VERSION "HINBNNNYYNNNYYNNNNNNNNNNNNYNNNYYYNNYNNNNNN/4//%%/4/'%**4NNN///"

NS_ :

BS_:

BU_: VirtualNMTMaster Master_ID1 I_O_Device_2_ID11 I_O_Device_1_ID10

BO_ 1418 SSDO_010: 8 I_O_Device_1_ID10
 SG_ Write_Output_32_Bit16_6320_10 m16 : 32|32@1+ (1,0) [0|4294967295] "" Vector__XXX
 SG_ Write_Output_32_Bit15_6320_0F m15 : 32|32@1+ (1,0) [0|4294967295] "" Vector__XXX
 SG_ Write_Output_32_Bit14_6320_0E m14 : 32|32@1+ (1,0) [0|4294967295] "" Vector__XXX
 SG_ Write_Output_32_Bit13_6320_0D m13 : 32|32@1+ (1,0) [0|4294967295] "" Vector__XXX
 SG_ Write_Output_32_Bit12_6320_0C m12 : 32|32@1+ (1,0) [0|4294967295] "" Vector__XXX
 SG_ Write_Output_32_Bit11_6320_0B m11 : 32|32@1+ (1,0) [0|4294967295] "" Vector__XXX
 SG_ Write_Output_32_Bit10_6320_0A m10 : 32|32@1+ (1,0) [0|4294967295] "" Vector__XXX
 SG_ Write_Output_32_Bit9_6320_09 m9 : 32|32@1+ (1,0) [0|4294967295] "" Vector__XXX
 SG_ Write_Output_32_Bit8_6320_08 m8 : 32|32@1+ (1,0) [0|4294967295] "" Vector__XXX
 SG_ Write_Output_32_Bit7_6320_07 m7 : 32|32@1+ (1,0) [0|4294967295] "" Vector__XXX
 SG_ Write_Output_32_Bit6_6320_06 m6 : 32|32@1+ (1,0) [0|4294967295] "" Vector__XXX
 SG_ Write_Output_32_Bit5_6320_05 m5 : 32|32@1+ (1,0) [0|4294967295] "" Vector__XXX
 SG_ Write_Output_32_Bit4_6320_04 m4 : 32|32@1+ (1,0) [0|4294967295] "" Vector__XXX
 SG_ Write_Output_32_Bit3_6320_03 m3 : 32|32@1+ (1,0) [0|4294967295] "" Vector__XXX
 SG_ Write_Output_32_Bit2_6320_02 m2 : 32|32@1+ (1,0) [0|4294967295] "" Vector__XXX
 SG_ Write_Output_32_Bit1_6320_01 m1 : 32|32@1+ (1,0) [0|4294967295] "" Vector__XXX
 SG_ NrOfObjects_6320_00 m0 : 32|8@1+ (1,0) [0|255] "" Vector__XXX
 SG_ SubIndex_6320 m25376M : 24|8@1+ (1,0) [0|16] "" Vector__XXX
 SG_ Write_Output_16_Bit16_6300_10 m16 : 32|16@1+ (1,0) [0|65535] "" Vector__XXX
 SG_ Write_Output_16_Bit15_6300_0F m15 : 32|16@1+ (1,0) [0|65535] "" Vector__XXX
 SG_ Write_Output_16_Bit14_6300_0E m14 : 32|16@1+ (1,0) [0|65535] "" Vector__XXX
 SG_ Write_Output_16_Bit13_6300_0D m13 : 32|16@1+ (1,0) [0|65535] "" Vector__XXX
 SG_ Write_Output_16_Bit12_6300_0C m12 : 32|16@1+ (1,0) [0|65535] "" Vector__XXX
 SG_ Write_Output_16_Bit11_6300_0B m11 : 32|16@1+ (1,0) [0|65535] "" Vector__XXX
 SG_ Write_Output_16_Bit10_6300_0A m10 : 32|16@1+ (1,0) [0|65535] "" Vector__XXX
 SG_ Write_Output_16_Bit9_6300_09 m9 : 32|16@1+ (1,0) [0|65535] "" Vector__XXX
 SG_ Write_Output_16_Bit8_6300_08 m8 : 32|16@1+ (1,0) [0|65535] "" Vector__XXX
 SG_ Write_Output_16_Bit7_6300_07 m7 : 32|16@1+ (1,0) [0|65535] "" Vector__XXX
 SG_ Write_Output_16_Bit6_6300_06 m6 : 32|16@1+ (1,0) [0|65535] "" Vector__XXX
 SG_ Write_Output_16_Bit5_6300_05 m5 : 32|16@1+ (1,0) [0|65535] "" Vector__XXX
 SG_ Write_Output_16_Bit4_6300_04 m4 : 32|16@1+ (1,0) [0|65535] "" Vector__XXX
 SG_ Write_Output_16_Bit3_6300_03 m3 : 32|16@1+ (1,0) [0|65535] "" Vector__XXX
 SG_ Write_Output_16_Bit2_6300_02 m2 : 32|16@1+ (1,0) [0|65535] "" Vector__XXX
 SG_ Write_Output_16_Bit1_6300_01 m1 : 32|16@1+ (1,0) [0|65535] "" Vector__XXX
 SG_ NrOfObjects_6300_00 m0 : 32|8@1+ (1,0) [0|255] "" Vector__XXX
 SG_ SubIndex_6300 m25344M : 24|8@1+ (1,0) [0|16] "" Vector__XXX
 SG_ Write_Output_1_Bit64_6220_40 m64 : 32|1@1+ (1,0) [0|1] "" Vector__XXX
 SG_ Write_Output_1_Bit63_6220_3F m63 : 32|1@1+ (1,0) [0|1] "" Vector__XXX
 SG_ Write_Output_1_Bit62_6220_3E m62 : 32|1@1+ (1,0) [0|1] "" Vector__XXX
 SG_ Write_Output_1_Bit61_6220_3D m61 : 32|1@1+ (1,0) [0|1] "" Vector__XXX
 SG_ Write_Output_1_Bit60_6220_3C m60 : 32|1@1+ (1,0) [0|1] "" Vector__XXX
 SG_ Write_Output_1_Bit59_6220_3B m59 : 32|1@1+ (1,0) [0|1] "" Vector__XXX
 SG_ Write_Output_1_Bit58_6220_3A m58 : 32|1@1+ (1,0) [0|1] "" Vector__XXX
 SG_ Write_Output_1_Bit57_6220_39 m57 : 32|1@1+ (1,0) [0|1] "" Vector__XXX
 SG_ Write_Output_1_Bit56_6220_38 m56 : 32|1@1+ (1,0) [0|1] "" Vector__XXX
 SG_ Write_Output_1_Bit55_6220_37 m55 : 32|1@1+ (1,0) [0|1] "" Vector__XXX
 SG_ Write_Output_1_Bit54_6220_36 m54 : 32|1@1+ (1,0) [0|1] "" Vector__XXX
 SG_ Write_Output_1_Bit53_6220_35 m53 : 32|1@1+ (1,0) [0|1] "" Vector__XXX
 SG_ Write_Output_1_Bit52_6220_34 m52 : 32|1@1+ (1,0) [0|1] "" Vector__XXX
 SG_ Write_Output_1_Bit51_6220_33 m51 : 32|1@1+ (1,0) [0|1] "" Vector__XXX
 SG_ Write_Output_1_Bit50_6220_32 m50 : 32|1@1+ (1,0) [0|1] "" Vector__XXX
 SG_ Write_Output_1_Bit49_6220_31 m49 : 32|1@1+ (1,0) [0|1] "" Vector__XXX
 SG_ Write_Output_1_Bit48_6220_30 m48 : 32|1@1+ (1,0) [0|1] "" Vector__XXX
 SG_ Write_Output_1_Bit47_6220_2F m47 : 32|1@1+ (1,0) [0|1] "" Vector__XXX
 SG_ Write_Output_1_Bit46_6220_2E m46 : 32|1@1+ (1,0) [0|1] "" Vector__XXX
 SG_ Write_Output_1_Bit45_6220_2D m45 : 32|1@1+ (1,0) [0|1] "" Vector__XXX
 SG_ Write_Output_1_Bit44_6220_2C m44 : 32|1@1+ (1,0) [0|1] "" Vector__XXX
 SG_ Write_Output_1_Bit43_6220_2B m43 : 32|1@1+ (1,0) [0|1] "" Vector__XXX
 SG_ Write_Output_1_Bit42_6220_2A m42 : 32|1@1+ (1,0) [0|1] "" Vector__XXX
 SG_ Write_Output_1_Bit41_6220_29 m41 : 32|1@1+ (1,0) [0|1] "" Vector__XXX
 SG_ Write_Output_1_Bit40_6220_28 m40 : 32|1@1+ (1,0) [0|1] "" Vector__XXX
 SG_ Write_Output_1_Bit39_6220_27 m39 : 32|1@1+ (1,0) [0|1] "" Vector__XXX
 SG_ Write_Output_1_Bit38_6220_26 m38 : 32|1@1+ (1,0) [0|1] "" Vector__XXX
 SG_ Write_Output_1_Bit37_6220_25 m37 : 32|1@1+ (1,0) [0|1] "" Vector__XXX
 SG_ Write_Output_1_Bit36_6220_24 m36 : 32|1@1+ (1,0) [0|1] "" Vector__XXX
 SG_ Write_Output_1_Bit35_6220_23 m35 : 32|1@1+ (1,0) [0|1] "" Vector__XXX
 SG_ Write_Output_1_Bit34_6220_22 m34 : 32|1@1+ (1,0) [0|1] "" Vector__XXX
 SG_ Write_Output_1_Bit33_6220_21 m33 : 32|1@1+ (1,0) [0|1] "" Vector__XXX
 SG_ Write_Output_1_Bit32_6220_20 m32 : 32|1@1+ (1,0) [0|1] "" Vector__XXX
 SG_ Write_Output_1_Bit31_6220_1F m31 : 32|1@1+ (1,0) [0|1] "" Vector__XXX
 SG_ Write_Output_1_Bit30_6220_1E m30 : 32|1@1+ (1,0) [0|1] "" Vector__XXX
 SG_ Write_Output_1_Bit29_6220_1D m29 : 32|1@1+ (1,0) [0|1] "" Vector__XXX
 SG_ Write_Output_1_Bit28_6220_1C m28 : 32|1@1+ (1,0) [0|1] "" Vector__XXX
 SG_ Write_Output_1_Bit27_6220_1B m27 : 32|1@1+ (1,0) [0|1] "" Vector__XXX
 SG_ Write_Output_1_Bit26_6220_1A m26 : 32|1@1+ (1,0) [0|1] "" Vector__XXX
 SG_ Write_Output_1_Bit25_6220_19 m25 : 32|1@1+ (1,0) [0|1] "" Vector__XXX
 SG_ Write_Output_1_Bit24_6220_18 m24 : 32|1@1+ (1,0) [0|1] "" Vector__XXX
 SG_ Write_Output_1_Bit23_6220_17 m23 : 32|1@1+ (1,0) [0|1] "" Vector__XXX
 SG_ Write_Output_1_Bit22_6220_16 m22 : 32|1@1+ (1,0) [0|1] "" Vector__XXX
 SG_ Write_Output_1_Bit21_6220_15 m21 : 32|1@1+ (1,0) [0|1] "" Vector__XXX
 SG_ Write_Output_1_Bit20_6220_14 m20 : 32|1@1+ (1,0) [0|1] "" Vector__XXX
 SG_ Write_Output_1_Bit19_6220_13 m19 : 32|1@1+ (1,0) [0|1] "" Vector__XXX
 SG_ Write_Output_1_Bit18_6220_12 m18 : 32|1@1+ (1,0) [0|1] "" Vector__XXX
 SG_ Write_Output_1_Bit17_6220_11 m17 : 32|1@1+ (1,0) [0|1] "" Vector__XXX
 SG_ Write_Output_1_Bit16_6220_10 m16 : 32|1@1+ (1,0) [0|1] "" Vector__XXX
 SG_ Write_Output_1_Bit15_6220_0F m15 : 32|1@1+ (1,0) [0|1] "" Vector__XXX
 SG_ Write_Output_1_Bit14_6220_0E m14 : 32|1@1+ (1,0) [0|1] "" Vector__XXX
 SG_ Write_Output_1_Bit13_6220_0D m13 : 32|1@1+ (1,0) [0|1] "" Vector__XXX
 SG_ Write_Output_1_Bit12_6220_0C m12 : 32|1@1+ (1,0) [0|1] "" Vector__XXX
 SG_ Write_Output_1_Bit11_6220_0B m11 : 32|1@1+ (1,0) [0|1] "" Vector__XXX
 SG_ Write_Output_1_Bit10_6220_0A m10 : 32|1@1+ (1,0) [0|1] "" Vector__XXX
 SG_ Write_Output_1_Bit9_6220_09 m9 : 32|1@1+ (1,0) [0|1] "" Vector__XXX
 SG_ Write_Output_1_Bit8_6220_08 m8 : 32|1@1+ (1,0) [0|1] "" Vector__XXX
 SG_ Write_Output_1_Bit7_6220_07 m7 : 32|1@1+ (1,0) [0|1] "" Vector__XXX
 SG_ Write_Output_1_Bit6_6220_06 m6 : 32|1@1+ (1,0) [0|1] "" Vector__XXX
 SG_ Write_Output_1_Bit5_6220_05 m5 : 32|1@1+ (1,0) [0|1] "" Vector__XXX
 SG_ Write_Output_1_Bit4_6220_04 m4 : 32|1@1+ (1,0) [0|1] "" Vector__XXX
 SG_ Write_Output_1_Bit3_6220_03 m3 : 32|1@1+ (1,0) [0|1] "" Vector__XXX
 SG_ Write_Output_1_Bit2_6220_02 m2 : 32|1@1+ (1,0) [0|1] "" Vector__XXX
 SG_ Write_Output_1_Bit1_6220_01 m1 : 32|1@1+ (1,0) [0|1] "" Vector__XXX
 SG_ NrOfObjects_6220_00 m0 : 32|8@1+ (1,0) [0|255] "" Vector__XXX
 SG_ SubIndex_6220 m25120M : 24|8@1+ (1,0) [0|64] "" Vector__XXX
 SG_ Write_Output_8_Bit16_6200_10 m16 : 32|8@1+ (1,0) [0|255] "" Vector__XXX
 SG_ Write_Output_8_Bit15_6200_0F m15 : 32|8@1+ (1,0) [0|255] "" Vector__XXX
 SG_ Write_Output_8_Bit14_6200_0E m14 : 32|8@1+ (1,0) [0|255] "" Vector__XXX
 SG_ Write_Output_8_Bit13_6200_0D m13 : 32|8@1+ (1,0) [0|255] "" Vector__XXX
 SG_ Write_Output_8_Bit12_6200_0C m12 : 32|8@1+ (1,0) [0|255] "" Vector__XXX
 SG_ Write_Output_8_Bit11_6200_0B m11 : 32|8@1+ (1,0) [0|255] "" Vector__XXX
 SG_ Write_Output_8_Bit10_6200_0A m10 : 32|8@1+ (1,0) [0|255] "" Vector__XXX
 SG_ Write_Output_8_Bit9_6200_09 m9 : 32|8@1+ (1,0) [0|255] "" Vector__XXX
 SG_ Write_Output_8_Bit8_6200_08 m8 : 32|8@1+ (1,0) [0|255] "" Vector__XXX
 SG_ Write_Output_8_Bit7_6200_07 m7 : 32|8@1+ (1,0) [0|255] "" Vector__XXX
 SG_ Write_Output_8_Bit6_6200_06 m6 : 32|8@1+ (1,0) [0|255] "" Vector__XXX
 SG_ Write_Output_8_Bit5_6200_05 m5 : 32|8@1+ (1,0) [0|255] "" Vector__XXX
 SG_ Write_Output_8_Bit4_6200_04 m4 : 32|8@1+ (1,0) [0|255] "" Vector__XXX
 SG_ Write_Output_8_Bit3_6200_03 m3 : 32|8@1+ (1,0) [0|255] "" Vector__XXX
 SG_ Write_Output_8_Bit2_6200_02 m2 : 32|8@1+ (1,0) [0|255] "" Vector__XXX
 SG_ Write_Output_8_Bit1_6200_01 m1 : 32|8@1+ (1,0) [0|255] "" Vector__XXX
 SG_ NrOfObjects_6200_00 m0 : 32|8@1+ (1,0) [0|255] "" Vector__XXX
 SG_ SubIndex_6200 m25088M : 24|8@1+ (1,0) [0|16] "" Vector__XXX
 SG_ Read_Input_32_Bit16_6120_10 m16 : 32|32@1+ (1,0) [0|4294967295] "" Vector__XXX
 SG_ Read_Input_32_Bit15_6120_0F m15 : 32|32@1+ (1,0) [0|4294967295] "" Vector__XXX
 SG_ Read_Input_32_Bit14_6120_0E m14 : 32|32@1+ (1,0) [0|4294967295] "" Vector__XXX
 SG_ Read_Input_32_Bit13_6120_0D m13 : 32|32@1+ (1,0) [0|4294967295] "" Vector__XXX
 SG_ Read_Input_32_Bit12_6120_0C m12 : 32|32@1+ (1,0) [0|4294967295] "" Vector__XXX
 SG_ Read_Input_32_Bit11_6120_0B m11 : 32|32@1+ (1,0) [0|4294967295] "" Vector__XXX
 SG_ Read_Input_32_Bit10_6120_0A m10 : 32|32@1+ (1,0) [0|4294967295] "" Vector__XXX
 SG_ Read_Input_32_Bit9_6120_09 m9 : 32|32@1+ (1,0) [0|4294967295] "" Vector__XXX
 SG_ Read_Input_32_Bit8_6120_08 m8 : 32|32@1+ (1,0) [0|4294967295] "" Vector__XXX
 SG_ Read_Input_32_Bit7_6120_07 m7 : 32|32@1+ (1,0) [0|4294967295] "" Vector__XXX
 SG_ Read_Input_32_Bit6_6120_06 m6 : 32|32@1+ (1,0) [0|4294967295] "" Vector__XXX
 SG_ Read_Input_32_Bit5_6120_05 m5 : 32|32@1+ (1,0) [0|4294967295] "" Vector__XXX
 SG_ Read_Input_32_Bit4_6120_04 m4 : 32|32@1+ (1,0) [0|4294967295] "" Vector__XXX
 SG_ Read_Input_32_Bit3_6120_03 m3 : 32|32@1+ (1,0) [0|4294967295] "" Vector__XXX
 SG_ Read_Input_32_Bit2_6120_02 m2 : 32|32@1+ (1,0) [0|4294967295] "" Vector__XXX
 SG_ Read_Input_32_Bit1_6120_01 m1 : 32|32@1+ (1,0) [0|4294967295] "" Vector__XXX
 SG_ NrOfObjects_6120_00 m0 : 32|8@1+ (1,0) [0|255] "" Vector__XXX
 SG_ SubIndex_6120 m24864M : 24|8@1+ (1,0) [0|16] "" Vector__XXX
 SG_ Read_Input_16_Bit16_6100_10 m16 : 32|16@1+ (1,0) [0|65535] "" Vector__XXX
 SG_ Read_Input_16_Bit15_6100_0F m15 : 32|16@1+ (1,0) [0|65535] "" Vector__XXX
 SG_ Read_Input_16_Bit14_6100_0E m14 : 32|16@1+ (1,0) [0|65535] "" Vector__XXX
 SG_ Read_Input_16_Bit13_6100_0D m13 : 32|16@1+ (1,0) [0|65535] "" Vector__XXX
 SG_ Read_Input_16_Bit12_6100_0C m12 : 32|16@1+ (1,0) [0|65535] "" Vector__XXX
 SG_ Read_Input_16_Bit11_6100_0B m11 : 32|16@1+ (1,0) [0|65535] "" Vector__XXX
 SG_ Read_Input_16_Bit10_6100_0A m10 : 32|16@1+ (1,0) [0|65535] "" Vector__XXX
 SG_ Read_Input_16_Bit9_6100_09 m9 : 32|16@1+ (1,0) [0|65535] "" Vector__XXX
 SG_ Read_Input_16_Bit8_6100_08 m8 : 32|16@1+ (1,0) [0|65535] "" Vector__XXX
 SG_ Read_Input_16_Bit7_6100_07 m7 : 32|16@1+ (1,0) [0|65535] "" Vector__XXX
 SG_ Read_Input_16_Bit6_6100_06 m6 : 32|16@1+ (1,0) [0|65535] "" Vector__XXX
 SG_ Read_Input_16_Bit5_6100_05 m5 : 32|16@1+ (1,0) [0|65535] "" Vector__XXX
 SG_ Read_Input_16_Bit4_6100_04 m4 : 32|16@1+ (1,0) [0|65535] "" Vector__XXX
 SG_ Read_Input_16_Bit3_6100_03 m3 : 32|16@1+ (1,0) [0|65535] "" Vector__XXX
 SG_ Read_Input_16_Bit2_6100_02 m2 : 32|16@1+ (1,0) [0|65535] "" Vector__XXX
 SG_ Read_Input_16_Bit1_6100_01 m1 : 32|16@1+ (1,0) [0|65535] "" Vector__XXX
 SG_ NrOfObjects_6100_00 m0 : 32|8@1+ (1,0) [0|255] "" Vector__XXX
 SG_ SubIndex_6100 m24832M : 24|8@1+ (1,0) [0|16] "" Vector__XXX
 SG_ Read_Input_1_Bit64_6020_40 m64 : 32|1@1+ (1,0) [0|1] "" Vector__XXX
 SG_ Read_Input_1_Bit63_6020_3F m63 : 32|1@1+ (1,0) [0|1] "" Vector__XXX
 SG_ Read_Input_1_Bit62_6020_3E m62 : 32|1@1+ (1,0) [0|1] "" Vector__XXX
 SG_ Read_Input_1_Bit61_6020_3D m61 : 32|1@1+ (1,0) [0|1] "" Vector__XXX
 SG_ Read_Input_1_Bit60_6020_3C m60 : 32|1@1+ (1,0) [0|1] "" Vector__XXX
 SG_ Read_Input_1_Bit59_6020_3B m59 : 32|1@1+ (1,0) [0|1] "" Vector__XXX
 SG_ Read_Input_1_Bit58_6020_3A m58 : 32|1@1+ (1,0) [0|1] "" Vector__XXX
 SG_ Read_Input_1_Bit57_6020_39 m57 : 32|1@1+ (1,0) [0|1] "" Vector__XXX
 SG_ Read_Input_1_Bit56_6020_38 m56 : 32|1@1+ (1,0) [0|1] "" Vector__XXX
 SG_ Read_Input_1_Bit55_6020_37 m55 : 32|1@1+ (1,0) [0|1] "" Vector__XXX
 SG_ Read_Input_1_Bit54_6020_36 m54 : 32|1@1+ (1,0) [0|1] "" Vector__XXX
 SG_ Read_Input_1_Bit53_6020_35 m53 : 32|1@1+ (1,0) [0|1] "" Vector__XXX
 SG_ Read_Input_1_Bit52_6020_34 m52 : 32|1@1+ (1,0) [0|1] "" Vector__XXX
 SG_ Read_Input_1_Bit51_6020_33 m51 : 32|1@1+ (1,0) [0|1] "" Vector__XXX
 SG_ Read_Input_1_Bit50_6020_32 m50 : 32|1@1+ (1,0) [0|1] "" Vector__XXX
 SG_ Read_Input_1_Bit49_6020_31 m49 : 32|1@1+ (1,0) [0|1] "" Vector__XXX
 SG_ Read_Input_1_Bit48_6020_30 m48 : 32|1@1+ (1,0) [0|1] "" Vector__XXX
 SG_ Read_Input_1_Bit47_6020_2F m47 : 32|1@1+ (1,0) [0|1] "" Vector__XXX
 SG_ Read_Input_1_Bit46_6020_2E m46 : 32|1@1+ (1,0) [0|1] "" Vector__XXX
 SG_ Read_Input_1_Bit45_6020_2D m45 : 32|1@1+ (1,0) [0|1] "" Vector__XXX
 SG_ Read_Input_1_Bit44_6020_2C m44 : 32|1@1+ (1,0) [0|1] "" Vector__XXX
 SG_ Read_Input_1_Bit43_6020_2B m43 : 32|1@1+ (1,0) [0|1] "" Vector__XXX
 SG_ Read_Input_1_Bit42_6020_2A m42 : 32|1@1+ (1,0) [0|1] "" Vector__XXX
 SG_ Read_Input_1_Bit41_6020_29 m41 : 32|1@1+ (1,0) [0|1] "" Vector__XXX
 SG_ Read_Input_1_Bit40_6020_28 m40 : 32|1@1+ (1,0) [0|1] "" Vector__XXX
 SG_ Read_Input_1_Bit39_6020_27 m39 : 32|1@1+ (1,0) [0|1] "" Vector__XXX
 SG_ Read_Input_1_Bit38_6020_26 m38 : 32|1@1+ (1,0) [0|1] "" Vector__XXX
 SG_ Read_Input_1_Bit37_6020_25 m37 : 32|1@1+ (1,0) [0|1] "" Vector__XXX
 SG_ Read_Input_1_Bit36_6020_24 m36 : 32|1@1+ (1,0) [0|1] "" Vector__XXX
 SG_ Read_Input_1_Bit35_6020_23 m35 : 32|1@1+ (1,0) [0|1] "" Vector__XXX
 SG_ Read_Input_1_Bit34_6020_22 m34 : 32|1@1+ (1,0) [0|1] "" Vector__XXX
 SG_ Read_Input_1_Bit33_6020_21 m33 : 32|1@1+ (1,0) [0|1] "" Vector__XXX
 SG_ Read_Input_1_Bit32_6020_20 m32 : 32|1@1+ (1,0) [0|1] "" Vector__XXX
 SG_ Read_Input_1_Bit31_6020_1F m31 : 32|1@1+ (1,0) [0|1] "" Vector__XXX
 SG_ Read_Input_1_Bit30_6020_1E m30 : 32|1@1+ (1,0) [0|1] "" Vector__XXX
 SG_ Read_Input_1_Bit29_6020_1D m29 : 32|1@1+ (1,0) [0|1] "" Vector__XXX
 SG_ Read_Input_1_Bit28_6020_1C m28 : 32|1@1+ (1,0) [0|1] "" Vector__XXX
 SG_ Read_Input_1_Bit27_6020_1B m27 : 32|1@1+ (1,0) [0|1] "" Vector__XXX
 SG_ Read_Input_1_Bit26_6020_1A m26 : 32|1@1+ (1,0) [0|1] "" Vector__XXX
 SG_ Read_Input_1_Bit25_6020_19 m25 : 32|1@1+ (1,0) [0|1] "" Vector__XXX
 SG_ Read_Input_1_Bit24_6020_18 m24 : 32|1@1+ (1,0) [0|1] "" Vector__XXX
 SG_ Read_Input_1_Bit23_6020_17 m23 : 32|1@1+ (1,0) [0|1] "" Vector__XXX
 SG_ Read_Input_1_Bit22_6020_16 m22 : 32|1@1+ (1,0) [0|1] "" Vector__XXX
 SG_ Read_Input_1_Bit21_6020_15 m21 : 32|1@1+ (1,0) [0|1] "" Vector__XXX
 SG_ Read_Input_1_Bit20_6020_14 m20 : 32|1@1+ (1,0) [0|1] "" Vector__XXX
 SG_ Read_Input_1_Bit19_6020_13 m19 : 32|1@1+ (1,0) [0|1] "" Vector__XXX
 SG_ Read_Input_1_Bit18_6020_12 m18 : 32|1@1+ (1,0) [0|1] "" Vector__XXX
 SG_ Read_Input_1_Bit17_6020_11 m17 : 32|1@1+ (1,0) [0|1] "" Vector__XXX
 SG_ Read_Input_1_Bit16_6020_10 m16 : 32|1@1+ (1,0) [0|1] "" Vector__XXX
 SG_ Read_Input_1_Bit15_6020_0F m15 : 32|1@1+ (1,0) [0|1] "" Vector__XXX
 SG_ Read_Input_1_Bit14_6020_0E m14 : 32|1@1+ (1,0) [0|1] "" Vector__XXX
 SG_ Read_Input_1_Bit13_6020_0D m13 : 32|1@1+ (1,0) [0|1] "" Vector__XXX
 SG_ Read_Input_1_Bit12_6020_0C m12 : 32|1@1+ (1,0) [0|1] "" Vector__XXX
 SG_ Read_Input_1_Bit11_6020_0B m11 : 32|1@1+ (1,0) [0|1] "" Vector__XXX
 SG_ Read_Input_1_Bit10_6020_0A m10 : 32|1@1+ (1,0) [0|1] "" Vector__XXX
 SG_ Read_Input_1_Bit9_6020_09 m9 : 32|1@1+ (1,0) [0|1] "" Vector__XXX
 SG_ Read_Input_1_Bit8_6020_08 m8 : 32|1@1+ (1,0) [0|1] "" Vector__XXX
 SG_ Read_Input_1_Bit7_6020_07 m7 : 32|1@1+ (1,0) [0|1] "" Vector__XXX
 SG_ Read_Input_1_Bit6_6020_06 m6 : 32|1@1+ (1,0) [0|1] "" Vector__XXX
 SG_ Read_Input_1_Bit5_6020_05 m5 : 32|1@1+ (1,0) [0|1] "" Vector__XXX
 SG_ Read_Input_1_Bit4_6020_04 m4 : 32|1@1+ (1,0) [0|1] "" Vector__XXX
 SG_ Read_Input_1_Bit3_6020_03 m3 : 32|1@1+ (1,0) [0|1] "" Vector__XXX
 SG_ Read_Input_1_Bit2_6020_02 m2 : 32|1@1+ (1,0) [0|1] "" Vector__XXX
 SG_ Read_Input_1_Bit1_6020_01 m1 : 32|1@1+ (1,0) [0|1] "" Vector__XXX
 SG_ NrOfObjects_6020_00 m0 : 32|8@1+ (1,0) [0|255] "" Vector__XXX
 SG_ SubIndex_6020 m24608M : 24|8@1+ (1,0) [0|64] "" Vector__XXX
 SG_ Read_Input_8_Bit16_6000_10 m16 : 32|8@1+ (1,0) [0|255] "" Vector__XXX
 SG_ Read_Input_8_Bit15_6000_0F m15 : 32|8@1+ (1,0) [0|255] "" Vector__XXX
 SG_ Read_Input_8_Bit14_6000_0E m14 : 32|8@1+ (1,0) [0|255] "" Vector__XXX
 SG_ Read_Input_8_Bit13_6000_0D m13 : 32|8@1+ (1,0) [0|255] "" Vector__XXX
 SG_ Read_Input_8_Bit12_6000_0C m12 : 32|8@1+ (1,0) [0|255] "" Vector__XXX
 SG_ Read_Input_8_Bit11_6000_0B m11 : 32|8@1+ (1,0) [0|255] "" Vector__XXX
 SG_ Read_Input_8_Bit10_6000_0A m10 : 32|8@1+ (1,0) [0|255] "" Vector__XXX
 SG_ Read_Input_8_Bit9_6000_09 m9 : 32|8@1+ (1,0) [0|255] "" Vector__XXX
 SG_ Read_Input_8_Bit8_6000_08 m8 : 32|8@1+ (1,0) [0|255] "" Vector__XXX
 SG_ Read_Input_8_Bit7_6000_07 m7 : 32|8@1+ (1,0) [0|255] "" Vector__XXX
 SG_ Read_Input_8_Bit6_6000_06 m6 : 32|8@1+ (1,0) [0|255] "" Vector__XXX
 SG_ Read_Input_8_Bit5_6000_05 m5 : 32|8@1+ (1,0) [0|255] "" Vector__XXX
 SG_ Read_Input_8_Bit4_6000_04 m4 : 32|8@1+ (1,0) [0|255] "" Vector__XXX
 SG_ Read_Input_8_Bit3_6000_03 m3 : 32|8@1+ (1,0) [0|255] "" Vector__XXX
 SG_ Read_Input_8_Bit2_6000_02 m2 : 32|8@1+ (1,0) [0|255] "" Vector__XXX
 SG_ Read_Input_8_Bit1_6000_01 m1 : 32|8@1+ (1,0) [0|255] "" Vector__XXX
 SG_ NrOfObjects_6000_00 m0 : 32|8@1+ (1,0) [0|255] "" Vector__XXX
 SG_ SubIndex_6000 m24576M : 24|8@1+ (1,0) [0|16] "" Vector__XXX
 SG_ NrOfObjects_2300_00 m0 : 32|8@1+ (1,0) [0|255] "" Vector__XXX
 SG_ SubIndex_2300 m8960M : 24|8@1+ (1,0) [0|4] "" Vector__XXX
 SG_ NrOfObjects_2200_00 m0 : 32|8@1+ (1,0) [0|255] "" Vector__XXX
 SG_ SubIndex_2200 m8704M : 24|8@1+ (1,0) [0|4] "" Vector__XXX
 SG_ NrOfMappedObjects_1A03_00 m0 : 32|8@1+ (1,0) [0|64] "" Vector__XXX
 SG_ SubIndex_1A03 m6659M : 24|8@1+ (1,0) [0|0] "" Vector__XXX
 SG_ NrOfMappedObjects_1A02_00 m0 : 32|8@1+ (1,0) [0|64] "" Vector__XXX
 SG_ SubIndex_1A02 m6658M : 24|8@1+ (1,0) [0|0] "" Vector__XXX
 SG_ mappedObj2_1A01_02 m2 : 32|32@1+ (1,0) [0|4294967295] "" Vector__XXX
 SG_ mappedObj1_1A01_01 m1 : 32|32@1+ (1,0) [0|4294967295] "" Vector__XXX
 SG_ NrOfMappedObjects_1A01_00 m0 : 32|8@1+ (1,0) [0|64] "" Vector__XXX
 SG_ SubIndex_1A01 m6657M : 24|8@1+ (1,0) [0|2] "" Vector__XXX
 SG_ mappedObj2_1A00_02 m2 : 32|32@1+ (1,0) [0|4294967295] "" Vector__XXX
 SG_ mappedObj1_1A00_01 m1 : 32|32@1+ (1,0) [0|4294967295] "" Vector__XXX
 SG_ NrOfMappedObjects_1A00_00 m0 : 32|8@1+ (1,0) [0|64] "" Vector__XXX
 SG_ SubIndex_1A00 m6656M : 24|8@1+ (1,0) [0|2] "" Vector__XXX
 SG_ EventTimer_1803_05 m5 : 32|16@1+ (1,0) [0|65535] "" Vector__XXX
 SG_ TransmissionType_1803_02 m2 : 32|8@1+ (1,0) [0|255] "" Vector__XXX
 SG_ COB_ID_1803_01 m1 : 32|32@1+ (1,0) [128|4294967295] "" Vector__XXX
 SG_ Highest_sub_index_supported_0021 m0 : 32|8@1+ (1,0) [2|5] "" Vector__XXX
 SG_ SubIndex_1803 m6147M : 24|8@1+ (1,0) [0|5] "" Vector__XXX
 SG_ EventTimer_1802_05 m5 : 32|16@1+ (1,0) [0|65535] "" Vector__XXX
 SG_ TransmissionType_1802_02 m2 : 32|8@1+ (1,0) [0|255] "" Vector__XXX
 SG_ COB_ID_1802_01 m1 : 32|32@1+ (1,0) [128|4294967295] "" Vector__XXX
 SG_ Highest_sub_index_supported_0022 m0 : 32|8@1+ (1,0) [2|5] "" Vector__XXX
 SG_ SubIndex_1802 m6146M : 24|8@1+ (1,0) [0|5] "" Vector__XXX
 SG_ EventTimer_1801_05 m5 : 32|16@1+ (1,0) [0|65535] "" Vector__XXX
 SG_ TransmissionType_1801_02 m2 : 32|8@1+ (1,0) [0|255] "" Vector__XXX
 SG_ COB_ID_1801_01 m1 : 32|32@1+ (1,0) [128|4294967295] "" Vector__XXX
 SG_ Highest_sub_index_supported_0023 m0 : 32|8@1+ (1,0) [2|5] "" Vector__XXX
 SG_ SubIndex_1801 m6145M : 24|8@1+ (1,0) [0|5] "" Vector__XXX
 SG_ EventTimer_1800_05 m5 : 32|16@1+ (1,0) [0|65535] "" Vector__XXX
 SG_ TransmissionType_1800_02 m2 : 32|8@1+ (1,0) [0|255] "" Vector__XXX
 SG_ COB_ID_1800_01 m1 : 32|32@1+ (1,0) [128|4294967295] "" Vector__XXX
 SG_ Highest_sub_index_supported_0024 m0 : 32|8@1+ (1,0) [2|5] "" Vector__XXX
 SG_ SubIndex_1800 m6144M : 24|8@1+ (1,0) [0|5] "" Vector__XXX
 SG_ NrOfMappedObjects_1603_00 m0 : 32|8@1+ (1,0) [0|64] "" Vector__XXX
 SG_ SubIndex_1603 m5635M : 24|8@1+ (1,0) [0|0] "" Vector__XXX
 SG_ NrOfMappedObjects_1602_00 m0 : 32|8@1+ (1,0) [0|64] "" Vector__XXX
 SG_ SubIndex_1602 m5634M : 24|8@1+ (1,0) [0|0] "" Vector__XXX
 SG_ NrOfMappedObjects_1601_00 m0 : 32|8@1+ (1,0) [0|64] "" Vector__XXX
 SG_ SubIndex_1601 m5633M : 24|8@1+ (1,0) [0|0] "" Vector__XXX
 SG_ NrOfMappedObjects_1600_00 m0 : 32|8@1+ (1,0) [0|64] "" Vector__XXX
 SG_ SubIndex_1600 m5632M : 24|8@1+ (1,0) [0|0] "" Vector__XXX
 SG_ TransmissionType_1403_02 m2 : 32|8@1+ (1,0) [0|255] "" Vector__XXX
 SG_ COB_ID_1403_01 m1 : 32|32@1+ (1,0) [128|4294967295] "" Vector__XXX
 SG_ Highest_sub_index_supported_0025 m0 : 32|8@1+ (1,0) [2|5] "" Vector__XXX
 SG_ SubIndex_1403 m5123M : 24|8@1+ (1,0) [0|2] "" Vector__XXX
 SG_ TransmissionType_1402_02 m2 : 32|8@1+ (1,0) [0|255] "" Vector__XXX
 SG_ COB_ID_1402_01 m1 : 32|32@1+ (1,0) [128|4294967295] "" Vector__XXX
 SG_ Highest_sub_index_supported_0026 m0 : 32|8@1+ (1,0) [2|5] "" Vector__XXX
 SG_ SubIndex_1402 m5122M : 24|8@1+ (1,0) [0|2] "" Vector__XXX
 SG_ TransmissionType_1401_02 m2 : 32|8@1+ (1,0) [0|255] "" Vector__XXX
 SG_ COB_ID_1401_01 m1 : 32|32@1+ (1,0) [128|4294967295] "" Vector__XXX
 SG_ Highest_sub_index_supported_0027 m0 : 32|8@1+ (1,0) [2|5] "" Vector__XXX
 SG_ SubIndex_1401 m5121M : 24|8@1+ (1,0) [0|2] "" Vector__XXX
 SG_ TransmissionType_1400_02 m2 : 32|8@1+ (1,0) [0|255] "" Vector__XXX
 SG_ COB_ID_1400_01 m1 : 32|32@1+ (1,0) [128|4294967295] "" Vector__XXX
 SG_ Highest_sub_index_supported_0028 m0 : 32|8@1+ (1,0) [2|5] "" Vector__XXX
 SG_ SubIndex_1400 m5120M : 24|8@1+ (1,0) [0|2] "" Vector__XXX
 SG_ Serial_number_1018_04 m4 : 32|32@1+ (1,0) [0|4294967295] "" Vector__XXX
 SG_ Revision_number_1018_03 m3 : 32|32@1+ (1,0) [0|4294967295] "" Vector__XXX
 SG_ Product_Code_1018_02 m2 : 32|32@1+ (1,0) [0|4294967295] "" Vector__XXX
 SG_ Vendor_Id_1018_01 m1 : 32|32@1+ (1,0) [0|4294967295] "" Vector__XXX
 SG_ Highest_sub_index_supported_0029 m0 : 32|8@1+ (1,0) [1|4] "" Vector__XXX
 SG_ SubIndex_1018 m4120M : 24|8@1+ (1,0) [0|4] "" Vector__XXX
 SG_ Producer_Heartbeat_Time_1017 m0 : 32|16@1+ (1,0) [0|65535] "" Vector__XXX
 SG_ SubIndex_1017 m4119M : 24|8@1+ (1,0) [0|0] "" Vector__XXX
 SG_ Consumer_Heartbeat_Time16_1_0003 m16 : 32|32@1+ (1,0) [0|4294967295] "" Vector__XXX
 SG_ Consumer_Heartbeat_Time15_1_0003 m15 : 32|32@1+ (1,0) [0|4294967295] "" Vector__XXX
 SG_ Consumer_Heartbeat_Time14_1_0003 m14 : 32|32@1+ (1,0) [0|4294967295] "" Vector__XXX
 SG_ Consumer_Heartbeat_Time13_1_0003 m13 : 32|32@1+ (1,0) [0|4294967295] "" Vector__XXX
 SG_ Consumer_Heartbeat_Time12_1_0003 m12 : 32|32@1+ (1,0) [0|4294967295] "" Vector__XXX
 SG_ Consumer_Heartbeat_Time11_1_0003 m11 : 32|32@1+ (1,0) [0|4294967295] "" Vector__XXX
 SG_ Consumer_Heartbeat_Time10_1_0003 m10 : 32|32@1+ (1,0) [0|4294967295] "" Vector__XXX
 SG_ Consumer_Heartbeat_Time9_1016_09 m9 : 32|32@1+ (1,0) [0|4294967295] "" Vector__XXX
 SG_ Consumer_Heartbeat_Time8_1016_08 m8 : 32|32@1+ (1,0) [0|4294967295] "" Vector__XXX
 SG_ Consumer_Heartbeat_Time7_1016_07 m7 : 32|32@1+ (1,0) [0|4294967295] "" Vector__XXX
 SG_ Consumer_Heartbeat_Time6_1016_06 m6 : 32|32@1+ (1,0) [0|4294967295] "" Vector__XXX
 SG_ Consumer_Heartbeat_Time5_1016_05 m5 : 32|32@1+ (1,0) [0|4294967295] "" Vector__XXX
 SG_ Consumer_Heartbeat_Time4_1016_04 m4 : 32|32@1+ (1,0) [0|4294967295] "" Vector__XXX
 SG_ Consumer_Heartbeat_Time3_1016_03 m3 : 32|32@1+ (1,0) [0|4294967295] "" Vector__XXX
 SG_ Consumer_Heartbeat_Time2_1016_02 m2 : 32|32@1+ (1,0) [0|4294967295] "" Vector__XXX
 SG_ Consumer_Heartbeat_Time1_1016_01 m1 : 32|32@1+ (1,0) [0|4294967295] "" Vector__XXX
 SG_ NrOfObjects_1016_00 m0 : 32|8@1+ (1,0) [0|255] "" Vector__XXX
 SG_ SubIndex_1016 m4118M : 24|8@1+ (1,0) [0|16] "" Vector__XXX
 SG_ COB_ID_EMCY_1014 m0 : 32|32@1+ (1,0) [128|3221225471] "" Vector__XXX
 SG_ SubIndex_1014 m4116M : 24|8@1+ (1,0) [0|0] "" Vector__XXX
 SG_ Restore_all_Default_Paramet_0003 m1 : 32|32@1+ (1,0) [0|4294967295] "" Vector__XXX
 SG_ Highest_sub_index_supported_0030 m0 : 32|8@1+ (1,0) [0|255] "" Vector__XXX
 SG_ SubIndex_1011 m4113M : 24|8@1+ (1,0) [0|1] "" Vector__XXX
 SG_ Save_all_Parameters_1010_01 m1 : 32|32@1+ (1,0) [0|4294967295] "" Vector__XXX
 SG_ Highest_sub_index_supported_0031 m0 : 32|8@1+ (1,0) [0|255] "" Vector__XXX
 SG_ SubIndex_1010 m4112M : 24|8@1+ (1,0) [0|1] "" Vector__XXX
 SG_ Life_Time_Factor_100D m0 : 32|8@1+ (1,0) [0|255] "" Vector__XXX
 SG_ SubIndex_100D m4109M : 24|8@1+ (1,0) [0|0] "" Vector__XXX
 SG_ Guard_Time_100C m0 : 32|16@1+ (1,0) [0|65535] "" Vector__XXX
 SG_ SubIndex_100C m4108M : 24|8@1+ (1,0) [0|0] "" Vector__XXX
 SG_ Synchronous_Window_Length_1007 m0 : 32|32@1+ (1,0) [0|4294967295] "" Vector__XXX
 SG_ SubIndex_1007 m4103M : 24|8@1+ (1,0) [0|0] "" Vector__XXX
 SG_ Communication_Cycle_Period_1006 m0 : 32|32@1+ (1,0) [0|4294967295] "" Vector__XXX
 SG_ SubIndex_1006 m4102M : 24|8@1+ (1,0) [0|0] "" Vector__XXX
 SG_ COB_ID_SYNC_1005 m0 : 32|32@1+ (1,0) [128|4294967295] "" Vector__XXX
 SG_ SubIndex_1005 m4101M : 24|8@1+ (1,0) [0|0] "" Vector__XXX
 SG_ Standard_error_field_1003_09 m9 : 32|32@1+ (1,0) [0|4294967295] "" Vector__XXX
 SG_ Standard_error_field_1003_08 m8 : 32|32@1+ (1,0) [0|4294967295] "" Vector__XXX
 SG_ Standard_error_field_1003_07 m7 : 32|32@1+ (1,0) [0|4294967295] "" Vector__XXX
 SG_ Standard_error_field_1003_06 m6 : 32|32@1+ (1,0) [0|4294967295] "" Vector__XXX
 SG_ Standard_error_field_1003_05 m5 : 32|32@1+ (1,0) [0|4294967295] "" Vector__XXX
 SG_ Standard_error_field_1003_04 m4 : 32|32@1+ (1,0) [0|4294967295] "" Vector__XXX
 SG_ Standard_error_field_1003_03 m3 : 32|32@1+ (1,0) [0|4294967295] "" Vector__XXX
 SG_ Standard_error_field_1003_02 m2 : 32|32@1+ (1,0) [0|4294967295] "" Vector__XXX
 SG_ Standard_error_field_1003_01 m1 : 32|32@1+ (1,0) [0|4294967295] "" Vector__XXX
 SG_ Number_of_Errors_1003_00 m0 : 32|8@1+ (1,0) [0|255] "" Vector__XXX
 SG_ SubIndex_1003 m4099M : 24|8@1+ (1,0) [0|9] "" Vector__XXX
 SG_ Error_Register_1001 m0 : 32|8@1+ (1,0) [0|255] "" Vector__XXX
 SG_ SubIndex_1001 m4097M : 24|8@1+ (1,0) [0|0] "" Vector__XXX
 SG_ Device_Type_1000 m0 : 32|32@1+ (1,0) [0|4294967295] "" Vector__XXX
 SG_ SubIndex_1000 m4096M : 24|8@1+ (1,0) [0|0] "" Vector__XXX
 SG_ Index m1M : 8|16@1+ (1,0) [4096|25376] "" Vector__XXX
 SG_ TransferType m1M : 1|1@1+ (1,0) [0|1] "" Vector__XXX
 SG_ NotUsedBytes m1 : 2|2@1+ (1,0) [0|3] "" Vector__XXX
 SG_ SizeIndicator m1 : 0|1@1+ (1,0) [0|1] "" Vector__XXX
 SG_ SCS M : 5|3@1+ (1,0) [0|6] "" Vector__XXX

BO_ 1546 CSDO_010: 8 Vector__XXX
 SG_ Write_Output_32_Bit16_6320_10 m16 : 32|32@1+ (1,0) [0|4294967295] ""  I_O_Device_1_ID10
 SG_ Write_Output_32_Bit15_6320_0F m15 : 32|32@1+ (1,0) [0|4294967295] ""  I_O_Device_1_ID10
 SG_ Write_Output_32_Bit14_6320_0E m14 : 32|32@1+ (1,0) [0|4294967295] ""  I_O_Device_1_ID10
 SG_ Write_Output_32_Bit13_6320_0D m13 : 32|32@1+ (1,0) [0|4294967295] ""  I_O_Device_1_ID10
 SG_ Write_Output_32_Bit12_6320_0C m12 : 32|32@1+ (1,0) [0|4294967295] ""  I_O_Device_1_ID10
 SG_ Write_Output_32_Bit11_6320_0B m11 : 32|32@1+ (1,0) [0|4294967295] ""  I_O_Device_1_ID10
 SG_ Write_Output_32_Bit10_6320_0A m10 : 32|32@1+ (1,0) [0|4294967295] ""  I_O_Device_1_ID10
 SG_ Write_Output_32_Bit9_6320_09 m9 : 32|32@1+ (1,0) [0|4294967295] ""  I_O_Device_1_ID10
 SG_ Write_Output_32_Bit8_6320_08 m8 : 32|32@1+ (1,0) [0|4294967295] ""  I_O_Device_1_ID10
 SG_ Write_Output_32_Bit7_6320_07 m7 : 32|32@1+ (1,0) [0|4294967295] ""  I_O_Device_1_ID10
 SG_ Write_Output_32_Bit6_6320_06 m6 : 32|32@1+ (1,0) [0|4294967295] ""  I_O_Device_1_ID10
 SG_ Write_Output_32_Bit5_6320_05 m5 : 32|32@1+ (1,0) [0|4294967295] ""  I_O_Device_1_ID10
 SG_ Write_Output_32_Bit4_6320_04 m4 : 32|32@1+ (1,0) [0|4294967295] ""  I_O_Device_1_ID10
 SG_ Write_Output_32_Bit3_6320_03 m3 : 32|32@1+ (1,0) [0|4294967295] ""  I_O_Device_1_ID10
 SG_ Write_Output_32_Bit2_6320_02 m2 : 32|32@1+ (1,0) [0|4294967295] ""  I_O_Device_1_ID10
 SG_ Write_Output_32_Bit1_6320_01 m1 : 32|32@1+ (1,0) [0|4294967295] ""  I_O_Device_1_ID10
 SG_ NrOfObjects_6320_00 m0 : 32|8@1+ (1,0) [0|255] ""  I_O_Device_1_ID10
 SG_ SubIndex_6320 m25376M : 24|8@1+ (1,0) [0|16] ""  I_O_Device_1_ID10
 SG_ Write_Output_16_Bit16_6300_10 m16 : 32|16@1+ (1,0) [0|65535] ""  I_O_Device_1_ID10
 SG_ Write_Output_16_Bit15_6300_0F m15 : 32|16@1+ (1,0) [0|65535] ""  I_O_Device_1_ID10
 SG_ Write_Output_16_Bit14_6300_0E m14 : 32|16@1+ (1,0) [0|65535] ""  I_O_Device_1_ID10
 SG_ Write_Output_16_Bit13_6300_0D m13 : 32|16@1+ (1,0) [0|65535] ""  I_O_Device_1_ID10
 SG_ Write_Output_16_Bit12_6300_0C m12 : 32|16@1+ (1,0) [0|65535] ""  I_O_Device_1_ID10
 SG_ Write_Output_16_Bit11_6300_0B m11 : 32|16@1+ (1,0) [0|65535] ""  I_O_Device_1_ID10
 SG_ Write_Output_16_Bit10_6300_0A m10 : 32|16@1+ (1,0) [0|65535] ""  I_O_Device_1_ID10
 SG_ Write_Output_16_Bit9_6300_09 m9 : 32|16@1+ (1,0) [0|65535] ""  I_O_Device_1_ID10
 SG_ Write_Output_16_Bit8_6300_08 m8 : 32|16@1+ (1,0) [0|65535] ""  I_O_Device_1_ID10
 SG_ Write_Output_16_Bit7_6300_07 m7 : 32|16@1+ (1,0) [0|65535] ""  I_O_Device_1_ID10
 SG_ Write_Output_16_Bit6_6300_06 m6 : 32|16@1+ (1,0) [0|65535] ""  I_O_Device_1_ID10
 SG_ Write_Output_16_Bit5_6300_05 m5 : 32|16@1+ (1,0) [0|65535] ""  I_O_Device_1_ID10
 SG_ Write_Output_16_Bit4_6300_04 m4 : 32|16@1+ (1,0) [0|65535] ""  I_O_Device_1_ID10
 SG_ Write_Output_16_Bit3_6300_03 m3 : 32|16@1+ (1,0) [0|65535] ""  I_O_Device_1_ID10
 SG_ Write_Output_16_Bit2_6300_02 m2 : 32|16@1+ (1,0) [0|65535] ""  I_O_Device_1_ID10
 SG_ Write_Output_16_Bit1_6300_01 m1 : 32|16@1+ (1,0) [0|65535] ""  I_O_Device_1_ID10
 SG_ NrOfObjects_6300_00 m0 : 32|8@1+ (1,0) [0|255] ""  I_O_Device_1_ID10
 SG_ SubIndex_6300 m25344M : 24|8@1+ (1,0) [0|16] ""  I_O_Device_1_ID10
 SG_ Write_Output_1_Bit64_6220_40 m64 : 32|1@1+ (1,0) [0|1] ""  I_O_Device_1_ID10
 SG_ Write_Output_1_Bit63_6220_3F m63 : 32|1@1+ (1,0) [0|1] ""  I_O_Device_1_ID10
 SG_ Write_Output_1_Bit62_6220_3E m62 : 32|1@1+ (1,0) [0|1] ""  I_O_Device_1_ID10
 SG_ Write_Output_1_Bit61_6220_3D m61 : 32|1@1+ (1,0) [0|1] ""  I_O_Device_1_ID10
 SG_ Write_Output_1_Bit60_6220_3C m60 : 32|1@1+ (1,0) [0|1] ""  I_O_Device_1_ID10
 SG_ Write_Output_1_Bit59_6220_3B m59 : 32|1@1+ (1,0) [0|1] ""  I_O_Device_1_ID10
 SG_ Write_Output_1_Bit58_6220_3A m58 : 32|1@1+ (1,0) [0|1] ""  I_O_Device_1_ID10
 SG_ Write_Output_1_Bit57_6220_39 m57 : 32|1@1+ (1,0) [0|1] ""  I_O_Device_1_ID10
 SG_ Write_Output_1_Bit56_6220_38 m56 : 32|1@1+ (1,0) [0|1] ""  I_O_Device_1_ID10
 SG_ Write_Output_1_Bit55_6220_37 m55 : 32|1@1+ (1,0) [0|1] ""  I_O_Device_1_ID10
 SG_ Write_Output_1_Bit54_6220_36 m54 : 32|1@1+ (1,0) [0|1] ""  I_O_Device_1_ID10
 SG_ Write_Output_1_Bit53_6220_35 m53 : 32|1@1+ (1,0) [0|1] ""  I_O_Device_1_ID10
 SG_ Write_Output_1_Bit52_6220_34 m52 : 32|1@1+ (1,0) [0|1] ""  I_O_Device_1_ID10
 SG_ Write_Output_1_Bit51_6220_33 m51 : 32|1@1+ (1,0) [0|1] ""  I_O_Device_1_ID10
 SG_ Write_Output_1_Bit50_6220_32 m50 : 32|1@1+ (1,0) [0|1] ""  I_O_Device_1_ID10
 SG_ Write_Output_1_Bit49_6220_31 m49 : 32|1@1+ (1,0) [0|1] ""  I_O_Device_1_ID10
 SG_ Write_Output_1_Bit48_6220_30 m48 : 32|1@1+ (1,0) [0|1] ""  I_O_Device_1_ID10
 SG_ Write_Output_1_Bit47_6220_2F m47 : 32|1@1+ (1,0) [0|1] ""  I_O_Device_1_ID10
 SG_ Write_Output_1_Bit46_6220_2E m46 : 32|1@1+ (1,0) [0|1] ""  I_O_Device_1_ID10
 SG_ Write_Output_1_Bit45_6220_2D m45 : 32|1@1+ (1,0) [0|1] ""  I_O_Device_1_ID10
 SG_ Write_Output_1_Bit44_6220_2C m44 : 32|1@1+ (1,0) [0|1] ""  I_O_Device_1_ID10
 SG_ Write_Output_1_Bit43_6220_2B m43 : 32|1@1+ (1,0) [0|1] ""  I_O_Device_1_ID10
 SG_ Write_Output_1_Bit42_6220_2A m42 : 32|1@1+ (1,0) [0|1] ""  I_O_Device_1_ID10
 SG_ Write_Output_1_Bit41_6220_29 m41 : 32|1@1+ (1,0) [0|1] ""  I_O_Device_1_ID10
 SG_ Write_Output_1_Bit40_6220_28 m40 : 32|1@1+ (1,0) [0|1] ""  I_O_Device_1_ID10
 SG_ Write_Output_1_Bit39_6220_27 m39 : 32|1@1+ (1,0) [0|1] ""  I_O_Device_1_ID10
 SG_ Write_Output_1_Bit38_6220_26 m38 : 32|1@1+ (1,0) [0|1] ""  I_O_Device_1_ID10
 SG_ Write_Output_1_Bit37_6220_25 m37 : 32|1@1+ (1,0) [0|1] ""  I_O_Device_1_ID10
 SG_ Write_Output_1_Bit36_6220_24 m36 : 32|1@1+ (1,0) [0|1] ""  I_O_Device_1_ID10
 SG_ Write_Output_1_Bit35_6220_23 m35 : 32|1@1+ (1,0) [0|1] ""  I_O_Device_1_ID10
 SG_ Write_Output_1_Bit34_6220_22 m34 : 32|1@1+ (1,0) [0|1] ""  I_O_Device_1_ID10
 SG_ Write_Output_1_Bit33_6220_21 m33 : 32|1@1+ (1,0) [0|1] ""  I_O_Device_1_ID10
 SG_ Write_Output_1_Bit32_6220_20 m32 : 32|1@1+ (1,0) [0|1] ""  I_O_Device_1_ID10
 SG_ Write_Output_1_Bit31_6220_1F m31 : 32|1@1+ (1,0) [0|1] ""  I_O_Device_1_ID10
 SG_ Write_Output_1_Bit30_6220_1E m30 : 32|1@1+ (1,0) [0|1] ""  I_O_Device_1_ID10
 SG_ Write_Output_1_Bit29_6220_1D m29 : 32|1@1+ (1,0) [0|1] ""  I_O_Device_1_ID10
 SG_ Write_Output_1_Bit28_6220_1C m28 : 32|1@1+ (1,0) [0|1] ""  I_O_Device_1_ID10
 SG_ Write_Output_1_Bit27_6220_1B m27 : 32|1@1+ (1,0) [0|1] ""  I_O_Device_1_ID10
 SG_ Write_Output_1_Bit26_6220_1A m26 : 32|1@1+ (1,0) [0|1] ""  I_O_Device_1_ID10
 SG_ Write_Output_1_Bit25_6220_19 m25 : 32|1@1+ (1,0) [0|1] ""  I_O_Device_1_ID10
 SG_ Write_Output_1_Bit24_6220_18 m24 : 32|1@1+ (1,0) [0|1] ""  I_O_Device_1_ID10
 SG_ Write_Output_1_Bit23_6220_17 m23 : 32|1@1+ (1,0) [0|1] ""  I_O_Device_1_ID10
 SG_ Write_Output_1_Bit22_6220_16 m22 : 32|1@1+ (1,0) [0|1] ""  I_O_Device_1_ID10
 SG_ Write_Output_1_Bit21_6220_15 m21 : 32|1@1+ (1,0) [0|1] ""  I_O_Device_1_ID10
 SG_ Write_Output_1_Bit20_6220_14 m20 : 32|1@1+ (1,0) [0|1] ""  I_O_Device_1_ID10
 SG_ Write_Output_1_Bit19_6220_13 m19 : 32|1@1+ (1,0) [0|1] ""  I_O_Device_1_ID10
 SG_ Write_Output_1_Bit18_6220_12 m18 : 32|1@1+ (1,0) [0|1] ""  I_O_Device_1_ID10
 SG_ Write_Output_1_Bit17_6220_11 m17 : 32|1@1+ (1,0) [0|1] ""  I_O_Device_1_ID10
 SG_ Write_Output_1_Bit16_6220_10 m16 : 32|1@1+ (1,0) [0|1] ""  I_O_Device_1_ID10
 SG_ Write_Output_1_Bit15_6220_0F m15 : 32|1@1+ (1,0) [0|1] ""  I_O_Device_1_ID10
 SG_ Write_Output_1_Bit14_6220_0E m14 : 32|1@1+ (1,0) [0|1] ""  I_O_Device_1_ID10
 SG_ Write_Output_1_Bit13_6220_0D m13 : 32|1@1+ (1,0) [0|1] ""  I_O_Device_1_ID10
 SG_ Write_Output_1_Bit12_6220_0C m12 : 32|1@1+ (1,0) [0|1] ""  I_O_Device_1_ID10
 SG_ Write_Output_1_Bit11_6220_0B m11 : 32|1@1+ (1,0) [0|1] ""  I_O_Device_1_ID10
 SG_ Write_Output_1_Bit10_6220_0A m10 : 32|1@1+ (1,0) [0|1] ""  I_O_Device_1_ID10
 SG_ Write_Output_1_Bit9_6220_09 m9 : 32|1@1+ (1,0) [0|1] ""  I_O_Device_1_ID10
 SG_ Write_Output_1_Bit8_6220_08 m8 : 32|1@1+ (1,0) [0|1] ""  I_O_Device_1_ID10
 SG_ Write_Output_1_Bit7_6220_07 m7 : 32|1@1+ (1,0) [0|1] ""  I_O_Device_1_ID10
 SG_ Write_Output_1_Bit6_6220_06 m6 : 32|1@1+ (1,0) [0|1] ""  I_O_Device_1_ID10
 SG_ Write_Output_1_Bit5_6220_05 m5 : 32|1@1+ (1,0) [0|1] ""  I_O_Device_1_ID10
 SG_ Write_Output_1_Bit4_6220_04 m4 : 32|1@1+ (1,0) [0|1] ""  I_O_Device_1_ID10
 SG_ Write_Output_1_Bit3_6220_03 m3 : 32|1@1+ (1,0) [0|1] ""  I_O_Device_1_ID10
 SG_ Write_Output_1_Bit2_6220_02 m2 : 32|1@1+ (1,0) [0|1] ""  I_O_Device_1_ID10
 SG_ Write_Output_1_Bit1_6220_01 m1 : 32|1@1+ (1,0) [0|1] ""  I_O_Device_1_ID10
 SG_ NrOfObjects_6220_00 m0 : 32|8@1+ (1,0) [0|255] ""  I_O_Device_1_ID10
 SG_ SubIndex_6220 m25120M : 24|8@1+ (1,0) [0|64] ""  I_O_Device_1_ID10
 SG_ Write_Output_8_Bit16_6200_10 m16 : 32|8@1+ (1,0) [0|255] ""  I_O_Device_1_ID10
 SG_ Write_Output_8_Bit15_6200_0F m15 : 32|8@1+ (1,0) [0|255] ""  I_O_Device_1_ID10
 SG_ Write_Output_8_Bit14_6200_0E m14 : 32|8@1+ (1,0) [0|255] ""  I_O_Device_1_ID10
 SG_ Write_Output_8_Bit13_6200_0D m13 : 32|8@1+ (1,0) [0|255] ""  I_O_Device_1_ID10
 SG_ Write_Output_8_Bit12_6200_0C m12 : 32|8@1+ (1,0) [0|255] ""  I_O_Device_1_ID10
 SG_ Write_Output_8_Bit11_6200_0B m11 : 32|8@1+ (1,0) [0|255] ""  I_O_Device_1_ID10
 SG_ Write_Output_8_Bit10_6200_0A m10 : 32|8@1+ (1,0) [0|255] ""  I_O_Device_1_ID10
 SG_ Write_Output_8_Bit9_6200_09 m9 : 32|8@1+ (1,0) [0|255] ""  I_O_Device_1_ID10
 SG_ Write_Output_8_Bit8_6200_08 m8 : 32|8@1+ (1,0) [0|255] ""  I_O_Device_1_ID10
 SG_ Write_Output_8_Bit7_6200_07 m7 : 32|8@1+ (1,0) [0|255] ""  I_O_Device_1_ID10
 SG_ Write_Output_8_Bit6_6200_06 m6 : 32|8@1+ (1,0) [0|255] ""  I_O_Device_1_ID10
 SG_ Write_Output_8_Bit5_6200_05 m5 : 32|8@1+ (1,0) [0|255] ""  I_O_Device_1_ID10
 SG_ Write_Output_8_Bit4_6200_04 m4 : 32|8@1+ (1,0) [0|255] ""  I_O_Device_1_ID10
 SG_ Write_Output_8_Bit3_6200_03 m3 : 32|8@1+ (1,0) [0|255] ""  I_O_Device_1_ID10
 SG_ Write_Output_8_Bit2_6200_02 m2 : 32|8@1+ (1,0) [0|255] ""  I_O_Device_1_ID10
 SG_ Write_Output_8_Bit1_6200_01 m1 : 32|8@1+ (1,0) [0|255] ""  I_O_Device_1_ID10
 SG_ NrOfObjects_6200_00 m0 : 32|8@1+ (1,0) [0|255] ""  I_O_Device_1_ID10
 SG_ SubIndex_6200 m25088M : 24|8@1+ (1,0) [0|16] ""  I_O_Device_1_ID10
 SG_ Read_Input_32_Bit16_6120_10 m16 : 32|32@1+ (1,0) [0|4294967295] ""  I_O_Device_1_ID10
 SG_ Read_Input_32_Bit15_6120_0F m15 : 32|32@1+ (1,0) [0|4294967295] ""  I_O_Device_1_ID10
 SG_ Read_Input_32_Bit14_6120_0E m14 : 32|32@1+ (1,0) [0|4294967295] ""  I_O_Device_1_ID10
 SG_ Read_Input_32_Bit13_6120_0D m13 : 32|32@1+ (1,0) [0|4294967295] ""  I_O_Device_1_ID10
 SG_ Read_Input_32_Bit12_6120_0C m12 : 32|32@1+ (1,0) [0|4294967295] ""  I_O_Device_1_ID10
 SG_ Read_Input_32_Bit11_6120_0B m11 : 32|32@1+ (1,0) [0|4294967295] ""  I_O_Device_1_ID10
 SG_ Read_Input_32_Bit10_6120_0A m10 : 32|32@1+ (1,0) [0|4294967295] ""  I_O_Device_1_ID10
 SG_ Read_Input_32_Bit9_6120_09 m9 : 32|32@1+ (1,0) [0|4294967295] ""  I_O_Device_1_ID10
 SG_ Read_Input_32_Bit8_6120_08 m8 : 32|32@1+ (1,0) [0|4294967295] ""  I_O_Device_1_ID10
 SG_ Read_Input_32_Bit7_6120_07 m7 : 32|32@1+ (1,0) [0|4294967295] ""  I_O_Device_1_ID10
 SG_ Read_Input_32_Bit6_6120_06 m6 : 32|32@1+ (1,0) [0|4294967295] ""  I_O_Device_1_ID10
 SG_ Read_Input_32_Bit5_6120_05 m5 : 32|32@1+ (1,0) [0|4294967295] ""  I_O_Device_1_ID10
 SG_ Read_Input_32_Bit4_6120_04 m4 : 32|32@1+ (1,0) [0|4294967295] ""  I_O_Device_1_ID10
 SG_ Read_Input_32_Bit3_6120_03 m3 : 32|32@1+ (1,0) [0|4294967295] ""  I_O_Device_1_ID10
 SG_ Read_Input_32_Bit2_6120_02 m2 : 32|32@1+ (1,0) [0|4294967295] ""  I_O_Device_1_ID10
 SG_ Read_Input_32_Bit1_6120_01 m1 : 32|32@1+ (1,0) [0|4294967295] ""  I_O_Device_1_ID10
 SG_ NrOfObjects_6120_00 m0 : 32|8@1+ (1,0) [0|255] ""  I_O_Device_1_ID10
 SG_ SubIndex_6120 m24864M : 24|8@1+ (1,0) [0|16] ""  I_O_Device_1_ID10
 SG_ Read_Input_16_Bit16_6100_10 m16 : 32|16@1+ (1,0) [0|65535] ""  I_O_Device_1_ID10
 SG_ Read_Input_16_Bit15_6100_0F m15 : 32|16@1+ (1,0) [0|65535] ""  I_O_Device_1_ID10
 SG_ Read_Input_16_Bit14_6100_0E m14 : 32|16@1+ (1,0) [0|65535] ""  I_O_Device_1_ID10
 SG_ Read_Input_16_Bit13_6100_0D m13 : 32|16@1+ (1,0) [0|65535] ""  I_O_Device_1_ID10
 SG_ Read_Input_16_Bit12_6100_0C m12 : 32|16@1+ (1,0) [0|65535] ""  I_O_Device_1_ID10
 SG_ Read_Input_16_Bit11_6100_0B m11 : 32|16@1+ (1,0) [0|65535] ""  I_O_Device_1_ID10
 SG_ Read_Input_16_Bit10_6100_0A m10 : 32|16@1+ (1,0) [0|65535] ""  I_O_Device_1_ID10
 SG_ Read_Input_16_Bit9_6100_09 m9 : 32|16@1+ (1,0) [0|65535] ""  I_O_Device_1_ID10
 SG_ Read_Input_16_Bit8_6100_08 m8 : 32|16@1+ (1,0) [0|65535] ""  I_O_Device_1_ID10
 SG_ Read_Input_16_Bit7_6100_07 m7 : 32|16@1+ (1,0) [0|65535] ""  I_O_Device_1_ID10
 SG_ Read_Input_16_Bit6_6100_06 m6 : 32|16@1+ (1,0) [0|65535] ""  I_O_Device_1_ID10
 SG_ Read_Input_16_Bit5_6100_05 m5 : 32|16@1+ (1,0) [0|65535] ""  I_O_Device_1_ID10
 SG_ Read_Input_16_Bit4_6100_04 m4 : 32|16@1+ (1,0) [0|65535] ""  I_O_Device_1_ID10
 SG_ Read_Input_16_Bit3_6100_03 m3 : 32|16@1+ (1,0) [0|65535] ""  I_O_Device_1_ID10
 SG_ Read_Input_16_Bit2_6100_02 m2 : 32|16@1+ (1,0) [0|65535] ""  I_O_Device_1_ID10
 SG_ Read_Input_16_Bit1_6100_01 m1 : 32|16@1+ (1,0) [0|65535] ""  I_O_Device_1_ID10
 SG_ NrOfObjects_6100_00 m0 : 32|8@1+ (1,0) [0|255] ""  I_O_Device_1_ID10
 SG_ SubIndex_6100 m24832M : 24|8@1+ (1,0) [0|16] ""  I_O_Device_1_ID10
 SG_ Read_Input_1_Bit64_6020_40 m64 : 32|1@1+ (1,0) [0|1] ""  I_O_Device_1_ID10
 SG_ Read_Input_1_Bit63_6020_3F m63 : 32|1@1+ (1,0) [0|1] ""  I_O_Device_1_ID10
 SG_ Read_Input_1_Bit62_6020_3E m62 : 32|1@1+ (1,0) [0|1] ""  I_O_Device_1_ID10
 SG_ Read_Input_1_Bit61_6020_3D m61 : 32|1@1+ (1,0) [0|1] ""  I_O_Device_1_ID10
 SG_ Read_Input_1_Bit60_6020_3C m60 : 32|1@1+ (1,0) [0|1] ""  I_O_Device_1_ID10
 SG_ Read_Input_1_Bit59_6020_3B m59 : 32|1@1+ (1,0) [0|1] ""  I_O_Device_1_ID10
 SG_ Read_Input_1_Bit58_6020_3A m58 : 32|1@1+ (1,0) [0|1] ""  I_O_Device_1_ID10
 SG_ Read_Input_1_Bit57_6020_39 m57 : 32|1@1+ (1,0) [0|1] ""  I_O_Device_1_ID10
 SG_ Read_Input_1_Bit56_6020_38 m56 : 32|1@1+ (1,0) [0|1] ""  I_O_Device_1_ID10
 SG_ Read_Input_1_Bit55_6020_37 m55 : 32|1@1+ (1,0) [0|1] ""  I_O_Device_1_ID10
 SG_ Read_Input_1_Bit54_6020_36 m54 : 32|1@1+ (1,0) [0|1] ""  I_O_Device_1_ID10
 SG_ Read_Input_1_Bit53_6020_35 m53 : 32|1@1+ (1,0) [0|1] ""  I_O_Device_1_ID10
 SG_ Read_Input_1_Bit52_6020_34 m52 : 32|1@1+ (1,0) [0|1] ""  I_O_Device_1_ID10
 SG_ Read_Input_1_Bit51_6020_33 m51 : 32|1@1+ (1,0) [0|1] ""  I_O_Device_1_ID10
 SG_ Read_Input_1_Bit50_6020_32 m50 : 32|1@1+ (1,0) [0|1] ""  I_O_Device_1_ID10
 SG_ Read_Input_1_Bit49_6020_31 m49 : 32|1@1+ (1,0) [0|1] ""  I_O_Device_1_ID10
 SG_ Read_Input_1_Bit48_6020_30 m48 : 32|1@1+ (1,0) [0|1] ""  I_O_Device_1_ID10
 SG_ Read_Input_1_Bit47_6020_2F m47 : 32|1@1+ (1,0) [0|1] ""  I_O_Device_1_ID10
 SG_ Read_Input_1_Bit46_6020_2E m46 : 32|1@1+ (1,0) [0|1] ""  I_O_Device_1_ID10
 SG_ Read_Input_1_Bit45_6020_2D m45 : 32|1@1+ (1,0) [0|1] ""  I_O_Device_1_ID10
 SG_ Read_Input_1_Bit44_6020_2C m44 : 32|1@1+ (1,0) [0|1] ""  I_O_Device_1_ID10
 SG_ Read_Input_1_Bit43_6020_2B m43 : 32|1@1+ (1,0) [0|1] ""  I_O_Device_1_ID10
 SG_ Read_Input_1_Bit42_6020_2A m42 : 32|1@1+ (1,0) [0|1] ""  I_O_Device_1_ID10
 SG_ Read_Input_1_Bit41_6020_29 m41 : 32|1@1+ (1,0) [0|1] ""  I_O_Device_1_ID10
 SG_ Read_Input_1_Bit40_6020_28 m40 : 32|1@1+ (1,0) [0|1] ""  I_O_Device_1_ID10
 SG_ Read_Input_1_Bit39_6020_27 m39 : 32|1@1+ (1,0) [0|1] ""  I_O_Device_1_ID10
 SG_ Read_Input_1_Bit38_6020_26 m38 : 32|1@1+ (1,0) [0|1] ""  I_O_Device_1_ID10
 SG_ Read_Input_1_Bit37_6020_25 m37 : 32|1@1+ (1,0) [0|1] ""  I_O_Device_1_ID10
 SG_ Read_Input_1_Bit36_6020_24 m36 : 32|1@1+ (1,0) [0|1] ""  I_O_Device_1_ID10
 SG_ Read_Input_1_Bit35_6020_23 m35 : 32|1@1+ (1,0) [0|1] ""  I_O_Device_1_ID10
 SG_ Read_Input_1_Bit34_6020_22 m34 : 32|1@1+ (1,0) [0|1] ""  I_O_Device_1_ID10
 SG_ Read_Input_1_Bit33_6020_21 m33 : 32|1@1+ (1,0) [0|1] ""  I_O_Device_1_ID10
 SG_ Read_Input_1_Bit32_6020_20 m32 : 32|1@1+ (1,0) [0|1] ""  I_O_Device_1_ID10
 SG_ Read_Input_1_Bit31_6020_1F m31 : 32|1@1+ (1,0) [0|1] ""  I_O_Device_1_ID10
 SG_ Read_Input_1_Bit30_6020_1E m30 : 32|1@1+ (1,0) [0|1] ""  I_O_Device_1_ID10
 SG_ Read_Input_1_Bit29_6020_1D m29 : 32|1@1+ (1,0) [0|1] ""  I_O_Device_1_ID10
 SG_ Read_Input_1_Bit28_6020_1C m28 : 32|1@1+ (1,0) [0|1] ""  I_O_Device_1_ID10
 SG_ Read_Input_1_Bit27_6020_1B m27 : 32|1@1+ (1,0) [0|1] ""  I_O_Device_1_ID10
 SG_ Read_Input_1_Bit26_6020_1A m26 : 32|1@1+ (1,0) [0|1] ""  I_O_Device_1_ID10
 SG_ Read_Input_1_Bit25_6020_19 m25 : 32|1@1+ (1,0) [0|1] ""  I_O_Device_1_ID10
 SG_ Read_Input_1_Bit24_6020_18 m24 : 32|1@1+ (1,0) [0|1] ""  I_O_Device_1_ID10
 SG_ Read_Input_1_Bit23_6020_17 m23 : 32|1@1+ (1,0) [0|1] ""  I_O_Device_1_ID10
 SG_ Read_Input_1_Bit22_6020_16 m22 : 32|1@1+ (1,0) [0|1] ""  I_O_Device_1_ID10
 SG_ Read_Input_1_Bit21_6020_15 m21 : 32|1@1+ (1,0) [0|1] ""  I_O_Device_1_ID10
 SG_ Read_Input_1_Bit20_6020_14 m20 : 32|1@1+ (1,0) [0|1] ""  I_O_Device_1_ID10
 SG_ Read_Input_1_Bit19_6020_13 m19 : 32|1@1+ (1,0) [0|1] ""  I_O_Device_1_ID10
 SG_ Read_Input_1_Bit18_6020_12 m18 : 32|1@1+ (1,0) [0|1] ""  I_O_Device_1_ID10
 SG_ Read_Input_1_Bit17_6020_11 m17 : 32|1@1+ (1,0) [0|1] ""  I_O_Device_1_ID10
 SG_ Read_Input_1_Bit16_6020_10 m16 : 32|1@1+ (1,0) [0|1] ""  I_O_Device_1_ID10
 SG_ Read_Input_1_Bit15_6020_0F m15 : 32|1@1+ (1,0) [0|1] ""  I_O_Device_1_ID10
 SG_ Read_Input_1_Bit14_6020_0E m14 : 32|1@1+ (1,0) [0|1] ""  I_O_Device_1_ID10
 SG_ Read_Input_1_Bit13_6020_0D m13 : 32|1@1+ (1,0) [0|1] ""  I_O_Device_1_ID10
 SG_ Read_Input_1_Bit12_6020_0C m12 : 32|1@1+ (1,0) [0|1] ""  I_O_Device_1_ID10
 SG_ Read_Input_1_Bit11_6020_0B m11 : 32|1@1+ (1,0) [0|1] ""  I_O_Device_1_ID10
 SG_ Read_Input_1_Bit10_6020_0A m10 : 32|1@1+ (1,0) [0|1] ""  I_O_Device_1_ID10
 SG_ Read_Input_1_Bit9_6020_09 m9 : 32|1@1+ (1,0) [0|1] ""  I_O_Device_1_ID10
 SG_ Read_Input_1_Bit8_6020_08 m8 : 32|1@1+ (1,0) [0|1] ""  I_O_Device_1_ID10
 SG_ Read_Input_1_Bit7_6020_07 m7 : 32|1@1+ (1,0) [0|1] ""  I_O_Device_1_ID10
 SG_ Read_Input_1_Bit6_6020_06 m6 : 32|1@1+ (1,0) [0|1] ""  I_O_Device_1_ID10
 SG_ Read_Input_1_Bit5_6020_05 m5 : 32|1@1+ (1,0) [0|1] ""  I_O_Device_1_ID10
 SG_ Read_Input_1_Bit4_6020_04 m4 : 32|1@1+ (1,0) [0|1] ""  I_O_Device_1_ID10
 SG_ Read_Input_1_Bit3_6020_03 m3 : 32|1@1+ (1,0) [0|1] ""  I_O_Device_1_ID10
 SG_ Read_Input_1_Bit2_6020_02 m2 : 32|1@1+ (1,0) [0|1] ""  I_O_Device_1_ID10
 SG_ Read_Input_1_Bit1_6020_01 m1 : 32|1@1+ (1,0) [0|1] ""  I_O_Device_1_ID10
 SG_ NrOfObjects_6020_00 m0 : 32|8@1+ (1,0) [0|255] ""  I_O_Device_1_ID10
 SG_ SubIndex_6020 m24608M : 24|8@1+ (1,0) [0|64] ""  I_O_Device_1_ID10
 SG_ Read_Input_8_Bit16_6000_10 m16 : 32|8@1+ (1,0) [0|255] ""  I_O_Device_1_ID10
 SG_ Read_Input_8_Bit15_6000_0F m15 : 32|8@1+ (1,0) [0|255] ""  I_O_Device_1_ID10
 SG_ Read_Input_8_Bit14_6000_0E m14 : 32|8@1+ (1,0) [0|255] ""  I_O_Device_1_ID10
 SG_ Read_Input_8_Bit13_6000_0D m13 : 32|8@1+ (1,0) [0|255] ""  I_O_Device_1_ID10
 SG_ Read_Input_8_Bit12_6000_0C m12 : 32|8@1+ (1,0) [0|255] ""  I_O_Device_1_ID10
 SG_ Read_Input_8_Bit11_6000_0B m11 : 32|8@1+ (1,0) [0|255] ""  I_O_Device_1_ID10
 SG_ Read_Input_8_Bit10_6000_0A m10 : 32|8@1+ (1,0) [0|255] ""  I_O_Device_1_ID10
 SG_ Read_Input_8_Bit9_6000_09 m9 : 32|8@1+ (1,0) [0|255] ""  I_O_Device_1_ID10
 SG_ Read_Input_8_Bit8_6000_08 m8 : 32|8@1+ (1,0) [0|255] ""  I_O_Device_1_ID10
 SG_ Read_Input_8_Bit7_6000_07 m7 : 32|8@1+ (1,0) [0|255] ""  I_O_Device_1_ID10
 SG_ Read_Input_8_Bit6_6000_06 m6 : 32|8@1+ (1,0) [0|255] ""  I_O_Device_1_ID10
 SG_ Read_Input_8_Bit5_6000_05 m5 : 32|8@1+ (1,0) [0|255] ""  I_O_Device_1_ID10
 SG_ Read_Input_8_Bit4_6000_04 m4 : 32|8@1+ (1,0) [0|255] ""  I_O_Device_1_ID10
 SG_ Read_Input_8_Bit3_6000_03 m3 : 32|8@1+ (1,0) [0|255] ""  I_O_Device_1_ID10
 SG_ Read_Input_8_Bit2_6000_02 m2 : 32|8@1+ (1,0) [0|255] ""  I_O_Device_1_ID10
 SG_ Read_Input_8_Bit1_6000_01 m1 : 32|8@1+ (1,0) [0|255] ""  I_O_Device_1_ID10
 SG_ NrOfObjects_6000_00 m0 : 32|8@1+ (1,0) [0|255] ""  I_O_Device_1_ID10
 SG_ SubIndex_6000 m24576M : 24|8@1+ (1,0) [0|16] ""  I_O_Device_1_ID10
 SG_ NrOfObjects_2300_00 m0 : 32|8@1+ (1,0) [0|255] ""  I_O_Device_1_ID10
 SG_ SubIndex_2300 m8960M : 24|8@1+ (1,0) [0|4] ""  I_O_Device_1_ID10
 SG_ NrOfObjects_2200_00 m0 : 32|8@1+ (1,0) [0|255] ""  I_O_Device_1_ID10
 SG_ SubIndex_2200 m8704M : 24|8@1+ (1,0) [0|4] ""  I_O_Device_1_ID10
 SG_ NrOfMappedObjects_1A03_00 m0 : 32|8@1+ (1,0) [0|64] ""  I_O_Device_1_ID10
 SG_ SubIndex_1A03 m6659M : 24|8@1+ (1,0) [0|0] ""  I_O_Device_1_ID10
 SG_ NrOfMappedObjects_1A02_00 m0 : 32|8@1+ (1,0) [0|64] ""  I_O_Device_1_ID10
 SG_ SubIndex_1A02 m6658M : 24|8@1+ (1,0) [0|0] ""  I_O_Device_1_ID10
 SG_ mappedObj2_1A01_02 m2 : 32|32@1+ (1,0) [0|4294967295] ""  I_O_Device_1_ID10
 SG_ mappedObj1_1A01_01 m1 : 32|32@1+ (1,0) [0|4294967295] ""  I_O_Device_1_ID10
 SG_ NrOfMappedObjects_1A01_00 m0 : 32|8@1+ (1,0) [0|64] ""  I_O_Device_1_ID10
 SG_ SubIndex_1A01 m6657M : 24|8@1+ (1,0) [0|2] ""  I_O_Device_1_ID10
 SG_ mappedObj2_1A00_02 m2 : 32|32@1+ (1,0) [0|4294967295] ""  I_O_Device_1_ID10
 SG_ mappedObj1_1A00_01 m1 : 32|32@1+ (1,0) [0|4294967295] ""  I_O_Device_1_ID10
 SG_ NrOfMappedObjects_1A00_00 m0 : 32|8@1+ (1,0) [0|64] ""  I_O_Device_1_ID10
 SG_ SubIndex_1A00 m6656M : 24|8@1+ (1,0) [0|2] ""  I_O_Device_1_ID10
 SG_ EventTimer_1803_05 m5 : 32|16@1+ (1,0) [0|65535] ""  I_O_Device_1_ID10
 SG_ TransmissionType_1803_02 m2 : 32|8@1+ (1,0) [0|255] ""  I_O_Device_1_ID10
 SG_ COB_ID_1803_01 m1 : 32|32@1+ (1,0) [128|4294967295] ""  I_O_Device_1_ID10
 SG_ Highest_sub_index_supported_0032 m0 : 32|8@1+ (1,0) [2|5] ""  I_O_Device_1_ID10
 SG_ SubIndex_1803 m6147M : 24|8@1+ (1,0) [0|5] ""  I_O_Device_1_ID10
 SG_ EventTimer_1802_05 m5 : 32|16@1+ (1,0) [0|65535] ""  I_O_Device_1_ID10
 SG_ TransmissionType_1802_02 m2 : 32|8@1+ (1,0) [0|255] ""  I_O_Device_1_ID10
 SG_ COB_ID_1802_01 m1 : 32|32@1+ (1,0) [128|4294967295] ""  I_O_Device_1_ID10
 SG_ Highest_sub_index_supported_0033 m0 : 32|8@1+ (1,0) [2|5] ""  I_O_Device_1_ID10
 SG_ SubIndex_1802 m6146M : 24|8@1+ (1,0) [0|5] ""  I_O_Device_1_ID10
 SG_ EventTimer_1801_05 m5 : 32|16@1+ (1,0) [0|65535] ""  I_O_Device_1_ID10
 SG_ TransmissionType_1801_02 m2 : 32|8@1+ (1,0) [0|255] ""  I_O_Device_1_ID10
 SG_ COB_ID_1801_01 m1 : 32|32@1+ (1,0) [128|4294967295] ""  I_O_Device_1_ID10
 SG_ Highest_sub_index_supported_0034 m0 : 32|8@1+ (1,0) [2|5] ""  I_O_Device_1_ID10
 SG_ SubIndex_1801 m6145M : 24|8@1+ (1,0) [0|5] ""  I_O_Device_1_ID10
 SG_ EventTimer_1800_05 m5 : 32|16@1+ (1,0) [0|65535] ""  I_O_Device_1_ID10
 SG_ TransmissionType_1800_02 m2 : 32|8@1+ (1,0) [0|255] ""  I_O_Device_1_ID10
 SG_ COB_ID_1800_01 m1 : 32|32@1+ (1,0) [128|4294967295] ""  I_O_Device_1_ID10
 SG_ Highest_sub_index_supported_0035 m0 : 32|8@1+ (1,0) [2|5] ""  I_O_Device_1_ID10
 SG_ SubIndex_1800 m6144M : 24|8@1+ (1,0) [0|5] ""  I_O_Device_1_ID10
 SG_ NrOfMappedObjects_1603_00 m0 : 32|8@1+ (1,0) [0|64] ""  I_O_Device_1_ID10
 SG_ SubIndex_1603 m5635M : 24|8@1+ (1,0) [0|0] ""  I_O_Device_1_ID10
 SG_ NrOfMappedObjects_1602_00 m0 : 32|8@1+ (1,0) [0|64] ""  I_O_Device_1_ID10
 SG_ SubIndex_1602 m5634M : 24|8@1+ (1,0) [0|0] ""  I_O_Device_1_ID10
 SG_ NrOfMappedObjects_1601_00 m0 : 32|8@1+ (1,0) [0|64] ""  I_O_Device_1_ID10
 SG_ SubIndex_1601 m5633M : 24|8@1+ (1,0) [0|0] ""  I_O_Device_1_ID10
 SG_ NrOfMappedObjects_1600_00 m0 : 32|8@1+ (1,0) [0|64] ""  I_O_Device_1_ID10
 SG_ SubIndex_1600 m5632M : 24|8@1+ (1,0) [0|0] ""  I_O_Device_1_ID10
 SG_ TransmissionType_1403_02 m2 : 32|8@1+ (1,0) [0|255] ""  I_O_Device_1_ID10
 SG_ COB_ID_1403_01 m1 : 32|32@1+ (1,0) [128|4294967295] ""  I_O_Device_1_ID10
 SG_ Highest_sub_index_supported_0036 m0 : 32|8@1+ (1,0) [2|5] ""  I_O_Device_1_ID10
 SG_ SubIndex_1403 m5123M : 24|8@1+ (1,0) [0|2] ""  I_O_Device_1_ID10
 SG_ TransmissionType_1402_02 m2 : 32|8@1+ (1,0) [0|255] ""  I_O_Device_1_ID10
 SG_ COB_ID_1402_01 m1 : 32|32@1+ (1,0) [128|4294967295] ""  I_O_Device_1_ID10
 SG_ Highest_sub_index_supported_0037 m0 : 32|8@1+ (1,0) [2|5] ""  I_O_Device_1_ID10
 SG_ SubIndex_1402 m5122M : 24|8@1+ (1,0) [0|2] ""  I_O_Device_1_ID10
 SG_ TransmissionType_1401_02 m2 : 32|8@1+ (1,0) [0|255] ""  I_O_Device_1_ID10
 SG_ COB_ID_1401_01 m1 : 32|32@1+ (1,0) [128|4294967295] ""  I_O_Device_1_ID10
 SG_ Highest_sub_index_supported_0038 m0 : 32|8@1+ (1,0) [2|5] ""  I_O_Device_1_ID10
 SG_ SubIndex_1401 m5121M : 24|8@1+ (1,0) [0|2] ""  I_O_Device_1_ID10
 SG_ TransmissionType_1400_02 m2 : 32|8@1+ (1,0) [0|255] ""  I_O_Device_1_ID10
 SG_ COB_ID_1400_01 m1 : 32|32@1+ (1,0) [128|4294967295] ""  I_O_Device_1_ID10
 SG_ Highest_sub_index_supported_0039 m0 : 32|8@1+ (1,0) [2|5] ""  I_O_Device_1_ID10
 SG_ SubIndex_1400 m5120M : 24|8@1+ (1,0) [0|2] ""  I_O_Device_1_ID10
 SG_ Serial_number_1018_04 m4 : 32|32@1+ (1,0) [0|4294967295] ""  I_O_Device_1_ID10
 SG_ Revision_number_1018_03 m3 : 32|32@1+ (1,0) [0|4294967295] ""  I_O_Device_1_ID10
 SG_ Product_Code_1018_02 m2 : 32|32@1+ (1,0) [0|4294967295] ""  I_O_Device_1_ID10
 SG_ Vendor_Id_1018_01 m1 : 32|32@1+ (1,0) [0|4294967295] ""  I_O_Device_1_ID10
 SG_ Highest_sub_index_supported_0040 m0 : 32|8@1+ (1,0) [1|4] ""  I_O_Device_1_ID10
 SG_ SubIndex_1018 m4120M : 24|8@1+ (1,0) [0|4] ""  I_O_Device_1_ID10
 SG_ Producer_Heartbeat_Time_1017 m0 : 32|16@1+ (1,0) [0|65535] ""  I_O_Device_1_ID10
 SG_ SubIndex_1017 m4119M : 24|8@1+ (1,0) [0|0] ""  I_O_Device_1_ID10
 SG_ Consumer_Heartbeat_Time16_1_0004 m16 : 32|32@1+ (1,0) [0|4294967295] ""  I_O_Device_1_ID10
 SG_ Consumer_Heartbeat_Time15_1_0004 m15 : 32|32@1+ (1,0) [0|4294967295] ""  I_O_Device_1_ID10
 SG_ Consumer_Heartbeat_Time14_1_0004 m14 : 32|32@1+ (1,0) [0|4294967295] ""  I_O_Device_1_ID10
 SG_ Consumer_Heartbeat_Time13_1_0004 m13 : 32|32@1+ (1,0) [0|4294967295] ""  I_O_Device_1_ID10
 SG_ Consumer_Heartbeat_Time12_1_0004 m12 : 32|32@1+ (1,0) [0|4294967295] ""  I_O_Device_1_ID10
 SG_ Consumer_Heartbeat_Time11_1_0004 m11 : 32|32@1+ (1,0) [0|4294967295] ""  I_O_Device_1_ID10
 SG_ Consumer_Heartbeat_Time10_1_0004 m10 : 32|32@1+ (1,0) [0|4294967295] ""  I_O_Device_1_ID10
 SG_ Consumer_Heartbeat_Time9_1016_09 m9 : 32|32@1+ (1,0) [0|4294967295] ""  I_O_Device_1_ID10
 SG_ Consumer_Heartbeat_Time8_1016_08 m8 : 32|32@1+ (1,0) [0|4294967295] ""  I_O_Device_1_ID10
 SG_ Consumer_Heartbeat_Time7_1016_07 m7 : 32|32@1+ (1,0) [0|4294967295] ""  I_O_Device_1_ID10
 SG_ Consumer_Heartbeat_Time6_1016_06 m6 : 32|32@1+ (1,0) [0|4294967295] ""  I_O_Device_1_ID10
 SG_ Consumer_Heartbeat_Time5_1016_05 m5 : 32|32@1+ (1,0) [0|4294967295] ""  I_O_Device_1_ID10
 SG_ Consumer_Heartbeat_Time4_1016_04 m4 : 32|32@1+ (1,0) [0|4294967295] ""  I_O_Device_1_ID10
 SG_ Consumer_Heartbeat_Time3_1016_03 m3 : 32|32@1+ (1,0) [0|4294967295] ""  I_O_Device_1_ID10
 SG_ Consumer_Heartbeat_Time2_1016_02 m2 : 32|32@1+ (1,0) [0|4294967295] ""  I_O_Device_1_ID10
 SG_ Consumer_Heartbeat_Time1_1016_01 m1 : 32|32@1+ (1,0) [0|4294967295] ""  I_O_Device_1_ID10
 SG_ NrOfObjects_1016_00 m0 : 32|8@1+ (1,0) [0|255] ""  I_O_Device_1_ID10
 SG_ SubIndex_1016 m4118M : 24|8@1+ (1,0) [0|16] ""  I_O_Device_1_ID10
 SG_ COB_ID_EMCY_1014 m0 : 32|32@1+ (1,0) [128|3221225471] ""  I_O_Device_1_ID10
 SG_ SubIndex_1014 m4116M : 24|8@1+ (1,0) [0|0] ""  I_O_Device_1_ID10
 SG_ Restore_all_Default_Paramet_0004 m1 : 32|32@1+ (1,0) [0|4294967295] ""  I_O_Device_1_ID10
 SG_ Highest_sub_index_supported_0041 m0 : 32|8@1+ (1,0) [0|255] ""  I_O_Device_1_ID10
 SG_ SubIndex_1011 m4113M : 24|8@1+ (1,0) [0|1] ""  I_O_Device_1_ID10
 SG_ Save_all_Parameters_1010_01 m1 : 32|32@1+ (1,0) [0|4294967295] ""  I_O_Device_1_ID10
 SG_ Highest_sub_index_supported_0042 m0 : 32|8@1+ (1,0) [0|255] ""  I_O_Device_1_ID10
 SG_ SubIndex_1010 m4112M : 24|8@1+ (1,0) [0|1] ""  I_O_Device_1_ID10
 SG_ Life_Time_Factor_100D m0 : 32|8@1+ (1,0) [0|255] ""  I_O_Device_1_ID10
 SG_ SubIndex_100D m4109M : 24|8@1+ (1,0) [0|0] ""  I_O_Device_1_ID10
 SG_ Guard_Time_100C m0 : 32|16@1+ (1,0) [0|65535] ""  I_O_Device_1_ID10
 SG_ SubIndex_100C m4108M : 24|8@1+ (1,0) [0|0] ""  I_O_Device_1_ID10
 SG_ Synchronous_Window_Length_1007 m0 : 32|32@1+ (1,0) [0|4294967295] ""  I_O_Device_1_ID10
 SG_ SubIndex_1007 m4103M : 24|8@1+ (1,0) [0|0] ""  I_O_Device_1_ID10
 SG_ Communication_Cycle_Period_1006 m0 : 32|32@1+ (1,0) [0|4294967295] ""  I_O_Device_1_ID10
 SG_ SubIndex_1006 m4102M : 24|8@1+ (1,0) [0|0] ""  I_O_Device_1_ID10
 SG_ COB_ID_SYNC_1005 m0 : 32|32@1+ (1,0) [128|4294967295] ""  I_O_Device_1_ID10
 SG_ SubIndex_1005 m4101M : 24|8@1+ (1,0) [0|0] ""  I_O_Device_1_ID10
 SG_ Standard_error_field_1003_09 m9 : 32|32@1+ (1,0) [0|4294967295] ""  I_O_Device_1_ID10
 SG_ Standard_error_field_1003_08 m8 : 32|32@1+ (1,0) [0|4294967295] ""  I_O_Device_1_ID10
 SG_ Standard_error_field_1003_07 m7 : 32|32@1+ (1,0) [0|4294967295] ""  I_O_Device_1_ID10
 SG_ Standard_error_field_1003_06 m6 : 32|32@1+ (1,0) [0|4294967295] ""  I_O_Device_1_ID10
 SG_ Standard_error_field_1003_05 m5 : 32|32@1+ (1,0) [0|4294967295] ""  I_O_Device_1_ID10
 SG_ Standard_error_field_1003_04 m4 : 32|32@1+ (1,0) [0|4294967295] ""  I_O_Device_1_ID10
 SG_ Standard_error_field_1003_03 m3 : 32|32@1+ (1,0) [0|4294967295] ""  I_O_Device_1_ID10
 SG_ Standard_error_field_1003_02 m2 : 32|32@1+ (1,0) [0|4294967295] ""  I_O_Device_1_ID10
 SG_ Standard_error_field_1003_01 m1 : 32|32@1+ (1,0) [0|4294967295] ""  I_O_Device_1_ID10
 SG_ Number_of_Errors_1003_00 m0 : 32|8@1+ (1,0) [0|255] ""  I_O_Device_1_ID10
 SG_ SubIndex_1003 m4099M : 24|8@1+ (1,0) [0|9] ""  I_O_Device_1_ID10
 SG_ Error_Register_1001 m0 : 32|8@1+ (1,0) [0|255] ""  I_O_Device_1_ID10
 SG_ SubIndex_1001 m4097M : 24|8@1+ (1,0) [0|0] ""  I_O_Device_1_ID10
 SG_ Device_Type_1000 m0 : 32|32@1+ (1,0) [0|4294967295] ""  I_O_Device_1_ID10
 SG_ SubIndex_1000 m4096M : 24|8@1+ (1,0) [0|0] ""  I_O_Device_1_ID10
 SG_ Index m1M : 8|16@1+ (1,0) [4096|25376] ""  I_O_Device_1_ID10
 SG_ TransferType m1M : 1|1@1+ (1,0) [0|1] ""  I_O_Device_1_ID10
 SG_ NotUsedBytes m1 : 2|2@1+ (1,0) [0|3] ""  I_O_Device_1_ID10
 SG_ SizeIndicator m1 : 0|1@1+ (1,0) [0|1] ""  I_O_Device_1_ID10
 SG_ CCS M : 5|3@1+ (1,0) [0|6] ""  I_O_Device_1_ID10

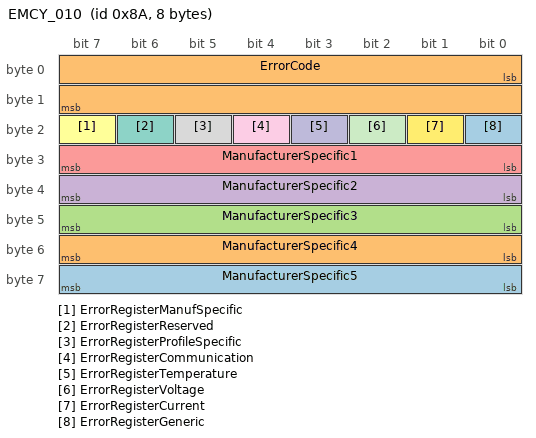
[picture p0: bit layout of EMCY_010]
BO_ 138 EMCY_010: 8 I_O_Device_1_ID10
 SG_ ManufacturerSpecific5 : 56|8@1+ (1,0) [0|0] "" Vector__XXX
 SG_ ManufacturerSpecific4 : 48|8@1+ (1,0) [0|0] "" Vector__XXX
 SG_ ManufacturerSpecific3 : 40|8@1+ (1,0) [0|0] "" Vector__XXX
 SG_ ManufacturerSpecific2 : 32|8@1+ (1,0) [0|0] "" Vector__XXX
 SG_ ManufacturerSpecific1 : 24|8@1+ (1,0) [0|0] "" Vector__XXX
 SG_ ErrorRegisterManufSpecific : 23|1@1+ (1,0) [0|0] "" Vector__XXX
 SG_ ErrorRegisterReserved : 22|1@1+ (1,0) [0|0] "" Vector__XXX
 SG_ ErrorRegisterProfileSpecific : 21|1@1+ (1,0) [0|0] "" Vector__XXX
 SG_ ErrorRegisterCommunication : 20|1@1+ (1,0) [0|0] "" Vector__XXX
 SG_ ErrorRegisterTemperature : 19|1@1+ (1,0) [0|0] "" Vector__XXX
 SG_ ErrorRegisterVoltage : 18|1@1+ (1,0) [0|0] "" Vector__XXX
 SG_ ErrorRegisterCurrent : 17|1@1+ (1,0) [0|0] "" Vector__XXX
 SG_ ErrorRegisterGeneric : 16|1@1+ (1,0) [0|0] "" Vector__XXX
 SG_ ErrorCode : 0|16@1+ (1,0) [0|0] "" Vector__XXX

BO_ 127 RED_IndicateActiveCANLine: 0 Vector__XXX

BO_ 118 FM_ForceReset: 0 Vector__XXX

BO_ 117 FM_ReqMasterCapable: 0 Vector__XXX

BO_ 116 FM_RspMasterCapable: 0 Vector__XXX

BO_ 115 FM_ReqPrioLevel: 0 Vector__XXX

BO_ 114 FM_TriggerTimeSlot: 0 Vector__XXX

BO_ 113 FM_MasterPrioLevel: 2 Vector__XXX
 SG_ FM_NodeID : 8|8@1+ (1,0) [0|0] "" Vector__XXX
 SG_ FM_PrioLevel : 0|8@1+ (1,0) [0|0] "" Vector__XXX

BO_ 256 TIME: 6 Vector__XXX
 SG_ days : 32|16@1+ (1,0) [0|65535] "days" Vector__XXX
 SG_ ms : 0|28@1+ (1,0) [0|86399999] "ms" Vector__XXX

BO_ 128 SYNC: 0 Vector__XXX

BO_ 0 NMTZeroMsg: 2 VirtualNMTMaster
 SG_ Node_ID : 8|8@1+ (1,0) [0|0] "" Vector__XXX
 SG_ CS : 0|8@1+ (1,0) [0|0] "" Vector__XXX

BO_ 1760 DynSDOReq: 0 Vector__XXX

BO_ 2021 LSS_M: 8 Vector__XXX
 SG_ LSS_ID_Number m81 : 8|32@1+ (1,0) [0|0] "" Vector__XXX
 SG_ LSS_BitCheck m81 : 40|8@1+ (1,0) [0|0] "" Vector__XXX
 SG_ LSS_Sub m81 : 48|8@1+ (1,0) [0|0] "" Vector__XXX
 SG_ LSS_Next m81 : 56|8@1+ (1,0) [0|0] "" Vector__XXX
 SG_ LSS_SwitchDelay m21 : 8|16@1+ (1,0) [0|0] "" Vector__XXX
 SG_ LSS_CfgNodeID m17 : 8|8@1+ (1,0) [0|0] "" Vector__XXX
 SG_ LSS_IdentSerialHigh m75 : 8|32@1+ (1,0) [0|0] "" Vector__XXX
 SG_ LSS_IdentSerialLow m74 : 8|32@1+ (1,0) [0|0] "" Vector__XXX
 SG_ LSS_IdentRevisionHigh m73 : 8|32@1+ (1,0) [0|0] "" Vector__XXX
 SG_ LSS_IdentRevisionLow m72 : 8|32@1+ (1,0) [0|0] "" Vector__XXX
 SG_ LSS_IdentProductCode m71 : 8|32@1+ (1,0) [0|0] "" Vector__XXX
 SG_ LSS_IdentVendorId m70 : 8|32@1+ (1,0) [0|0] "" Vector__XXX
 SG_ LSS_TableIndex m19 : 16|8@1+ (1,0) [0|0] "" Vector__XXX
 SG_ LSS_TableSelector m19 : 8|8@1+ (1,0) [0|0] "" Vector__XXX
 SG_ LSS_SwitchSerial m67 : 8|32@1+ (1,0) [0|0] "" Vector__XXX
 SG_ LSS_SwitchRevision m66 : 8|32@1+ (1,0) [0|0] "" Vector__XXX
 SG_ LSS_SwitchProductCode m65 : 8|32@1+ (1,0) [0|0] "" Vector__XXX
 SG_ LSS_SwitchVendorId m64 : 8|32@1+ (1,0) [0|0] "" Vector__XXX
 SG_ LSS_Mode m4 : 8|8@1+ (1,0) [0|0] "" Vector__XXX
 SG_ LSS_M_CS M : 0|8@1+ (1,0) [0|0] "" Vector__XXX

BO_ 2020 LSS_S: 8 Vector__XXX
 SG_ LSS_NodeId m94 : 8|8@1+ (1,0) [0|0] "" Vector__XXX
 SG_ LSS_Serial m93 : 8|32@1+ (1,0) [0|0] "" Vector__XXX
 SG_ LSS_Revision m92 : 8|32@1+ (1,0) [0|0] "" Vector__XXX
 SG_ LSS_ProductId m91 : 8|32@1+ (1,0) [0|0] "" Vector__XXX
 SG_ LSS_VendorId m90 : 8|32@1+ (1,0) [0|0] "" Vector__XXX
 SG_ LSS_StoreCfg_SpecErr m23 : 16|8@1+ (1,0) [0|0] "" Vector__XXX
 SG_ LSS_StoreCfg_ErrCode m23 : 8|8@1+ (1,0) [0|0] "" Vector__XXX
 SG_ LSS_CfgBitTim_SpecErr m19 : 16|8@1+ (1,0) [0|0] "" Vector__XXX
 SG_ LSS_CfgBitTim_ErrCode m19 : 8|8@1+ (1,0) [0|0] "" Vector__XXX
 SG_ LSS_CfgNodeID_SpecErr m17 : 16|8@1+ (1,0) [0|0] "" Vector__XXX
 SG_ LSS_CfgNodeID_ErrCode m17 : 8|8@1+ (1,0) [0|0] "" Vector__XXX
 SG_ LSS_S_CS M : 0|8@1+ (1,0) [0|0] "" Vector__XXX

BO_ 1 GFC: 0 Vector__XXX

BO_ 385 N10_TPDO1: 2 I_O_Device_1_ID10
 SG_ Read_Input_8_Bit4 : 8|8@1+ (1,0) [0|0] ""  Master_ID1
 SG_ Read_Input_8_Bit3 : 0|8@1+ (1,0) [0|0] ""  Master_ID1

BO_ 394 N10_TPDO0: 2 I_O_Device_1_ID10
 SG_ Read_Input_8_Bit2 : 8|8@1+ (1,0) [0|0] ""  I_O_Device_2_ID11
 SG_ Read_Input_8_Bit1 : 0|8@1+ (1,0) [0|0] ""  I_O_Device_2_ID11

BA_DEF_ SG_  "GenSigStartValue" INT 0 0;
BA_DEF_ BO_  "CO_MsgCategory" INT 0 0;
BA_DEF_ SG_  "SystemSignalLongSymbol" STRING ;
BA_DEF_DEF_  "GenSigStartValue" 0;
BA_DEF_DEF_  "CO_MsgCategory" 0;
BA_DEF_DEF_  "SystemSignalLongSymbol" "";
BA_ "CO_MsgCategory" BO_ 1418 410;
BA_ "CO_MsgCategory" BO_ 1546 405;
BA_ "CO_MsgCategory" BO_ 138 205;
BA_ "CO_MsgCategory" BO_ 256 115;
BA_ "CO_MsgCategory" BO_ 128 110;
BA_ "CO_MsgCategory" BO_ 0 105;
BA_ "CO_MsgCategory" BO_ 2021 610;
BA_ "CO_MsgCategory" BO_ 2020 605;
BA_ "CO_MsgCategory" BO_ 1 705;
BA_ "CO_MsgCategory" BO_ 385 315;
BA_ "CO_MsgCategory" BO_ 394 305;
BA_ "GenSigStartValue" SG_ 1418 NrOfObjects_6320_00 16;
BA_ "GenSigStartValue" SG_ 1418 NrOfObjects_6300_00 16;
BA_ "GenSigStartValue" SG_ 1418 NrOfObjects_6220_00 64;
BA_ "GenSigStartValue" SG_ 1418 NrOfObjects_6200_00 16;
BA_ "GenSigStartValue" SG_ 1418 NrOfObjects_6120_00 16;
BA_ "GenSigStartValue" SG_ 1418 NrOfObjects_6100_00 16;
BA_ "GenSigStartValue" SG_ 1418 NrOfObjects_6020_00 64;
BA_ "GenSigStartValue" SG_ 1418 NrOfObjects_6000_00 16;
BA_ "GenSigStartValue" SG_ 1418 NrOfObjects_2300_00 4;
BA_ "GenSigStartValue" SG_ 1418 NrOfObjects_2200_00 4;
BA_ "GenSigStartValue" SG_ 1418 mappedObj2_1A01_02 1610613768;
BA_ "GenSigStartValue" SG_ 1418 mappedObj1_1A01_01 1610613512;
BA_ "GenSigStartValue" SG_ 1418 NrOfMappedObjects_1A01_00 2;
BA_ "GenSigStartValue" SG_ 1418 mappedObj2_1A00_02 1610613256;
BA_ "GenSigStartValue" SG_ 1418 mappedObj1_1A00_01 1610613000;
BA_ "GenSigStartValue" SG_ 1418 NrOfMappedObjects_1A00_00 2;
BA_ "GenSigStartValue" SG_ 1418 TransmissionType_1803_02 255;
BA_ "GenSigStartValue" SG_ 1418 COB_ID_1803_01 2147484810;
BA_ "GenSigStartValue" SG_ 1418 Highest_sub_index_supported_0021 5;
BA_ "SystemSignalLongSymbol" SG_ 1418 Highest_sub_index_supported_0021 "Highest_sub_index_supported_1803_00";
BA_ "GenSigStartValue" SG_ 1418 TransmissionType_1802_02 255;
BA_ "GenSigStartValue" SG_ 1418 COB_ID_1802_01 2147484554;
BA_ "GenSigStartValue" SG_ 1418 Highest_sub_index_supported_0022 5;
BA_ "SystemSignalLongSymbol" SG_ 1418 Highest_sub_index_supported_0022 "Highest_sub_index_supported_1802_00";
BA_ "GenSigStartValue" SG_ 1418 TransmissionType_1801_02 255;
BA_ "GenSigStartValue" SG_ 1418 COB_ID_1801_01 385;
BA_ "GenSigStartValue" SG_ 1418 Highest_sub_index_supported_0023 5;
BA_ "SystemSignalLongSymbol" SG_ 1418 Highest_sub_index_supported_0023 "Highest_sub_index_supported_1801_00";
BA_ "GenSigStartValue" SG_ 1418 TransmissionType_1800_02 255;
BA_ "GenSigStartValue" SG_ 1418 COB_ID_1800_01 394;
BA_ "GenSigStartValue" SG_ 1418 Highest_sub_index_supported_0024 5;
BA_ "SystemSignalLongSymbol" SG_ 1418 Highest_sub_index_supported_0024 "Highest_sub_index_supported_1800_00";
BA_ "GenSigStartValue" SG_ 1418 TransmissionType_1403_02 255;
BA_ "GenSigStartValue" SG_ 1418 COB_ID_1403_01 2147484938;
BA_ "GenSigStartValue" SG_ 1418 Highest_sub_index_supported_0025 2;
BA_ "SystemSignalLongSymbol" SG_ 1418 Highest_sub_index_supported_0025 "Highest_sub_index_supported_1403_00";
BA_ "GenSigStartValue" SG_ 1418 TransmissionType_1402_02 255;
BA_ "GenSigStartValue" SG_ 1418 COB_ID_1402_01 2147484682;
BA_ "GenSigStartValue" SG_ 1418 Highest_sub_index_supported_0026 2;
BA_ "SystemSignalLongSymbol" SG_ 1418 Highest_sub_index_supported_0026 "Highest_sub_index_supported_1402_00";
BA_ "GenSigStartValue" SG_ 1418 TransmissionType_1401_02 255;
BA_ "GenSigStartValue" SG_ 1418 COB_ID_1401_01 2147484426;
BA_ "GenSigStartValue" SG_ 1418 Highest_sub_index_supported_0027 2;
BA_ "SystemSignalLongSymbol" SG_ 1418 Highest_sub_index_supported_0027 "Highest_sub_index_supported_1401_00";
BA_ "GenSigStartValue" SG_ 1418 TransmissionType_1400_02 255;
BA_ "GenSigStartValue" SG_ 1418 COB_ID_1400_01 2147484170;
BA_ "GenSigStartValue" SG_ 1418 Highest_sub_index_supported_0028 2;
BA_ "SystemSignalLongSymbol" SG_ 1418 Highest_sub_index_supported_0028 "Highest_sub_index_supported_1400_00";
BA_ "GenSigStartValue" SG_ 1418 Revision_number_1018_03 256;
BA_ "GenSigStartValue" SG_ 1418 Product_Code_1018_02 305419896;
BA_ "GenSigStartValue" SG_ 1418 Vendor_Id_1018_01 5;
BA_ "GenSigStartValue" SG_ 1418 Highest_sub_index_supported_0029 4;
BA_ "SystemSignalLongSymbol" SG_ 1418 Highest_sub_index_supported_0029 "Highest_sub_index_supported_1018_00";
BA_ "SystemSignalLongSymbol" SG_ 1418 Consumer_Heartbeat_Time16_1_0003 "Consumer_Heartbeat_Time16_1016_10";
BA_ "SystemSignalLongSymbol" SG_ 1418 Consumer_Heartbeat_Time15_1_0003 "Consumer_Heartbeat_Time15_1016_0F";
BA_ "SystemSignalLongSymbol" SG_ 1418 Consumer_Heartbeat_Time14_1_0003 "Consumer_Heartbeat_Time14_1016_0E";
BA_ "SystemSignalLongSymbol" SG_ 1418 Consumer_Heartbeat_Time13_1_0003 "Consumer_Heartbeat_Time13_1016_0D";
BA_ "SystemSignalLongSymbol" SG_ 1418 Consumer_Heartbeat_Time12_1_0003 "Consumer_Heartbeat_Time12_1016_0C";
BA_ "SystemSignalLongSymbol" SG_ 1418 Consumer_Heartbeat_Time11_1_0003 "Consumer_Heartbeat_Time11_1016_0B";
BA_ "SystemSignalLongSymbol" SG_ 1418 Consumer_Heartbeat_Time10_1_0003 "Consumer_Heartbeat_Time10_1016_0A";
BA_ "GenSigStartValue" SG_ 1418 NrOfObjects_1016_00 16;
BA_ "GenSigStartValue" SG_ 1418 COB_ID_EMCY_1014 138;
BA_ "SystemSignalLongSymbol" SG_ 1418 Restore_all_Default_Paramet_0003 "Restore_all_Default_Parameters_1011_01";
BA_ "GenSigStartValue" SG_ 1418 Highest_sub_index_supported_0030 1;
BA_ "SystemSignalLongSymbol" SG_ 1418 Highest_sub_index_supported_0030 "Highest_sub_index_supported_1011_00";
BA_ "GenSigStartValue" SG_ 1418 Highest_sub_index_supported_0031 1;
BA_ "SystemSignalLongSymbol" SG_ 1418 Highest_sub_index_supported_0031 "Highest_sub_index_supported_1010_00";
BA_ "GenSigStartValue" SG_ 1418 COB_ID_SYNC_1005 2147483776;
BA_ "GenSigStartValue" SG_ 1418 Device_Type_1000 197009;
BA_ "GenSigStartValue" SG_ 1418 Index 4096;
BA_ "GenSigStartValue" SG_ 1546 NrOfObjects_6320_00 16;
BA_ "GenSigStartValue" SG_ 1546 NrOfObjects_6300_00 16;
BA_ "GenSigStartValue" SG_ 1546 NrOfObjects_6220_00 64;
BA_ "GenSigStartValue" SG_ 1546 NrOfObjects_6200_00 16;
BA_ "GenSigStartValue" SG_ 1546 NrOfObjects_6120_00 16;
BA_ "GenSigStartValue" SG_ 1546 NrOfObjects_6100_00 16;
BA_ "GenSigStartValue" SG_ 1546 NrOfObjects_6020_00 64;
BA_ "GenSigStartValue" SG_ 1546 NrOfObjects_6000_00 16;
BA_ "GenSigStartValue" SG_ 1546 NrOfObjects_2300_00 4;
BA_ "GenSigStartValue" SG_ 1546 NrOfObjects_2200_00 4;
BA_ "GenSigStartValue" SG_ 1546 mappedObj2_1A01_02 1610613768;
BA_ "GenSigStartValue" SG_ 1546 mappedObj1_1A01_01 1610613512;
BA_ "GenSigStartValue" SG_ 1546 NrOfMappedObjects_1A01_00 2;
BA_ "GenSigStartValue" SG_ 1546 mappedObj2_1A00_02 1610613256;
BA_ "GenSigStartValue" SG_ 1546 mappedObj1_1A00_01 1610613000;
BA_ "GenSigStartValue" SG_ 1546 NrOfMappedObjects_1A00_00 2;
BA_ "GenSigStartValue" SG_ 1546 TransmissionType_1803_02 255;
BA_ "GenSigStartValue" SG_ 1546 COB_ID_1803_01 2147484810;
BA_ "GenSigStartValue" SG_ 1546 Highest_sub_index_supported_0032 5;
BA_ "SystemSignalLongSymbol" SG_ 1546 Highest_sub_index_supported_0032 "Highest_sub_index_supported_1803_00";
BA_ "GenSigStartValue" SG_ 1546 TransmissionType_1802_02 255;
BA_ "GenSigStartValue" SG_ 1546 COB_ID_1802_01 2147484554;
BA_ "GenSigStartValue" SG_ 1546 Highest_sub_index_supported_0033 5;
BA_ "SystemSignalLongSymbol" SG_ 1546 Highest_sub_index_supported_0033 "Highest_sub_index_supported_1802_00";
BA_ "GenSigStartValue" SG_ 1546 TransmissionType_1801_02 255;
BA_ "GenSigStartValue" SG_ 1546 COB_ID_1801_01 385;
BA_ "GenSigStartValue" SG_ 1546 Highest_sub_index_supported_0034 5;
BA_ "SystemSignalLongSymbol" SG_ 1546 Highest_sub_index_supported_0034 "Highest_sub_index_supported_1801_00";
BA_ "GenSigStartValue" SG_ 1546 TransmissionType_1800_02 255;
BA_ "GenSigStartValue" SG_ 1546 COB_ID_1800_01 394;
BA_ "GenSigStartValue" SG_ 1546 Highest_sub_index_supported_0035 5;
BA_ "SystemSignalLongSymbol" SG_ 1546 Highest_sub_index_supported_0035 "Highest_sub_index_supported_1800_00";
BA_ "GenSigStartValue" SG_ 1546 TransmissionType_1403_02 255;
BA_ "GenSigStartValue" SG_ 1546 COB_ID_1403_01 2147484938;
BA_ "GenSigStartValue" SG_ 1546 Highest_sub_index_supported_0036 2;
BA_ "SystemSignalLongSymbol" SG_ 1546 Highest_sub_index_supported_0036 "Highest_sub_index_supported_1403_00";
BA_ "GenSigStartValue" SG_ 1546 TransmissionType_1402_02 255;
BA_ "GenSigStartValue" SG_ 1546 COB_ID_1402_01 2147484682;
BA_ "GenSigStartValue" SG_ 1546 Highest_sub_index_supported_0037 2;
BA_ "SystemSignalLongSymbol" SG_ 1546 Highest_sub_index_supported_0037 "Highest_sub_index_supported_1402_00";
BA_ "GenSigStartValue" SG_ 1546 TransmissionType_1401_02 255;
BA_ "GenSigStartValue" SG_ 1546 COB_ID_1401_01 2147484426;
BA_ "GenSigStartValue" SG_ 1546 Highest_sub_index_supported_0038 2;
BA_ "SystemSignalLongSymbol" SG_ 1546 Highest_sub_index_supported_0038 "Highest_sub_index_supported_1401_00";
BA_ "GenSigStartValue" SG_ 1546 TransmissionType_1400_02 255;
BA_ "GenSigStartValue" SG_ 1546 COB_ID_1400_01 2147484170;
BA_ "GenSigStartValue" SG_ 1546 Highest_sub_index_supported_0039 2;
BA_ "SystemSignalLongSymbol" SG_ 1546 Highest_sub_index_supported_0039 "Highest_sub_index_supported_1400_00";
BA_ "GenSigStartValue" SG_ 1546 Revision_number_1018_03 256;
BA_ "GenSigStartValue" SG_ 1546 Product_Code_1018_02 305419896;
BA_ "GenSigStartValue" SG_ 1546 Vendor_Id_1018_01 5;
BA_ "GenSigStartValue" SG_ 1546 Highest_sub_index_supported_0040 4;
BA_ "SystemSignalLongSymbol" SG_ 1546 Highest_sub_index_supported_0040 "Highest_sub_index_supported_1018_00";
BA_ "SystemSignalLongSymbol" SG_ 1546 Consumer_Heartbeat_Time16_1_0004 "Consumer_Heartbeat_Time16_1016_10";
BA_ "SystemSignalLongSymbol" SG_ 1546 Consumer_Heartbeat_Time15_1_0004 "Consumer_Heartbeat_Time15_1016_0F";
BA_ "SystemSignalLongSymbol" SG_ 1546 Consumer_Heartbeat_Time14_1_0004 "Consumer_Heartbeat_Time14_1016_0E";
BA_ "SystemSignalLongSymbol" SG_ 1546 Consumer_Heartbeat_Time13_1_0004 "Consumer_Heartbeat_Time13_1016_0D";
BA_ "SystemSignalLongSymbol" SG_ 1546 Consumer_Heartbeat_Time12_1_0004 "Consumer_Heartbeat_Time12_1016_0C";
BA_ "SystemSignalLongSymbol" SG_ 1546 Consumer_Heartbeat_Time11_1_0004 "Consumer_Heartbeat_Time11_1016_0B";
BA_ "SystemSignalLongSymbol" SG_ 1546 Consumer_Heartbeat_Time10_1_0004 "Consumer_Heartbeat_Time10_1016_0A";
BA_ "GenSigStartValue" SG_ 1546 NrOfObjects_1016_00 16;
BA_ "GenSigStartValue" SG_ 1546 COB_ID_EMCY_1014 138;
BA_ "SystemSignalLongSymbol" SG_ 1546 Restore_all_Default_Paramet_0004 "Restore_all_Default_Parameters_1011_01";
BA_ "GenSigStartValue" SG_ 1546 Highest_sub_index_supported_0041 1;
BA_ "SystemSignalLongSymbol" SG_ 1546 Highest_sub_index_supported_0041 "Highest_sub_index_supported_1011_00";
BA_ "GenSigStartValue" SG_ 1546 Highest_sub_index_supported_0042 1;
BA_ "SystemSignalLongSymbol" SG_ 1546 Highest_sub_index_supported_0042 "Highest_sub_index_supported_1010_00";
BA_ "GenSigStartValue" SG_ 1546 COB_ID_SYNC_1005 2147483776;
BA_ "GenSigStartValue" SG_ 1546 Device_Type_1000 197009;
BA_ "GenSigStartValue" SG_ 1546 Index 4096;
VAL_ 1418 SubIndex_6320 16 "Write Output 32-Bit16" 15 "Write Output 32-Bit15" 14 "Write Output 32-Bit14" 13 "Write Output 32-Bit13" 12 "Write Output 32-Bit12" 11 "Write Output 32-Bit11" 10 "Write Output 32-Bit10" 9 "Write Output 32-Bit9" 8 "Write Output 32-Bit8" 7 "Write Output 32-Bit7" 6 "Write Output 32-Bit6" 5 "Write Output 32-Bit5" 4 "Write Output 32-Bit4" 3 "Write Output 32-Bit3" 2 "Write Output 32-Bit2" 1 "Write Output 32-Bit1" 0 "NrOfObjects" ;
VAL_ 1418 SubIndex_6300 16 "Write Output 16-Bit16" 15 "Write Output 16-Bit15" 14 "Write Output 16-Bit14" 13 "Write Output 16-Bit13" 12 "Write Output 16-Bit12" 11 "Write Output 16-Bit11" 10 "Write Output 16-Bit10" 9 "Write Output 16-Bit9" 8 "Write Output 16-Bit8" 7 "Write Output 16-Bit7" 6 "Write Output 16-Bit6" 5 "Write Output 16-Bit5" 4 "Write Output 16-Bit4" 3 "Write Output 16-Bit3" 2 "Write Output 16-Bit2" 1 "Write Output 16-Bit1" 0 "NrOfObjects" ;
VAL_ 1418 SubIndex_6220 64 "Write Output 1-Bit64" 63 "Write Output 1-Bit63" 62 "Write Output 1-Bit62" 61 "Write Output 1-Bit61" 60 "Write Output 1-Bit60" 59 "Write Output 1-Bit59" 58 "Write Output 1-Bit58" 57 "Write Output 1-Bit57" 56 "Write Output 1-Bit56" 55 "Write Output 1-Bit55" 54 "Write Output 1-Bit54" 53 "Write Output 1-Bit53" 52 "Write Output 1-Bit52" 51 "Write Output 1-Bit51" 50 "Write Output 1-Bit50" 49 "Write Output 1-Bit49" 48 "Write Output 1-Bit48" 47 "Write Output 1-Bit47" 46 "Write Output 1-Bit46" 45 "Write Output 1-Bit45" 44 "Write Output 1-Bit44" 43 "Write Output 1-Bit43" 42 "Write Output 1-Bit42" 41 "Write Output 1-Bit41" 40 "Write Output 1-Bit40" 39 "Write Output 1-Bit39" 38 "Write Output 1-Bit38" 37 "Write Output 1-Bit37" 36 "Write Output 1-Bit36" 35 "Write Output 1-Bit35" 34 "Write Output 1-Bit34" 33 "Write Output 1-Bit33" 32 "Write Output 1-Bit32" 31 "Write Output 1-Bit31" 30 "Write Output 1-Bit30" 29 "Write Output 1-Bit29" 28 "Write Output 1-Bit28" 27 "Write Output 1-Bit27" 26 "Write Output 1-Bit26" 25 "Write Output 1-Bit25" 24 "Write Output 1-Bit24" 23 "Write Output 1-Bit23" 22 "Write Output 1-Bit22" 21 "Write Output 1-Bit21" 20 "Write Output 1-Bit20" 19 "Write Output 1-Bit19" 18 "Write Output 1-Bit18" 17 "Write Output 1-Bit17" 16 "Write Output 1-Bit16" 15 "Write Output 1-Bit15" 14 "Write Output 1-Bit14" 13 "Write Output 1-Bit13" 12 "Write Output 1-Bit12" 11 "Write Output 1-Bit11" 10 "Write Output 1-Bit10" 9 "Write Output 1-Bit9" 8 "Write Output 1-Bit8" 7 "Write Output 1-Bit7" 6 "Write Output 1-Bit6" 5 "Write Output 1-Bit5" 4 "Write Output 1-Bit4" 3 "Write Output 1-Bit3" 2 "Write Output 1-Bit2" 1 "Write Output 1-Bit1" 0 "NrOfObjects" ;
VAL_ 1418 SubIndex_6200 16 "Write Output 8-Bit16" 15 "Write Output 8-Bit15" 14 "Write Output 8-Bit14" 13 "Write Output 8-Bit13" 12 "Write Output 8-Bit12" 11 "Write Output 8-Bit11" 10 "Write Output 8-Bit10" 9 "Write Output 8-Bit9" 8 "Write Output 8-Bit8" 7 "Write Output 8-Bit7" 6 "Write Output 8-Bit6" 5 "Write Output 8-Bit5" 4 "Write Output 8-Bit4" 3 "Write Output 8-Bit3" 2 "Write Output 8-Bit2" 1 "Write Output 8-Bit1" 0 "NrOfObjects" ;
VAL_ 1418 SubIndex_6120 16 "Read Input 32-Bit16" 15 "Read Input 32-Bit15" 14 "Read Input 32-Bit14" 13 "Read Input 32-Bit13" 12 "Read Input 32-Bit12" 11 "Read Input 32-Bit11" 10 "Read Input 32-Bit10" 9 "Read Input 32-Bit9" 8 "Read Input 32-Bit8" 7 "Read Input 32-Bit7" 6 "Read Input 32-Bit6" 5 "Read Input 32-Bit5" 4 "Read Input 32-Bit4" 3 "Read Input 32-Bit3" 2 "Read Input 32-Bit2" 1 "Read Input 32-Bit1" 0 "NrOfObjects" ;
VAL_ 1418 SubIndex_6100 16 "Read Input 16-Bit16" 15 "Read Input 16-Bit15" 14 "Read Input 16-Bit14" 13 "Read Input 16-Bit13" 12 "Read Input 16-Bit12" 11 "Read Input 16-Bit11" 10 "Read Input 16-Bit10" 9 "Read Input 16-Bit9" 8 "Read Input 16-Bit8" 7 "Read Input 16-Bit7" 6 "Read Input 16-Bit6" 5 "Read Input 16-Bit5" 4 "Read Input 16-Bit4" 3 "Read Input 16-Bit3" 2 "Read Input 16-Bit2" 1 "Read Input 16-Bit1" 0 "NrOfObjects" ;
VAL_ 1418 SubIndex_6020 64 "Read Input 1-Bit64" 63 "Read Input 1-Bit63" 62 "Read Input 1-Bit62" 61 "Read Input 1-Bit61" 60 "Read Input 1-Bit60" 59 "Read Input 1-Bit59" 58 "Read Input 1-Bit58" 57 "Read Input 1-Bit57" 56 "Read Input 1-Bit56" 55 "Read Input 1-Bit55" 54 "Read Input 1-Bit54" 53 "Read Input 1-Bit53" 52 "Read Input 1-Bit52" 51 "Read Input 1-Bit51" 50 "Read Input 1-Bit50" 49 "Read Input 1-Bit49" 48 "Read Input 1-Bit48" 47 "Read Input 1-Bit47" 46 "Read Input 1-Bit46" 45 "Read Input 1-Bit45" 44 "Read Input 1-Bit44" 43 "Read Input 1-Bit43" 42 "Read Input 1-Bit42" 41 "Read Input 1-Bit41" 40 "Read Input 1-Bit40" 39 "Read Input 1-Bit39" 38 "Read Input 1-Bit38" 37 "Read Input 1-Bit37" 36 "Read Input 1-Bit36" 35 "Read Input 1-Bit35" 34 "Read Input 1-Bit34" 33 "Read Input 1-Bit33" 32 "Read Input 1-Bit32" 31 "Read Input 1-Bit31" 30 "Read Input 1-Bit30" 29 "Read Input 1-Bit29" 28 "Read Input 1-Bit28" 27 "Read Input 1-Bit27" 26 "Read Input 1-Bit26" 25 "Read Input 1-Bit25" 24 "Read Input 1-Bit24" 23 "Read Input 1-Bit23" 22 "Read Input 1-Bit22" 21 "Read Input 1-Bit21" 20 "Read Input 1-Bit20" 19 "Read Input 1-Bit19" 18 "Read Input 1-Bit18" 17 "Read Input 1-Bit17" 16 "Read Input 1-Bit16" 15 "Read Input 1-Bit15" 14 "Read Input 1-Bit14" 13 "Read Input 1-Bit13" 12 "Read Input 1-Bit12" 11 "Read Input 1-Bit11" 10 "Read Input 1-Bit10" 9 "Read Input 1-Bit9" 8 "Read Input 1-Bit8" 7 "Read Input 1-Bit7" 6 "Read Input 1-Bit6" 5 "Read Input 1-Bit5" 4 "Read Input 1-Bit4" 3 "Read Input 1-Bit3" 2 "Read Input 1-Bit2" 1 "Read Input 1-Bit1" 0 "NrOfObjects" ;
VAL_ 1418 SubIndex_6000 16 "Read Input 8-Bit16" 15 "Read Input 8-Bit15" 14 "Read Input 8-Bit14" 13 "Read Input 8-Bit13" 12 "Read Input 8-Bit12" 11 "Read Input 8-Bit11" 10 "Read Input 8-Bit10" 9 "Read Input 8-Bit9" 8 "Read Input 8-Bit8" 7 "Read Input 8-Bit7" 6 "Read Input 8-Bit6" 5 "Read Input 8-Bit5" 4 "Read Input 8-Bit4" 3 "Read Input 8-Bit3" 2 "Read Input 8-Bit2" 1 "Read Input 8-Bit1" 0 "NrOfObjects" ;
VAL_ 1418 SubIndex_2300 0 "NrOfObjects" ;
VAL_ 1418 SubIndex_2200 0 "NrOfObjects" ;
VAL_ 1418 SubIndex_1A03 0 "NrOfMappedObjects" ;
VAL_ 1418 SubIndex_1A02 0 "NrOfMappedObjects" ;
VAL_ 1418 SubIndex_1A01 2 "mappedObj2" 1 "mappedObj1" 0 "NrOfMappedObjects" ;
VAL_ 1418 SubIndex_1A00 2 "mappedObj2" 1 "mappedObj1" 0 "NrOfMappedObjects" ;
VAL_ 1418 SubIndex_1803 5 "EventTimer" 2 "TransmissionType" 1 "COB-ID" 0 "Highest sub-index supported" ;
VAL_ 1418 SubIndex_1802 5 "EventTimer" 2 "TransmissionType" 1 "COB-ID" 0 "Highest sub-index supported" ;
VAL_ 1418 SubIndex_1801 5 "EventTimer" 2 "TransmissionType" 1 "COB-ID" 0 "Highest sub-index supported" ;
VAL_ 1418 SubIndex_1800 5 "EventTimer" 2 "TransmissionType" 1 "COB-ID" 0 "Highest sub-index supported" ;
VAL_ 1418 SubIndex_1603 0 "NrOfMappedObjects" ;
VAL_ 1418 SubIndex_1602 0 "NrOfMappedObjects" ;
VAL_ 1418 SubIndex_1601 0 "NrOfMappedObjects" ;
VAL_ 1418 SubIndex_1600 0 "NrOfMappedObjects" ;
VAL_ 1418 SubIndex_1403 2 "TransmissionType" 1 "COB-ID" 0 "Highest sub-index supported" ;
VAL_ 1418 SubIndex_1402 2 "TransmissionType" 1 "COB-ID" 0 "Highest sub-index supported" ;
VAL_ 1418 SubIndex_1401 2 "TransmissionType" 1 "COB-ID" 0 "Highest sub-index supported" ;
VAL_ 1418 SubIndex_1400 2 "TransmissionType" 1 "COB-ID" 0 "Highest sub-index supported" ;
VAL_ 1418 SubIndex_1018 4 "Serial number" 3 "Revision number" 2 "Product Code" 1 "Vendor Id" 0 "Highest sub-index supported" ;
VAL_ 1418 SubIndex_1017 0 "Producer Heartbeat Time" ;
VAL_ 1418 SubIndex_1016 16 "Consumer Heartbeat Time16" 15 "Consumer Heartbeat Time15" 14 "Consumer Heartbeat Time14" 13 "Consumer Heartbeat Time13" 12 "Consumer Heartbeat Time12" 11 "Consumer Heartbeat Time11" 10 "Consumer Heartbeat Time10" 9 "Consumer Heartbeat Time9" 8 "Consumer Heartbeat Time8" 7 "Consumer Heartbeat Time7" 6 "Consumer Heartbeat Time6" 5 "Consumer Heartbeat Time5" 4 "Consumer Heartbeat Time4" 3 "Consumer Heartbeat Time3" 2 "Consumer Heartbeat Time2" 1 "Consumer Heartbeat Time1" 0 "NrOfObjects" ;
VAL_ 1418 SubIndex_1014 0 "COB-ID EMCY" ;
VAL_ 1418 SubIndex_1011 1 "Restore all Default Parameters" 0 "Highest sub-index supported" ;
VAL_ 1418 SubIndex_1010 1 "Save all Parameters" 0 "Highest sub-index supported" ;
VAL_ 1418 SubIndex_100D 0 "Life Time Factor" ;
VAL_ 1418 SubIndex_100C 0 "Guard Time" ;
VAL_ 1418 SubIndex_1007 0 "Synchronous Window Length" ;
VAL_ 1418 SubIndex_1006 0 "Communication Cycle Period" ;
VAL_ 1418 SubIndex_1005 0 "COB-ID SYNC" ;
VAL_ 1418 SubIndex_1003 9 "Standard error field" 8 "Standard error field" 7 "Standard error field" 6 "Standard error field" 5 "Standard error field" 4 "Standard error field" 3 "Standard error field" 2 "Standard error field" 1 "Standard error field" 0 "Number of Errors" ;
VAL_ 1418 SubIndex_1001 0 "Error Register" ;
VAL_ 1418 SubIndex_1000 0 "Device Type" ;
VAL_ 1418 Index 25376 "Write Output 32-Bit" 25344 "Write Output 16-Bit" 25120 "Write Output 1-Bit" 25088 "Write Output 8-Bit" 24864 "Read Input 32-Bit" 24832 "Read Input 16-Bit" 24608 "Read Input 1-Bit" 24576 "Read Input 8-Bit" 8960 "Write Output 64-Bit" 8704 "Read Input 64-Bit" 6659 "TxPDOMapping" 6658 "TxPDOMapping" 6657 "TxPDOMapping" 6656 "TxPDOMapping" 6147 "TxPDOComPar" 6146 "TxPDOComPar" 6145 "TxPDOComPar" 6144 "TxPDOComPar" 5635 "RxPDOMapping" 5634 "RxPDOMapping" 5633 "RxPDOMapping" 5632 "RxPDOMapping" 5123 "RxPDOComPar" 5122 "RxPDOComPar" 5121 "RxPDOComPar" 5120 "RxPDOComPar" 4120 "Identity Object" 4119 "Producer Heartbeat Time" 4118 "Consumer Heartbeat Time" 4116 "COB-ID EMCY" 4113 "Restore Default Parameters" 4112 "Store Parameter Field" 4109 "Life Time Factor" 4108 "Guard Time" 4103 "Synchronous Window Length" 4102 "Communication Cycle Period" 4101 "COB-ID SYNC" 4099 "Pre-defined Error Field" 4097 "Error Register" 4096 "Device Type" ;
VAL_ 1418 TransferType 1 "Expedited transfer" 0 "Normal transfer" ;
VAL_ 1418 SizeIndicator 1 "Size is indicated" 0 "Size is not indicated" ;
VAL_ 1418 SCS 2 "Upload" 1 "Download" ;
VAL_ 1546 SubIndex_6320 16 "Write Output 32-Bit16" 15 "Write Output 32-Bit15" 14 "Write Output 32-Bit14" 13 "Write Output 32-Bit13" 12 "Write Output 32-Bit12" 11 "Write Output 32-Bit11" 10 "Write Output 32-Bit10" 9 "Write Output 32-Bit9" 8 "Write Output 32-Bit8" 7 "Write Output 32-Bit7" 6 "Write Output 32-Bit6" 5 "Write Output 32-Bit5" 4 "Write Output 32-Bit4" 3 "Write Output 32-Bit3" 2 "Write Output 32-Bit2" 1 "Write Output 32-Bit1" 0 "NrOfObjects" ;
VAL_ 1546 SubIndex_6300 16 "Write Output 16-Bit16" 15 "Write Output 16-Bit15" 14 "Write Output 16-Bit14" 13 "Write Output 16-Bit13" 12 "Write Output 16-Bit12" 11 "Write Output 16-Bit11" 10 "Write Output 16-Bit10" 9 "Write Output 16-Bit9" 8 "Write Output 16-Bit8" 7 "Write Output 16-Bit7" 6 "Write Output 16-Bit6" 5 "Write Output 16-Bit5" 4 "Write Output 16-Bit4" 3 "Write Output 16-Bit3" 2 "Write Output 16-Bit2" 1 "Write Output 16-Bit1" 0 "NrOfObjects" ;
VAL_ 1546 SubIndex_6220 64 "Write Output 1-Bit64" 63 "Write Output 1-Bit63" 62 "Write Output 1-Bit62" 61 "Write Output 1-Bit61" 60 "Write Output 1-Bit60" 59 "Write Output 1-Bit59" 58 "Write Output 1-Bit58" 57 "Write Output 1-Bit57" 56 "Write Output 1-Bit56" 55 "Write Output 1-Bit55" 54 "Write Output 1-Bit54" 53 "Write Output 1-Bit53" 52 "Write Output 1-Bit52" 51 "Write Output 1-Bit51" 50 "Write Output 1-Bit50" 49 "Write Output 1-Bit49" 48 "Write Output 1-Bit48" 47 "Write Output 1-Bit47" 46 "Write Output 1-Bit46" 45 "Write Output 1-Bit45" 44 "Write Output 1-Bit44" 43 "Write Output 1-Bit43" 42 "Write Output 1-Bit42" 41 "Write Output 1-Bit41" 40 "Write Output 1-Bit40" 39 "Write Output 1-Bit39" 38 "Write Output 1-Bit38" 37 "Write Output 1-Bit37" 36 "Write Output 1-Bit36" 35 "Write Output 1-Bit35" 34 "Write Output 1-Bit34" 33 "Write Output 1-Bit33" 32 "Write Output 1-Bit32" 31 "Write Output 1-Bit31" 30 "Write Output 1-Bit30" 29 "Write Output 1-Bit29" 28 "Write Output 1-Bit28" 27 "Write Output 1-Bit27" 26 "Write Output 1-Bit26" 25 "Write Output 1-Bit25" 24 "Write Output 1-Bit24" 23 "Write Output 1-Bit23" 22 "Write Output 1-Bit22" 21 "Write Output 1-Bit21" 20 "Write Output 1-Bit20" 19 "Write Output 1-Bit19" 18 "Write Output 1-Bit18" 17 "Write Output 1-Bit17" 16 "Write Output 1-Bit16" 15 "Write Output 1-Bit15" 14 "Write Output 1-Bit14" 13 "Write Output 1-Bit13" 12 "Write Output 1-Bit12" 11 "Write Output 1-Bit11" 10 "Write Output 1-Bit10" 9 "Write Output 1-Bit9" 8 "Write Output 1-Bit8" 7 "Write Output 1-Bit7" 6 "Write Output 1-Bit6" 5 "Write Output 1-Bit5" 4 "Write Output 1-Bit4" 3 "Write Output 1-Bit3" 2 "Write Output 1-Bit2" 1 "Write Output 1-Bit1" 0 "NrOfObjects" ;
VAL_ 1546 SubIndex_6200 16 "Write Output 8-Bit16" 15 "Write Output 8-Bit15" 14 "Write Output 8-Bit14" 13 "Write Output 8-Bit13" 12 "Write Output 8-Bit12" 11 "Write Output 8-Bit11" 10 "Write Output 8-Bit10" 9 "Write Output 8-Bit9" 8 "Write Output 8-Bit8" 7 "Write Output 8-Bit7" 6 "Write Output 8-Bit6" 5 "Write Output 8-Bit5" 4 "Write Output 8-Bit4" 3 "Write Output 8-Bit3" 2 "Write Output 8-Bit2" 1 "Write Output 8-Bit1" 0 "NrOfObjects" ;
VAL_ 1546 SubIndex_6120 16 "Read Input 32-Bit16" 15 "Read Input 32-Bit15" 14 "Read Input 32-Bit14" 13 "Read Input 32-Bit13" 12 "Read Input 32-Bit12" 11 "Read Input 32-Bit11" 10 "Read Input 32-Bit10" 9 "Read Input 32-Bit9" 8 "Read Input 32-Bit8" 7 "Read Input 32-Bit7" 6 "Read Input 32-Bit6" 5 "Read Input 32-Bit5" 4 "Read Input 32-Bit4" 3 "Read Input 32-Bit3" 2 "Read Input 32-Bit2" 1 "Read Input 32-Bit1" 0 "NrOfObjects" ;
VAL_ 1546 SubIndex_6100 16 "Read Input 16-Bit16" 15 "Read Input 16-Bit15" 14 "Read Input 16-Bit14" 13 "Read Input 16-Bit13" 12 "Read Input 16-Bit12" 11 "Read Input 16-Bit11" 10 "Read Input 16-Bit10" 9 "Read Input 16-Bit9" 8 "Read Input 16-Bit8" 7 "Read Input 16-Bit7" 6 "Read Input 16-Bit6" 5 "Read Input 16-Bit5" 4 "Read Input 16-Bit4" 3 "Read Input 16-Bit3" 2 "Read Input 16-Bit2" 1 "Read Input 16-Bit1" 0 "NrOfObjects" ;
VAL_ 1546 SubIndex_6020 64 "Read Input 1-Bit64" 63 "Read Input 1-Bit63" 62 "Read Input 1-Bit62" 61 "Read Input 1-Bit61" 60 "Read Input 1-Bit60" 59 "Read Input 1-Bit59" 58 "Read Input 1-Bit58" 57 "Read Input 1-Bit57" 56 "Read Input 1-Bit56" 55 "Read Input 1-Bit55" 54 "Read Input 1-Bit54" 53 "Read Input 1-Bit53" 52 "Read Input 1-Bit52" 51 "Read Input 1-Bit51" 50 "Read Input 1-Bit50" 49 "Read Input 1-Bit49" 48 "Read Input 1-Bit48" 47 "Read Input 1-Bit47" 46 "Read Input 1-Bit46" 45 "Read Input 1-Bit45" 44 "Read Input 1-Bit44" 43 "Read Input 1-Bit43" 42 "Read Input 1-Bit42" 41 "Read Input 1-Bit41" 40 "Read Input 1-Bit40" 39 "Read Input 1-Bit39" 38 "Read Input 1-Bit38" 37 "Read Input 1-Bit37" 36 "Read Input 1-Bit36" 35 "Read Input 1-Bit35" 34 "Read Input 1-Bit34" 33 "Read Input 1-Bit33" 32 "Read Input 1-Bit32" 31 "Read Input 1-Bit31" 30 "Read Input 1-Bit30" 29 "Read Input 1-Bit29" 28 "Read Input 1-Bit28" 27 "Read Input 1-Bit27" 26 "Read Input 1-Bit26" 25 "Read Input 1-Bit25" 24 "Read Input 1-Bit24" 23 "Read Input 1-Bit23" 22 "Read Input 1-Bit22" 21 "Read Input 1-Bit21" 20 "Read Input 1-Bit20" 19 "Read Input 1-Bit19" 18 "Read Input 1-Bit18" 17 "Read Input 1-Bit17" 16 "Read Input 1-Bit16" 15 "Read Input 1-Bit15" 14 "Read Input 1-Bit14" 13 "Read Input 1-Bit13" 12 "Read Input 1-Bit12" 11 "Read Input 1-Bit11" 10 "Read Input 1-Bit10" 9 "Read Input 1-Bit9" 8 "Read Input 1-Bit8" 7 "Read Input 1-Bit7" 6 "Read Input 1-Bit6" 5 "Read Input 1-Bit5" 4 "Read Input 1-Bit4" 3 "Read Input 1-Bit3" 2 "Read Input 1-Bit2" 1 "Read Input 1-Bit1" 0 "NrOfObjects" ;
VAL_ 1546 SubIndex_6000 16 "Read Input 8-Bit16" 15 "Read Input 8-Bit15" 14 "Read Input 8-Bit14" 13 "Read Input 8-Bit13" 12 "Read Input 8-Bit12" 11 "Read Input 8-Bit11" 10 "Read Input 8-Bit10" 9 "Read Input 8-Bit9" 8 "Read Input 8-Bit8" 7 "Read Input 8-Bit7" 6 "Read Input 8-Bit6" 5 "Read Input 8-Bit5" 4 "Read Input 8-Bit4" 3 "Read Input 8-Bit3" 2 "Read Input 8-Bit2" 1 "Read Input 8-Bit1" 0 "NrOfObjects" ;
VAL_ 1546 SubIndex_2300 0 "NrOfObjects" ;
VAL_ 1546 SubIndex_2200 0 "NrOfObjects" ;
VAL_ 1546 SubIndex_1A03 0 "NrOfMappedObjects" ;
VAL_ 1546 SubIndex_1A02 0 "NrOfMappedObjects" ;
VAL_ 1546 SubIndex_1A01 2 "mappedObj2" 1 "mappedObj1" 0 "NrOfMappedObjects" ;
VAL_ 1546 SubIndex_1A00 2 "mappedObj2" 1 "mappedObj1" 0 "NrOfMappedObjects" ;
VAL_ 1546 SubIndex_1803 5 "EventTimer" 2 "TransmissionType" 1 "COB-ID" 0 "Highest sub-index supported" ;
VAL_ 1546 SubIndex_1802 5 "EventTimer" 2 "TransmissionType" 1 "COB-ID" 0 "Highest sub-index supported" ;
VAL_ 1546 SubIndex_1801 5 "EventTimer" 2 "TransmissionType" 1 "COB-ID" 0 "Highest sub-index supported" ;
VAL_ 1546 SubIndex_1800 5 "EventTimer" 2 "TransmissionType" 1 "COB-ID" 0 "Highest sub-index supported" ;
VAL_ 1546 SubIndex_1603 0 "NrOfMappedObjects" ;
VAL_ 1546 SubIndex_1602 0 "NrOfMappedObjects" ;
VAL_ 1546 SubIndex_1601 0 "NrOfMappedObjects" ;
VAL_ 1546 SubIndex_1600 0 "NrOfMappedObjects" ;
VAL_ 1546 SubIndex_1403 2 "TransmissionType" 1 "COB-ID" 0 "Highest sub-index supported" ;
VAL_ 1546 SubIndex_1402 2 "TransmissionType" 1 "COB-ID" 0 "Highest sub-index supported" ;
VAL_ 1546 SubIndex_1401 2 "TransmissionType" 1 "COB-ID" 0 "Highest sub-index supported" ;
VAL_ 1546 SubIndex_1400 2 "TransmissionType" 1 "COB-ID" 0 "Highest sub-index supported" ;
VAL_ 1546 SubIndex_1018 4 "Serial number" 3 "Revision number" 2 "Product Code" 1 "Vendor Id" 0 "Highest sub-index supported" ;
VAL_ 1546 SubIndex_1017 0 "Producer Heartbeat Time" ;
VAL_ 1546 SubIndex_1016 16 "Consumer Heartbeat Time16" 15 "Consumer Heartbeat Time15" 14 "Consumer Heartbeat Time14" 13 "Consumer Heartbeat Time13" 12 "Consumer Heartbeat Time12" 11 "Consumer Heartbeat Time11" 10 "Consumer Heartbeat Time10" 9 "Consumer Heartbeat Time9" 8 "Consumer Heartbeat Time8" 7 "Consumer Heartbeat Time7" 6 "Consumer Heartbeat Time6" 5 "Consumer Heartbeat Time5" 4 "Consumer Heartbeat Time4" 3 "Consumer Heartbeat Time3" 2 "Consumer Heartbeat Time2" 1 "Consumer Heartbeat Time1" 0 "NrOfObjects" ;
VAL_ 1546 SubIndex_1014 0 "COB-ID EMCY" ;
VAL_ 1546 SubIndex_1011 1 "Restore all Default Parameters" 0 "Highest sub-index supported" ;
VAL_ 1546 SubIndex_1010 1 "Save all Parameters" 0 "Highest sub-index supported" ;
VAL_ 1546 SubIndex_100D 0 "Life Time Factor" ;
VAL_ 1546 SubIndex_100C 0 "Guard Time" ;
VAL_ 1546 SubIndex_1007 0 "Synchronous Window Length" ;
VAL_ 1546 SubIndex_1006 0 "Communication Cycle Period" ;
VAL_ 1546 SubIndex_1005 0 "COB-ID SYNC" ;
VAL_ 1546 SubIndex_1003 9 "Standard error field" 8 "Standard error field" 7 "Standard error field" 6 "Standard error field" 5 "Standard error field" 4 "Standard error field" 3 "Standard error field" 2 "Standard error field" 1 "Standard error field" 0 "Number of Errors" ;
VAL_ 1546 SubIndex_1001 0 "Error Register" ;
VAL_ 1546 SubIndex_1000 0 "Device Type" ;
VAL_ 1546 Index 25376 "Write Output 32-Bit" 25344 "Write Output 16-Bit" 25120 "Write Output 1-Bit" 25088 "Write Output 8-Bit" 24864 "Read Input 32-Bit" 24832 "Read Input 16-Bit" 24608 "Read Input 1-Bit" 24576 "Read Input 8-Bit" 8960 "Write Output 64-Bit" 8704 "Read Input 64-Bit" 6659 "TxPDOMapping" 6658 "TxPDOMapping" 6657 "TxPDOMapping" 6656 "TxPDOMapping" 6147 "TxPDOComPar" 6146 "TxPDOComPar" 6145 "TxPDOComPar" 6144 "TxPDOComPar" 5635 "RxPDOMapping" 5634 "RxPDOMapping" 5633 "RxPDOMapping" 5632 "RxPDOMapping" 5123 "RxPDOComPar" 5122 "RxPDOComPar" 5121 "RxPDOComPar" 5120 "RxPDOComPar" 4120 "Identity Object" 4119 "Producer Heartbeat Time" 4118 "Consumer Heartbeat Time" 4116 "COB-ID EMCY" 4113 "Restore Default Parameters" 4112 "Store Parameter Field" 4109 "Life Time Factor" 4108 "Guard Time" 4103 "Synchronous Window Length" 4102 "Communication Cycle Period" 4101 "COB-ID SYNC" 4099 "Pre-defined Error Field" 4097 "Error Register" 4096 "Device Type" ;
VAL_ 1546 TransferType 1 "Expedited transfer" 0 "Normal transfer" ;
VAL_ 1546 SizeIndicator 1 "Size is indicated" 0 "Size is not indicated" ;
VAL_ 1546 CCS 2 "Upload" 1 "Download" ;
VAL_ 138 ErrorCode 13088 "(DS-401) Output voltage too low" 13072 "(DS-401) Output voltage too high" 12832 "(DS-401) Internal voltage too low" 12816 "(DS-401) Internal voltage too high" 12576 "(DS-401) Input voltage too low" 12560 "(DS-401) Input voltage too high" 9008 "(DS-401) Load dump at outputs" 8992 "(DS-401) Short circuit at outputs" 8976 "(DS-401) Current at outputs too high (overload)" 128 "(DS-401) Warning: Analogue inputs disabled" 33360 "RPDO timeout" 33344 "Unexpected SYNC data length" 33328 "DAM MPDO not processed, destination object not available" 33312 "PDO length exceeded" 33296 "PDO not processed due to length error" 33104 "Transmit COB-ID collision" 33088 "Recovered from bus off state" 33072 "Life guard error or heartbeat error" 33056 "CAN in error passive mode" 33040 "CAN overrun (objects lost)" ;
VAL_ 0 Node_ID 1 "Master_ID1" 11 "I_O_Device_2_ID11" 10 "I_O_Device_1_ID10" 0 "All" ;
VAL_ 0 CS 130 "Reset Communication" 129 "Reset Node" 128 "Enter Pre-Operational" 2 "Stop" 1 "Start" ;
VAL_ 2021 LSS_TableIndex 8 "10" 7 "20" 6 "50" 5 "100" 4 "125" 3 "250" 2 "500" 1 "800" 0 "1000" ;
VAL_ 2021 LSS_TableSelector 0 "Std_CiA_Table" ;
VAL_ 2021 LSS_Mode 1 "Configuration" 0 "Operation" ;
VAL_ 2021 LSS_M_CS 94 "InquireNodeID" 93 "InquireSerial" 92 "InquireRevision" 91 "InquireProduct" 90 "InquireVendor" 81 "FastScan" 23 "StoreConfiguration" 21 "ActivateBitTiming" 19 "ConfigureBitTiming" 17 "ConfigureNodeID" 76 "IdentifyNonConfSlave" 75 "IdentifySerialHigh" 74 "IdentifySerialLow" 73 "IdentifyRevisionHigh" 72 "IdentifyRevisionLow" 71 "IdentifyProduct" 70 "IdentifyVendor" 67 "SwitchModeSelectSerial" 66 "SwitchModeSelectRevision" 65 "SwitchModeSelectProduct" 64 "SwitchModeSelectVendor" 4 "SwitchModeGlobal" ;
VAL_ 2020 LSS_StoreCfg_ErrCode 255 "Impl_spec_error" 2 "Storage_media_access_error" 1 "Not_supported" 0 "Success" ;
VAL_ 2020 LSS_CfgBitTim_ErrCode 255 "Impl_spec_error" 1 "Not_supported" 0 "Success" ;
VAL_ 2020 LSS_CfgNodeID_ErrCode 255 "Impl_spec_error" 1 "NodeID_Out_Of_Range" 0 "Success" ;
VAL_ 2020 LSS_S_CS 94 "InquireNodeID" 93 "InquireSerial" 92 "InquireRevision" 91 "InquireProduct" 90 "InquireVendor" 76 "IdentifyNonConfSlave" 79 "IdentifySlave" 23 "StoreConfiguration" 19 "ConfigureBitTiming" 17 "ConfigureNodeID" 68 "SwitchModeSelectConfirm" ;
SG_MUL_VAL_ 1418 Write_Output_32_Bit16_6320_10 SubIndex_6320 16-16;
SG_MUL_VAL_ 1418 Write_Output_32_Bit15_6320_0F SubIndex_6320 15-15;
SG_MUL_VAL_ 1418 Write_Output_32_Bit14_6320_0E SubIndex_6320 14-14;
SG_MUL_VAL_ 1418 Write_Output_32_Bit13_6320_0D SubIndex_6320 13-13;
SG_MUL_VAL_ 1418 Write_Output_32_Bit12_6320_0C SubIndex_6320 12-12;
SG_MUL_VAL_ 1418 Write_Output_32_Bit11_6320_0B SubIndex_6320 11-11;
SG_MUL_VAL_ 1418 Write_Output_32_Bit10_6320_0A SubIndex_6320 10-10;
SG_MUL_VAL_ 1418 Write_Output_32_Bit9_6320_09 SubIndex_6320 9-9;
SG_MUL_VAL_ 1418 Write_Output_32_Bit8_6320_08 SubIndex_6320 8-8;
SG_MUL_VAL_ 1418 Write_Output_32_Bit7_6320_07 SubIndex_6320 7-7;
SG_MUL_VAL_ 1418 Write_Output_32_Bit6_6320_06 SubIndex_6320 6-6;
SG_MUL_VAL_ 1418 Write_Output_32_Bit5_6320_05 SubIndex_6320 5-5;
SG_MUL_VAL_ 1418 Write_Output_32_Bit4_6320_04 SubIndex_6320 4-4;
SG_MUL_VAL_ 1418 Write_Output_32_Bit3_6320_03 SubIndex_6320 3-3;
SG_MUL_VAL_ 1418 Write_Output_32_Bit2_6320_02 SubIndex_6320 2-2;
SG_MUL_VAL_ 1418 Write_Output_32_Bit1_6320_01 SubIndex_6320 1-1;
SG_MUL_VAL_ 1418 NrOfObjects_6320_00 SubIndex_6320 0-0;
SG_MUL_VAL_ 1418 SubIndex_6320 Index 25376-25376;
SG_MUL_VAL_ 1418 Write_Output_16_Bit16_6300_10 SubIndex_6300 16-16;
SG_MUL_VAL_ 1418 Write_Output_16_Bit15_6300_0F SubIndex_6300 15-15;
SG_MUL_VAL_ 1418 Write_Output_16_Bit14_6300_0E SubIndex_6300 14-14;
SG_MUL_VAL_ 1418 Write_Output_16_Bit13_6300_0D SubIndex_6300 13-13;
SG_MUL_VAL_ 1418 Write_Output_16_Bit12_6300_0C SubIndex_6300 12-12;
SG_MUL_VAL_ 1418 Write_Output_16_Bit11_6300_0B SubIndex_6300 11-11;
SG_MUL_VAL_ 1418 Write_Output_16_Bit10_6300_0A SubIndex_6300 10-10;
SG_MUL_VAL_ 1418 Write_Output_16_Bit9_6300_09 SubIndex_6300 9-9;
SG_MUL_VAL_ 1418 Write_Output_16_Bit8_6300_08 SubIndex_6300 8-8;
SG_MUL_VAL_ 1418 Write_Output_16_Bit7_6300_07 SubIndex_6300 7-7;
SG_MUL_VAL_ 1418 Write_Output_16_Bit6_6300_06 SubIndex_6300 6-6;
SG_MUL_VAL_ 1418 Write_Output_16_Bit5_6300_05 SubIndex_6300 5-5;
SG_MUL_VAL_ 1418 Write_Output_16_Bit4_6300_04 SubIndex_6300 4-4;
SG_MUL_VAL_ 1418 Write_Output_16_Bit3_6300_03 SubIndex_6300 3-3;
SG_MUL_VAL_ 1418 Write_Output_16_Bit2_6300_02 SubIndex_6300 2-2;
SG_MUL_VAL_ 1418 Write_Output_16_Bit1_6300_01 SubIndex_6300 1-1;
SG_MUL_VAL_ 1418 NrOfObjects_6300_00 SubIndex_6300 0-0;
SG_MUL_VAL_ 1418 SubIndex_6300 Index 25344-25344;
SG_MUL_VAL_ 1418 Write_Output_1_Bit64_6220_40 SubIndex_6220 64-64;
SG_MUL_VAL_ 1418 Write_Output_1_Bit63_6220_3F SubIndex_6220 63-63;
SG_MUL_VAL_ 1418 Write_Output_1_Bit62_6220_3E SubIndex_6220 62-62;
SG_MUL_VAL_ 1418 Write_Output_1_Bit61_6220_3D SubIndex_6220 61-61;
SG_MUL_VAL_ 1418 Write_Output_1_Bit60_6220_3C SubIndex_6220 60-60;
SG_MUL_VAL_ 1418 Write_Output_1_Bit59_6220_3B SubIndex_6220 59-59;
SG_MUL_VAL_ 1418 Write_Output_1_Bit58_6220_3A SubIndex_6220 58-58;
SG_MUL_VAL_ 1418 Write_Output_1_Bit57_6220_39 SubIndex_6220 57-57;
SG_MUL_VAL_ 1418 Write_Output_1_Bit56_6220_38 SubIndex_6220 56-56;
SG_MUL_VAL_ 1418 Write_Output_1_Bit55_6220_37 SubIndex_6220 55-55;
SG_MUL_VAL_ 1418 Write_Output_1_Bit54_6220_36 SubIndex_6220 54-54;
SG_MUL_VAL_ 1418 Write_Output_1_Bit53_6220_35 SubIndex_6220 53-53;
SG_MUL_VAL_ 1418 Write_Output_1_Bit52_6220_34 SubIndex_6220 52-52;
SG_MUL_VAL_ 1418 Write_Output_1_Bit51_6220_33 SubIndex_6220 51-51;
SG_MUL_VAL_ 1418 Write_Output_1_Bit50_6220_32 SubIndex_6220 50-50;
SG_MUL_VAL_ 1418 Write_Output_1_Bit49_6220_31 SubIndex_6220 49-49;
SG_MUL_VAL_ 1418 Write_Output_1_Bit48_6220_30 SubIndex_6220 48-48;
SG_MUL_VAL_ 1418 Write_Output_1_Bit47_6220_2F SubIndex_6220 47-47;
SG_MUL_VAL_ 1418 Write_Output_1_Bit46_6220_2E SubIndex_6220 46-46;
SG_MUL_VAL_ 1418 Write_Output_1_Bit45_6220_2D SubIndex_6220 45-45;
SG_MUL_VAL_ 1418 Write_Output_1_Bit44_6220_2C SubIndex_6220 44-44;
SG_MUL_VAL_ 1418 Write_Output_1_Bit43_6220_2B SubIndex_6220 43-43;
SG_MUL_VAL_ 1418 Write_Output_1_Bit42_6220_2A SubIndex_6220 42-42;
SG_MUL_VAL_ 1418 Write_Output_1_Bit41_6220_29 SubIndex_6220 41-41;
SG_MUL_VAL_ 1418 Write_Output_1_Bit40_6220_28 SubIndex_6220 40-40;
SG_MUL_VAL_ 1418 Write_Output_1_Bit39_6220_27 SubIndex_6220 39-39;
SG_MUL_VAL_ 1418 Write_Output_1_Bit38_6220_26 SubIndex_6220 38-38;
SG_MUL_VAL_ 1418 Write_Output_1_Bit37_6220_25 SubIndex_6220 37-37;
SG_MUL_VAL_ 1418 Write_Output_1_Bit36_6220_24 SubIndex_6220 36-36;
SG_MUL_VAL_ 1418 Write_Output_1_Bit35_6220_23 SubIndex_6220 35-35;
SG_MUL_VAL_ 1418 Write_Output_1_Bit34_6220_22 SubIndex_6220 34-34;
SG_MUL_VAL_ 1418 Write_Output_1_Bit33_6220_21 SubIndex_6220 33-33;
SG_MUL_VAL_ 1418 Write_Output_1_Bit32_6220_20 SubIndex_6220 32-32;
SG_MUL_VAL_ 1418 Write_Output_1_Bit31_6220_1F SubIndex_6220 31-31;
SG_MUL_VAL_ 1418 Write_Output_1_Bit30_6220_1E SubIndex_6220 30-30;
SG_MUL_VAL_ 1418 Write_Output_1_Bit29_6220_1D SubIndex_6220 29-29;
SG_MUL_VAL_ 1418 Write_Output_1_Bit28_6220_1C SubIndex_6220 28-28;
SG_MUL_VAL_ 1418 Write_Output_1_Bit27_6220_1B SubIndex_6220 27-27;
SG_MUL_VAL_ 1418 Write_Output_1_Bit26_6220_1A SubIndex_6220 26-26;
SG_MUL_VAL_ 1418 Write_Output_1_Bit25_6220_19 SubIndex_6220 25-25;
SG_MUL_VAL_ 1418 Write_Output_1_Bit24_6220_18 SubIndex_6220 24-24;
SG_MUL_VAL_ 1418 Write_Output_1_Bit23_6220_17 SubIndex_6220 23-23;
SG_MUL_VAL_ 1418 Write_Output_1_Bit22_6220_16 SubIndex_6220 22-22;
SG_MUL_VAL_ 1418 Write_Output_1_Bit21_6220_15 SubIndex_6220 21-21;
SG_MUL_VAL_ 1418 Write_Output_1_Bit20_6220_14 SubIndex_6220 20-20;
SG_MUL_VAL_ 1418 Write_Output_1_Bit19_6220_13 SubIndex_6220 19-19;
SG_MUL_VAL_ 1418 Write_Output_1_Bit18_6220_12 SubIndex_6220 18-18;
SG_MUL_VAL_ 1418 Write_Output_1_Bit17_6220_11 SubIndex_6220 17-17;
SG_MUL_VAL_ 1418 Write_Output_1_Bit16_6220_10 SubIndex_6220 16-16;
SG_MUL_VAL_ 1418 Write_Output_1_Bit15_6220_0F SubIndex_6220 15-15;
SG_MUL_VAL_ 1418 Write_Output_1_Bit14_6220_0E SubIndex_6220 14-14;
SG_MUL_VAL_ 1418 Write_Output_1_Bit13_6220_0D SubIndex_6220 13-13;
SG_MUL_VAL_ 1418 Write_Output_1_Bit12_6220_0C SubIndex_6220 12-12;
SG_MUL_VAL_ 1418 Write_Output_1_Bit11_6220_0B SubIndex_6220 11-11;
SG_MUL_VAL_ 1418 Write_Output_1_Bit10_6220_0A SubIndex_6220 10-10;
SG_MUL_VAL_ 1418 Write_Output_1_Bit9_6220_09 SubIndex_6220 9-9;
SG_MUL_VAL_ 1418 Write_Output_1_Bit8_6220_08 SubIndex_6220 8-8;
SG_MUL_VAL_ 1418 Write_Output_1_Bit7_6220_07 SubIndex_6220 7-7;
SG_MUL_VAL_ 1418 Write_Output_1_Bit6_6220_06 SubIndex_6220 6-6;
SG_MUL_VAL_ 1418 Write_Output_1_Bit5_6220_05 SubIndex_6220 5-5;
SG_MUL_VAL_ 1418 Write_Output_1_Bit4_6220_04 SubIndex_6220 4-4;
SG_MUL_VAL_ 1418 Write_Output_1_Bit3_6220_03 SubIndex_6220 3-3;
SG_MUL_VAL_ 1418 Write_Output_1_Bit2_6220_02 SubIndex_6220 2-2;
SG_MUL_VAL_ 1418 Write_Output_1_Bit1_6220_01 SubIndex_6220 1-1;
SG_MUL_VAL_ 1418 NrOfObjects_6220_00 SubIndex_6220 0-0;
SG_MUL_VAL_ 1418 SubIndex_6220 Index 25120-25120;
SG_MUL_VAL_ 1418 Write_Output_8_Bit16_6200_10 SubIndex_6200 16-16;
SG_MUL_VAL_ 1418 Write_Output_8_Bit15_6200_0F SubIndex_6200 15-15;
SG_MUL_VAL_ 1418 Write_Output_8_Bit14_6200_0E SubIndex_6200 14-14;
SG_MUL_VAL_ 1418 Write_Output_8_Bit13_6200_0D SubIndex_6200 13-13;
SG_MUL_VAL_ 1418 Write_Output_8_Bit12_6200_0C SubIndex_6200 12-12;
SG_MUL_VAL_ 1418 Write_Output_8_Bit11_6200_0B SubIndex_6200 11-11;
SG_MUL_VAL_ 1418 Write_Output_8_Bit10_6200_0A SubIndex_6200 10-10;
SG_MUL_VAL_ 1418 Write_Output_8_Bit9_6200_09 SubIndex_6200 9-9;
SG_MUL_VAL_ 1418 Write_Output_8_Bit8_6200_08 SubIndex_6200 8-8;
SG_MUL_VAL_ 1418 Write_Output_8_Bit7_6200_07 SubIndex_6200 7-7;
SG_MUL_VAL_ 1418 Write_Output_8_Bit6_6200_06 SubIndex_6200 6-6;
SG_MUL_VAL_ 1418 Write_Output_8_Bit5_6200_05 SubIndex_6200 5-5;
SG_MUL_VAL_ 1418 Write_Output_8_Bit4_6200_04 SubIndex_6200 4-4;
SG_MUL_VAL_ 1418 Write_Output_8_Bit3_6200_03 SubIndex_6200 3-3;
SG_MUL_VAL_ 1418 Write_Output_8_Bit2_6200_02 SubIndex_6200 2-2;
SG_MUL_VAL_ 1418 Write_Output_8_Bit1_6200_01 SubIndex_6200 1-1;
SG_MUL_VAL_ 1418 NrOfObjects_6200_00 SubIndex_6200 0-0;
SG_MUL_VAL_ 1418 SubIndex_6200 Index 25088-25088;
SG_MUL_VAL_ 1418 Read_Input_32_Bit16_6120_10 SubIndex_6120 16-16;
SG_MUL_VAL_ 1418 Read_Input_32_Bit15_6120_0F SubIndex_6120 15-15;
SG_MUL_VAL_ 1418 Read_Input_32_Bit14_6120_0E SubIndex_6120 14-14;
SG_MUL_VAL_ 1418 Read_Input_32_Bit13_6120_0D SubIndex_6120 13-13;
SG_MUL_VAL_ 1418 Read_Input_32_Bit12_6120_0C SubIndex_6120 12-12;
SG_MUL_VAL_ 1418 Read_Input_32_Bit11_6120_0B SubIndex_6120 11-11;
SG_MUL_VAL_ 1418 Read_Input_32_Bit10_6120_0A SubIndex_6120 10-10;
SG_MUL_VAL_ 1418 Read_Input_32_Bit9_6120_09 SubIndex_6120 9-9;
SG_MUL_VAL_ 1418 Read_Input_32_Bit8_6120_08 SubIndex_6120 8-8;
SG_MUL_VAL_ 1418 Read_Input_32_Bit7_6120_07 SubIndex_6120 7-7;
SG_MUL_VAL_ 1418 Read_Input_32_Bit6_6120_06 SubIndex_6120 6-6;
SG_MUL_VAL_ 1418 Read_Input_32_Bit5_6120_05 SubIndex_6120 5-5;
SG_MUL_VAL_ 1418 Read_Input_32_Bit4_6120_04 SubIndex_6120 4-4;
SG_MUL_VAL_ 1418 Read_Input_32_Bit3_6120_03 SubIndex_6120 3-3;
SG_MUL_VAL_ 1418 Read_Input_32_Bit2_6120_02 SubIndex_6120 2-2;
SG_MUL_VAL_ 1418 Read_Input_32_Bit1_6120_01 SubIndex_6120 1-1;
SG_MUL_VAL_ 1418 NrOfObjects_6120_00 SubIndex_6120 0-0;
SG_MUL_VAL_ 1418 SubIndex_6120 Index 24864-24864;
SG_MUL_VAL_ 1418 Read_Input_16_Bit16_6100_10 SubIndex_6100 16-16;
SG_MUL_VAL_ 1418 Read_Input_16_Bit15_6100_0F SubIndex_6100 15-15;
SG_MUL_VAL_ 1418 Read_Input_16_Bit14_6100_0E SubIndex_6100 14-14;
SG_MUL_VAL_ 1418 Read_Input_16_Bit13_6100_0D SubIndex_6100 13-13;
SG_MUL_VAL_ 1418 Read_Input_16_Bit12_6100_0C SubIndex_6100 12-12;
SG_MUL_VAL_ 1418 Read_Input_16_Bit11_6100_0B SubIndex_6100 11-11;
SG_MUL_VAL_ 1418 Read_Input_16_Bit10_6100_0A SubIndex_6100 10-10;
SG_MUL_VAL_ 1418 Read_Input_16_Bit9_6100_09 SubIndex_6100 9-9;
SG_MUL_VAL_ 1418 Read_Input_16_Bit8_6100_08 SubIndex_6100 8-8;
SG_MUL_VAL_ 1418 Read_Input_16_Bit7_6100_07 SubIndex_6100 7-7;
SG_MUL_VAL_ 1418 Read_Input_16_Bit6_6100_06 SubIndex_6100 6-6;
SG_MUL_VAL_ 1418 Read_Input_16_Bit5_6100_05 SubIndex_6100 5-5;
SG_MUL_VAL_ 1418 Read_Input_16_Bit4_6100_04 SubIndex_6100 4-4;
SG_MUL_VAL_ 1418 Read_Input_16_Bit3_6100_03 SubIndex_6100 3-3;
SG_MUL_VAL_ 1418 Read_Input_16_Bit2_6100_02 SubIndex_6100 2-2;
SG_MUL_VAL_ 1418 Read_Input_16_Bit1_6100_01 SubIndex_6100 1-1;
SG_MUL_VAL_ 1418 NrOfObjects_6100_00 SubIndex_6100 0-0;
SG_MUL_VAL_ 1418 SubIndex_6100 Index 24832-24832;
SG_MUL_VAL_ 1418 Read_Input_1_Bit64_6020_40 SubIndex_6020 64-64;
SG_MUL_VAL_ 1418 Read_Input_1_Bit63_6020_3F SubIndex_6020 63-63;
SG_MUL_VAL_ 1418 Read_Input_1_Bit62_6020_3E SubIndex_6020 62-62;
SG_MUL_VAL_ 1418 Read_Input_1_Bit61_6020_3D SubIndex_6020 61-61;
SG_MUL_VAL_ 1418 Read_Input_1_Bit60_6020_3C SubIndex_6020 60-60;
SG_MUL_VAL_ 1418 Read_Input_1_Bit59_6020_3B SubIndex_6020 59-59;
SG_MUL_VAL_ 1418 Read_Input_1_Bit58_6020_3A SubIndex_6020 58-58;
SG_MUL_VAL_ 1418 Read_Input_1_Bit57_6020_39 SubIndex_6020 57-57;
SG_MUL_VAL_ 1418 Read_Input_1_Bit56_6020_38 SubIndex_6020 56-56;
SG_MUL_VAL_ 1418 Read_Input_1_Bit55_6020_37 SubIndex_6020 55-55;
SG_MUL_VAL_ 1418 Read_Input_1_Bit54_6020_36 SubIndex_6020 54-54;
SG_MUL_VAL_ 1418 Read_Input_1_Bit53_6020_35 SubIndex_6020 53-53;
SG_MUL_VAL_ 1418 Read_Input_1_Bit52_6020_34 SubIndex_6020 52-52;
SG_MUL_VAL_ 1418 Read_Input_1_Bit51_6020_33 SubIndex_6020 51-51;
SG_MUL_VAL_ 1418 Read_Input_1_Bit50_6020_32 SubIndex_6020 50-50;
SG_MUL_VAL_ 1418 Read_Input_1_Bit49_6020_31 SubIndex_6020 49-49;
SG_MUL_VAL_ 1418 Read_Input_1_Bit48_6020_30 SubIndex_6020 48-48;
SG_MUL_VAL_ 1418 Read_Input_1_Bit47_6020_2F SubIndex_6020 47-47;
SG_MUL_VAL_ 1418 Read_Input_1_Bit46_6020_2E SubIndex_6020 46-46;
SG_MUL_VAL_ 1418 Read_Input_1_Bit45_6020_2D SubIndex_6020 45-45;
SG_MUL_VAL_ 1418 Read_Input_1_Bit44_6020_2C SubIndex_6020 44-44;
SG_MUL_VAL_ 1418 Read_Input_1_Bit43_6020_2B SubIndex_6020 43-43;
SG_MUL_VAL_ 1418 Read_Input_1_Bit42_6020_2A SubIndex_6020 42-42;
SG_MUL_VAL_ 1418 Read_Input_1_Bit41_6020_29 SubIndex_6020 41-41;
SG_MUL_VAL_ 1418 Read_Input_1_Bit40_6020_28 SubIndex_6020 40-40;
SG_MUL_VAL_ 1418 Read_Input_1_Bit39_6020_27 SubIndex_6020 39-39;
SG_MUL_VAL_ 1418 Read_Input_1_Bit38_6020_26 SubIndex_6020 38-38;
SG_MUL_VAL_ 1418 Read_Input_1_Bit37_6020_25 SubIndex_6020 37-37;
SG_MUL_VAL_ 1418 Read_Input_1_Bit36_6020_24 SubIndex_6020 36-36;
SG_MUL_VAL_ 1418 Read_Input_1_Bit35_6020_23 SubIndex_6020 35-35;
SG_MUL_VAL_ 1418 Read_Input_1_Bit34_6020_22 SubIndex_6020 34-34;
SG_MUL_VAL_ 1418 Read_Input_1_Bit33_6020_21 SubIndex_6020 33-33;
SG_MUL_VAL_ 1418 Read_Input_1_Bit32_6020_20 SubIndex_6020 32-32;
SG_MUL_VAL_ 1418 Read_Input_1_Bit31_6020_1F SubIndex_6020 31-31;
SG_MUL_VAL_ 1418 Read_Input_1_Bit30_6020_1E SubIndex_6020 30-30;
SG_MUL_VAL_ 1418 Read_Input_1_Bit29_6020_1D SubIndex_6020 29-29;
SG_MUL_VAL_ 1418 Read_Input_1_Bit28_6020_1C SubIndex_6020 28-28;
SG_MUL_VAL_ 1418 Read_Input_1_Bit27_6020_1B SubIndex_6020 27-27;
SG_MUL_VAL_ 1418 Read_Input_1_Bit26_6020_1A SubIndex_6020 26-26;
SG_MUL_VAL_ 1418 Read_Input_1_Bit25_6020_19 SubIndex_6020 25-25;
SG_MUL_VAL_ 1418 Read_Input_1_Bit24_6020_18 SubIndex_6020 24-24;
SG_MUL_VAL_ 1418 Read_Input_1_Bit23_6020_17 SubIndex_6020 23-23;
SG_MUL_VAL_ 1418 Read_Input_1_Bit22_6020_16 SubIndex_6020 22-22;
SG_MUL_VAL_ 1418 Read_Input_1_Bit21_6020_15 SubIndex_6020 21-21;
SG_MUL_VAL_ 1418 Read_Input_1_Bit20_6020_14 SubIndex_6020 20-20;
SG_MUL_VAL_ 1418 Read_Input_1_Bit19_6020_13 SubIndex_6020 19-19;
SG_MUL_VAL_ 1418 Read_Input_1_Bit18_6020_12 SubIndex_6020 18-18;
SG_MUL_VAL_ 1418 Read_Input_1_Bit17_6020_11 SubIndex_6020 17-17;
SG_MUL_VAL_ 1418 Read_Input_1_Bit16_6020_10 SubIndex_6020 16-16;
SG_MUL_VAL_ 1418 Read_Input_1_Bit15_6020_0F SubIndex_6020 15-15;
SG_MUL_VAL_ 1418 Read_Input_1_Bit14_6020_0E SubIndex_6020 14-14;
SG_MUL_VAL_ 1418 Read_Input_1_Bit13_6020_0D SubIndex_6020 13-13;
SG_MUL_VAL_ 1418 Read_Input_1_Bit12_6020_0C SubIndex_6020 12-12;
SG_MUL_VAL_ 1418 Read_Input_1_Bit11_6020_0B SubIndex_6020 11-11;
SG_MUL_VAL_ 1418 Read_Input_1_Bit10_6020_0A SubIndex_6020 10-10;
SG_MUL_VAL_ 1418 Read_Input_1_Bit9_6020_09 SubIndex_6020 9-9;
SG_MUL_VAL_ 1418 Read_Input_1_Bit8_6020_08 SubIndex_6020 8-8;
SG_MUL_VAL_ 1418 Read_Input_1_Bit7_6020_07 SubIndex_6020 7-7;
SG_MUL_VAL_ 1418 Read_Input_1_Bit6_6020_06 SubIndex_6020 6-6;
SG_MUL_VAL_ 1418 Read_Input_1_Bit5_6020_05 SubIndex_6020 5-5;
SG_MUL_VAL_ 1418 Read_Input_1_Bit4_6020_04 SubIndex_6020 4-4;
SG_MUL_VAL_ 1418 Read_Input_1_Bit3_6020_03 SubIndex_6020 3-3;
SG_MUL_VAL_ 1418 Read_Input_1_Bit2_6020_02 SubIndex_6020 2-2;
SG_MUL_VAL_ 1418 Read_Input_1_Bit1_6020_01 SubIndex_6020 1-1;
SG_MUL_VAL_ 1418 NrOfObjects_6020_00 SubIndex_6020 0-0;
SG_MUL_VAL_ 1418 SubIndex_6020 Index 24608-24608;
SG_MUL_VAL_ 1418 Read_Input_8_Bit16_6000_10 SubIndex_6000 16-16;
SG_MUL_VAL_ 1418 Read_Input_8_Bit15_6000_0F SubIndex_6000 15-15;
SG_MUL_VAL_ 1418 Read_Input_8_Bit14_6000_0E SubIndex_6000 14-14;
SG_MUL_VAL_ 1418 Read_Input_8_Bit13_6000_0D SubIndex_6000 13-13;
SG_MUL_VAL_ 1418 Read_Input_8_Bit12_6000_0C SubIndex_6000 12-12;
SG_MUL_VAL_ 1418 Read_Input_8_Bit11_6000_0B SubIndex_6000 11-11;
SG_MUL_VAL_ 1418 Read_Input_8_Bit10_6000_0A SubIndex_6000 10-10;
SG_MUL_VAL_ 1418 Read_Input_8_Bit9_6000_09 SubIndex_6000 9-9;
SG_MUL_VAL_ 1418 Read_Input_8_Bit8_6000_08 SubIndex_6000 8-8;
SG_MUL_VAL_ 1418 Read_Input_8_Bit7_6000_07 SubIndex_6000 7-7;
SG_MUL_VAL_ 1418 Read_Input_8_Bit6_6000_06 SubIndex_6000 6-6;
SG_MUL_VAL_ 1418 Read_Input_8_Bit5_6000_05 SubIndex_6000 5-5;
SG_MUL_VAL_ 1418 Read_Input_8_Bit4_6000_04 SubIndex_6000 4-4;
SG_MUL_VAL_ 1418 Read_Input_8_Bit3_6000_03 SubIndex_6000 3-3;
SG_MUL_VAL_ 1418 Read_Input_8_Bit2_6000_02 SubIndex_6000 2-2;
SG_MUL_VAL_ 1418 Read_Input_8_Bit1_6000_01 SubIndex_6000 1-1;
SG_MUL_VAL_ 1418 NrOfObjects_6000_00 SubIndex_6000 0-0;
SG_MUL_VAL_ 1418 SubIndex_6000 Index 24576-24576;
SG_MUL_VAL_ 1418 NrOfObjects_2300_00 SubIndex_2300 0-0;
SG_MUL_VAL_ 1418 SubIndex_2300 Index 8960-8960;
SG_MUL_VAL_ 1418 NrOfObjects_2200_00 SubIndex_2200 0-0;
SG_MUL_VAL_ 1418 SubIndex_2200 Index 8704-8704;
SG_MUL_VAL_ 1418 NrOfMappedObjects_1A03_00 SubIndex_1A03 0-0;
SG_MUL_VAL_ 1418 SubIndex_1A03 Index 6659-6659;
SG_MUL_VAL_ 1418 NrOfMappedObjects_1A02_00 SubIndex_1A02 0-0;
SG_MUL_VAL_ 1418 SubIndex_1A02 Index 6658-6658;
SG_MUL_VAL_ 1418 mappedObj2_1A01_02 SubIndex_1A01 2-2;
SG_MUL_VAL_ 1418 mappedObj1_1A01_01 SubIndex_1A01 1-1;
SG_MUL_VAL_ 1418 NrOfMappedObjects_1A01_00 SubIndex_1A01 0-0;
SG_MUL_VAL_ 1418 SubIndex_1A01 Index 6657-6657;
SG_MUL_VAL_ 1418 mappedObj2_1A00_02 SubIndex_1A00 2-2;
SG_MUL_VAL_ 1418 mappedObj1_1A00_01 SubIndex_1A00 1-1;
SG_MUL_VAL_ 1418 NrOfMappedObjects_1A00_00 SubIndex_1A00 0-0;
SG_MUL_VAL_ 1418 SubIndex_1A00 Index 6656-6656;
SG_MUL_VAL_ 1418 EventTimer_1803_05 SubIndex_1803 5-5;
SG_MUL_VAL_ 1418 TransmissionType_1803_02 SubIndex_1803 2-2;
SG_MUL_VAL_ 1418 COB_ID_1803_01 SubIndex_1803 1-1;
SG_MUL_VAL_ 1418 Highest_sub_index_supported_0021 SubIndex_1803 0-0;
SG_MUL_VAL_ 1418 SubIndex_1803 Index 6147-6147;
SG_MUL_VAL_ 1418 EventTimer_1802_05 SubIndex_1802 5-5;
SG_MUL_VAL_ 1418 TransmissionType_1802_02 SubIndex_1802 2-2;
SG_MUL_VAL_ 1418 COB_ID_1802_01 SubIndex_1802 1-1;
SG_MUL_VAL_ 1418 Highest_sub_index_supported_0022 SubIndex_1802 0-0;
SG_MUL_VAL_ 1418 SubIndex_1802 Index 6146-6146;
SG_MUL_VAL_ 1418 EventTimer_1801_05 SubIndex_1801 5-5;
SG_MUL_VAL_ 1418 TransmissionType_1801_02 SubIndex_1801 2-2;
SG_MUL_VAL_ 1418 COB_ID_1801_01 SubIndex_1801 1-1;
SG_MUL_VAL_ 1418 Highest_sub_index_supported_0023 SubIndex_1801 0-0;
SG_MUL_VAL_ 1418 SubIndex_1801 Index 6145-6145;
SG_MUL_VAL_ 1418 EventTimer_1800_05 SubIndex_1800 5-5;
SG_MUL_VAL_ 1418 TransmissionType_1800_02 SubIndex_1800 2-2;
SG_MUL_VAL_ 1418 COB_ID_1800_01 SubIndex_1800 1-1;
SG_MUL_VAL_ 1418 Highest_sub_index_supported_0024 SubIndex_1800 0-0;
SG_MUL_VAL_ 1418 SubIndex_1800 Index 6144-6144;
SG_MUL_VAL_ 1418 NrOfMappedObjects_1603_00 SubIndex_1603 0-0;
SG_MUL_VAL_ 1418 SubIndex_1603 Index 5635-5635;
SG_MUL_VAL_ 1418 NrOfMappedObjects_1602_00 SubIndex_1602 0-0;
SG_MUL_VAL_ 1418 SubIndex_1602 Index 5634-5634;
SG_MUL_VAL_ 1418 NrOfMappedObjects_1601_00 SubIndex_1601 0-0;
SG_MUL_VAL_ 1418 SubIndex_1601 Index 5633-5633;
SG_MUL_VAL_ 1418 NrOfMappedObjects_1600_00 SubIndex_1600 0-0;
SG_MUL_VAL_ 1418 SubIndex_1600 Index 5632-5632;
SG_MUL_VAL_ 1418 TransmissionType_1403_02 SubIndex_1403 2-2;
SG_MUL_VAL_ 1418 COB_ID_1403_01 SubIndex_1403 1-1;
SG_MUL_VAL_ 1418 Highest_sub_index_supported_0025 SubIndex_1403 0-0;
SG_MUL_VAL_ 1418 SubIndex_1403 Index 5123-5123;
SG_MUL_VAL_ 1418 TransmissionType_1402_02 SubIndex_1402 2-2;
SG_MUL_VAL_ 1418 COB_ID_1402_01 SubIndex_1402 1-1;
SG_MUL_VAL_ 1418 Highest_sub_index_supported_0026 SubIndex_1402 0-0;
SG_MUL_VAL_ 1418 SubIndex_1402 Index 5122-5122;
SG_MUL_VAL_ 1418 TransmissionType_1401_02 SubIndex_1401 2-2;
SG_MUL_VAL_ 1418 COB_ID_1401_01 SubIndex_1401 1-1;
SG_MUL_VAL_ 1418 Highest_sub_index_supported_0027 SubIndex_1401 0-0;
SG_MUL_VAL_ 1418 SubIndex_1401 Index 5121-5121;
SG_MUL_VAL_ 1418 TransmissionType_1400_02 SubIndex_1400 2-2;
SG_MUL_VAL_ 1418 COB_ID_1400_01 SubIndex_1400 1-1;
SG_MUL_VAL_ 1418 Highest_sub_index_supported_0028 SubIndex_1400 0-0;
SG_MUL_VAL_ 1418 SubIndex_1400 Index 5120-5120;
SG_MUL_VAL_ 1418 Serial_number_1018_04 SubIndex_1018 4-4;
SG_MUL_VAL_ 1418 Revision_number_1018_03 SubIndex_1018 3-3;
SG_MUL_VAL_ 1418 Product_Code_1018_02 SubIndex_1018 2-2;
SG_MUL_VAL_ 1418 Vendor_Id_1018_01 SubIndex_1018 1-1;
SG_MUL_VAL_ 1418 Highest_sub_index_supported_0029 SubIndex_1018 0-0;
SG_MUL_VAL_ 1418 SubIndex_1018 Index 4120-4120;
SG_MUL_VAL_ 1418 Producer_Heartbeat_Time_1017 SubIndex_1017 0-0;
SG_MUL_VAL_ 1418 SubIndex_1017 Index 4119-4119;
SG_MUL_VAL_ 1418 Consumer_Heartbeat_Time16_1_0003 SubIndex_1016 16-16;
SG_MUL_VAL_ 1418 Consumer_Heartbeat_Time15_1_0003 SubIndex_1016 15-15;
SG_MUL_VAL_ 1418 Consumer_Heartbeat_Time14_1_0003 SubIndex_1016 14-14;
SG_MUL_VAL_ 1418 Consumer_Heartbeat_Time13_1_0003 SubIndex_1016 13-13;
SG_MUL_VAL_ 1418 Consumer_Heartbeat_Time12_1_0003 SubIndex_1016 12-12;
SG_MUL_VAL_ 1418 Consumer_Heartbeat_Time11_1_0003 SubIndex_1016 11-11;
SG_MUL_VAL_ 1418 Consumer_Heartbeat_Time10_1_0003 SubIndex_1016 10-10;
SG_MUL_VAL_ 1418 Consumer_Heartbeat_Time9_1016_09 SubIndex_1016 9-9;
SG_MUL_VAL_ 1418 Consumer_Heartbeat_Time8_1016_08 SubIndex_1016 8-8;
SG_MUL_VAL_ 1418 Consumer_Heartbeat_Time7_1016_07 SubIndex_1016 7-7;
SG_MUL_VAL_ 1418 Consumer_Heartbeat_Time6_1016_06 SubIndex_1016 6-6;
SG_MUL_VAL_ 1418 Consumer_Heartbeat_Time5_1016_05 SubIndex_1016 5-5;
SG_MUL_VAL_ 1418 Consumer_Heartbeat_Time4_1016_04 SubIndex_1016 4-4;
SG_MUL_VAL_ 1418 Consumer_Heartbeat_Time3_1016_03 SubIndex_1016 3-3;
SG_MUL_VAL_ 1418 Consumer_Heartbeat_Time2_1016_02 SubIndex_1016 2-2;
SG_MUL_VAL_ 1418 Consumer_Heartbeat_Time1_1016_01 SubIndex_1016 1-1;
SG_MUL_VAL_ 1418 NrOfObjects_1016_00 SubIndex_1016 0-0;
SG_MUL_VAL_ 1418 SubIndex_1016 Index 4118-4118;
SG_MUL_VAL_ 1418 COB_ID_EMCY_1014 SubIndex_1014 0-0;
SG_MUL_VAL_ 1418 SubIndex_1014 Index 4116-4116;
SG_MUL_VAL_ 1418 Restore_all_Default_Paramet_0003 SubIndex_1011 1-1;
SG_MUL_VAL_ 1418 Highest_sub_index_supported_0030 SubIndex_1011 0-0;
SG_MUL_VAL_ 1418 SubIndex_1011 Index 4113-4113;
SG_MUL_VAL_ 1418 Save_all_Parameters_1010_01 SubIndex_1010 1-1;
SG_MUL_VAL_ 1418 Highest_sub_index_supported_0031 SubIndex_1010 0-0;
SG_MUL_VAL_ 1418 SubIndex_1010 Index 4112-4112;
SG_MUL_VAL_ 1418 Life_Time_Factor_100D SubIndex_100D 0-0;
SG_MUL_VAL_ 1418 SubIndex_100D Index 4109-4109;
SG_MUL_VAL_ 1418 Guard_Time_100C SubIndex_100C 0-0;
SG_MUL_VAL_ 1418 SubIndex_100C Index 4108-4108;
SG_MUL_VAL_ 1418 Synchronous_Window_Length_1007 SubIndex_1007 0-0;
SG_MUL_VAL_ 1418 SubIndex_1007 Index 4103-4103;
SG_MUL_VAL_ 1418 Communication_Cycle_Period_1006 SubIndex_1006 0-0;
SG_MUL_VAL_ 1418 SubIndex_1006 Index 4102-4102;
SG_MUL_VAL_ 1418 COB_ID_SYNC_1005 SubIndex_1005 0-0;
SG_MUL_VAL_ 1418 SubIndex_1005 Index 4101-4101;
SG_MUL_VAL_ 1418 Standard_error_field_1003_09 SubIndex_1003 9-9;
SG_MUL_VAL_ 1418 Standard_error_field_1003_08 SubIndex_1003 8-8;
SG_MUL_VAL_ 1418 Standard_error_field_1003_07 SubIndex_1003 7-7;
SG_MUL_VAL_ 1418 Standard_error_field_1003_06 SubIndex_1003 6-6;
SG_MUL_VAL_ 1418 Standard_error_field_1003_05 SubIndex_1003 5-5;
SG_MUL_VAL_ 1418 Standard_error_field_1003_04 SubIndex_1003 4-4;
SG_MUL_VAL_ 1418 Standard_error_field_1003_03 SubIndex_1003 3-3;
SG_MUL_VAL_ 1418 Standard_error_field_1003_02 SubIndex_1003 2-2;
SG_MUL_VAL_ 1418 Standard_error_field_1003_01 SubIndex_1003 1-1;
SG_MUL_VAL_ 1418 Number_of_Errors_1003_00 SubIndex_1003 0-0;
SG_MUL_VAL_ 1418 SubIndex_1003 Index 4099-4099;
SG_MUL_VAL_ 1418 Error_Register_1001 SubIndex_1001 0-0;
SG_MUL_VAL_ 1418 SubIndex_1001 Index 4097-4097;
SG_MUL_VAL_ 1418 Device_Type_1000 SubIndex_1000 0-0;
SG_MUL_VAL_ 1418 SubIndex_1000 Index 4096-4096;
SG_MUL_VAL_ 1418 Index TransferType 1-1;
SG_MUL_VAL_ 1418 TransferType SCS 1-2;
SG_MUL_VAL_ 1418 NotUsedBytes SCS 1-2;
SG_MUL_VAL_ 1418 SizeIndicator SCS 1-2;
SG_MUL_VAL_ 1546 Write_Output_32_Bit16_6320_10 SubIndex_6320 16-16;
SG_MUL_VAL_ 1546 Write_Output_32_Bit15_6320_0F SubIndex_6320 15-15;
SG_MUL_VAL_ 1546 Write_Output_32_Bit14_6320_0E SubIndex_6320 14-14;
SG_MUL_VAL_ 1546 Write_Output_32_Bit13_6320_0D SubIndex_6320 13-13;
SG_MUL_VAL_ 1546 Write_Output_32_Bit12_6320_0C SubIndex_6320 12-12;
SG_MUL_VAL_ 1546 Write_Output_32_Bit11_6320_0B SubIndex_6320 11-11;
SG_MUL_VAL_ 1546 Write_Output_32_Bit10_6320_0A SubIndex_6320 10-10;
SG_MUL_VAL_ 1546 Write_Output_32_Bit9_6320_09 SubIndex_6320 9-9;
SG_MUL_VAL_ 1546 Write_Output_32_Bit8_6320_08 SubIndex_6320 8-8;
SG_MUL_VAL_ 1546 Write_Output_32_Bit7_6320_07 SubIndex_6320 7-7;
SG_MUL_VAL_ 1546 Write_Output_32_Bit6_6320_06 SubIndex_6320 6-6;
SG_MUL_VAL_ 1546 Write_Output_32_Bit5_6320_05 SubIndex_6320 5-5;
SG_MUL_VAL_ 1546 Write_Output_32_Bit4_6320_04 SubIndex_6320 4-4;
SG_MUL_VAL_ 1546 Write_Output_32_Bit3_6320_03 SubIndex_6320 3-3;
SG_MUL_VAL_ 1546 Write_Output_32_Bit2_6320_02 SubIndex_6320 2-2;
SG_MUL_VAL_ 1546 Write_Output_32_Bit1_6320_01 SubIndex_6320 1-1;
SG_MUL_VAL_ 1546 NrOfObjects_6320_00 SubIndex_6320 0-0;
SG_MUL_VAL_ 1546 SubIndex_6320 Index 25376-25376;
SG_MUL_VAL_ 1546 Write_Output_16_Bit16_6300_10 SubIndex_6300 16-16;
SG_MUL_VAL_ 1546 Write_Output_16_Bit15_6300_0F SubIndex_6300 15-15;
SG_MUL_VAL_ 1546 Write_Output_16_Bit14_6300_0E SubIndex_6300 14-14;
SG_MUL_VAL_ 1546 Write_Output_16_Bit13_6300_0D SubIndex_6300 13-13;
SG_MUL_VAL_ 1546 Write_Output_16_Bit12_6300_0C SubIndex_6300 12-12;
SG_MUL_VAL_ 1546 Write_Output_16_Bit11_6300_0B SubIndex_6300 11-11;
SG_MUL_VAL_ 1546 Write_Output_16_Bit10_6300_0A SubIndex_6300 10-10;
SG_MUL_VAL_ 1546 Write_Output_16_Bit9_6300_09 SubIndex_6300 9-9;
SG_MUL_VAL_ 1546 Write_Output_16_Bit8_6300_08 SubIndex_6300 8-8;
SG_MUL_VAL_ 1546 Write_Output_16_Bit7_6300_07 SubIndex_6300 7-7;
SG_MUL_VAL_ 1546 Write_Output_16_Bit6_6300_06 SubIndex_6300 6-6;
SG_MUL_VAL_ 1546 Write_Output_16_Bit5_6300_05 SubIndex_6300 5-5;
SG_MUL_VAL_ 1546 Write_Output_16_Bit4_6300_04 SubIndex_6300 4-4;
SG_MUL_VAL_ 1546 Write_Output_16_Bit3_6300_03 SubIndex_6300 3-3;
SG_MUL_VAL_ 1546 Write_Output_16_Bit2_6300_02 SubIndex_6300 2-2;
SG_MUL_VAL_ 1546 Write_Output_16_Bit1_6300_01 SubIndex_6300 1-1;
SG_MUL_VAL_ 1546 NrOfObjects_6300_00 SubIndex_6300 0-0;
SG_MUL_VAL_ 1546 SubIndex_6300 Index 25344-25344;
SG_MUL_VAL_ 1546 Write_Output_1_Bit64_6220_40 SubIndex_6220 64-64;
SG_MUL_VAL_ 1546 Write_Output_1_Bit63_6220_3F SubIndex_6220 63-63;
SG_MUL_VAL_ 1546 Write_Output_1_Bit62_6220_3E SubIndex_6220 62-62;
SG_MUL_VAL_ 1546 Write_Output_1_Bit61_6220_3D SubIndex_6220 61-61;
SG_MUL_VAL_ 1546 Write_Output_1_Bit60_6220_3C SubIndex_6220 60-60;
SG_MUL_VAL_ 1546 Write_Output_1_Bit59_6220_3B SubIndex_6220 59-59;
SG_MUL_VAL_ 1546 Write_Output_1_Bit58_6220_3A SubIndex_6220 58-58;
SG_MUL_VAL_ 1546 Write_Output_1_Bit57_6220_39 SubIndex_6220 57-57;
SG_MUL_VAL_ 1546 Write_Output_1_Bit56_6220_38 SubIndex_6220 56-56;
SG_MUL_VAL_ 1546 Write_Output_1_Bit55_6220_37 SubIndex_6220 55-55;
SG_MUL_VAL_ 1546 Write_Output_1_Bit54_6220_36 SubIndex_6220 54-54;
SG_MUL_VAL_ 1546 Write_Output_1_Bit53_6220_35 SubIndex_6220 53-53;
SG_MUL_VAL_ 1546 Write_Output_1_Bit52_6220_34 SubIndex_6220 52-52;
SG_MUL_VAL_ 1546 Write_Output_1_Bit51_6220_33 SubIndex_6220 51-51;
SG_MUL_VAL_ 1546 Write_Output_1_Bit50_6220_32 SubIndex_6220 50-50;
SG_MUL_VAL_ 1546 Write_Output_1_Bit49_6220_31 SubIndex_6220 49-49;
SG_MUL_VAL_ 1546 Write_Output_1_Bit48_6220_30 SubIndex_6220 48-48;
SG_MUL_VAL_ 1546 Write_Output_1_Bit47_6220_2F SubIndex_6220 47-47;
SG_MUL_VAL_ 1546 Write_Output_1_Bit46_6220_2E SubIndex_6220 46-46;
SG_MUL_VAL_ 1546 Write_Output_1_Bit45_6220_2D SubIndex_6220 45-45;
SG_MUL_VAL_ 1546 Write_Output_1_Bit44_6220_2C SubIndex_6220 44-44;
SG_MUL_VAL_ 1546 Write_Output_1_Bit43_6220_2B SubIndex_6220 43-43;
SG_MUL_VAL_ 1546 Write_Output_1_Bit42_6220_2A SubIndex_6220 42-42;
SG_MUL_VAL_ 1546 Write_Output_1_Bit41_6220_29 SubIndex_6220 41-41;
SG_MUL_VAL_ 1546 Write_Output_1_Bit40_6220_28 SubIndex_6220 40-40;
SG_MUL_VAL_ 1546 Write_Output_1_Bit39_6220_27 SubIndex_6220 39-39;
SG_MUL_VAL_ 1546 Write_Output_1_Bit38_6220_26 SubIndex_6220 38-38;
SG_MUL_VAL_ 1546 Write_Output_1_Bit37_6220_25 SubIndex_6220 37-37;
SG_MUL_VAL_ 1546 Write_Output_1_Bit36_6220_24 SubIndex_6220 36-36;
SG_MUL_VAL_ 1546 Write_Output_1_Bit35_6220_23 SubIndex_6220 35-35;
SG_MUL_VAL_ 1546 Write_Output_1_Bit34_6220_22 SubIndex_6220 34-34;
SG_MUL_VAL_ 1546 Write_Output_1_Bit33_6220_21 SubIndex_6220 33-33;
SG_MUL_VAL_ 1546 Write_Output_1_Bit32_6220_20 SubIndex_6220 32-32;
SG_MUL_VAL_ 1546 Write_Output_1_Bit31_6220_1F SubIndex_6220 31-31;
SG_MUL_VAL_ 1546 Write_Output_1_Bit30_6220_1E SubIndex_6220 30-30;
SG_MUL_VAL_ 1546 Write_Output_1_Bit29_6220_1D SubIndex_6220 29-29;
SG_MUL_VAL_ 1546 Write_Output_1_Bit28_6220_1C SubIndex_6220 28-28;
SG_MUL_VAL_ 1546 Write_Output_1_Bit27_6220_1B SubIndex_6220 27-27;
SG_MUL_VAL_ 1546 Write_Output_1_Bit26_6220_1A SubIndex_6220 26-26;
SG_MUL_VAL_ 1546 Write_Output_1_Bit25_6220_19 SubIndex_6220 25-25;
SG_MUL_VAL_ 1546 Write_Output_1_Bit24_6220_18 SubIndex_6220 24-24;
SG_MUL_VAL_ 1546 Write_Output_1_Bit23_6220_17 SubIndex_6220 23-23;
SG_MUL_VAL_ 1546 Write_Output_1_Bit22_6220_16 SubIndex_6220 22-22;
SG_MUL_VAL_ 1546 Write_Output_1_Bit21_6220_15 SubIndex_6220 21-21;
SG_MUL_VAL_ 1546 Write_Output_1_Bit20_6220_14 SubIndex_6220 20-20;
SG_MUL_VAL_ 1546 Write_Output_1_Bit19_6220_13 SubIndex_6220 19-19;
SG_MUL_VAL_ 1546 Write_Output_1_Bit18_6220_12 SubIndex_6220 18-18;
SG_MUL_VAL_ 1546 Write_Output_1_Bit17_6220_11 SubIndex_6220 17-17;
SG_MUL_VAL_ 1546 Write_Output_1_Bit16_6220_10 SubIndex_6220 16-16;
SG_MUL_VAL_ 1546 Write_Output_1_Bit15_6220_0F SubIndex_6220 15-15;
SG_MUL_VAL_ 1546 Write_Output_1_Bit14_6220_0E SubIndex_6220 14-14;
SG_MUL_VAL_ 1546 Write_Output_1_Bit13_6220_0D SubIndex_6220 13-13;
SG_MUL_VAL_ 1546 Write_Output_1_Bit12_6220_0C SubIndex_6220 12-12;
SG_MUL_VAL_ 1546 Write_Output_1_Bit11_6220_0B SubIndex_6220 11-11;
SG_MUL_VAL_ 1546 Write_Output_1_Bit10_6220_0A SubIndex_6220 10-10;
SG_MUL_VAL_ 1546 Write_Output_1_Bit9_6220_09 SubIndex_6220 9-9;
SG_MUL_VAL_ 1546 Write_Output_1_Bit8_6220_08 SubIndex_6220 8-8;
SG_MUL_VAL_ 1546 Write_Output_1_Bit7_6220_07 SubIndex_6220 7-7;
SG_MUL_VAL_ 1546 Write_Output_1_Bit6_6220_06 SubIndex_6220 6-6;
SG_MUL_VAL_ 1546 Write_Output_1_Bit5_6220_05 SubIndex_6220 5-5;
SG_MUL_VAL_ 1546 Write_Output_1_Bit4_6220_04 SubIndex_6220 4-4;
SG_MUL_VAL_ 1546 Write_Output_1_Bit3_6220_03 SubIndex_6220 3-3;
SG_MUL_VAL_ 1546 Write_Output_1_Bit2_6220_02 SubIndex_6220 2-2;
SG_MUL_VAL_ 1546 Write_Output_1_Bit1_6220_01 SubIndex_6220 1-1;
SG_MUL_VAL_ 1546 NrOfObjects_6220_00 SubIndex_6220 0-0;
SG_MUL_VAL_ 1546 SubIndex_6220 Index 25120-25120;
SG_MUL_VAL_ 1546 Write_Output_8_Bit16_6200_10 SubIndex_6200 16-16;
SG_MUL_VAL_ 1546 Write_Output_8_Bit15_6200_0F SubIndex_6200 15-15;
SG_MUL_VAL_ 1546 Write_Output_8_Bit14_6200_0E SubIndex_6200 14-14;
SG_MUL_VAL_ 1546 Write_Output_8_Bit13_6200_0D SubIndex_6200 13-13;
SG_MUL_VAL_ 1546 Write_Output_8_Bit12_6200_0C SubIndex_6200 12-12;
SG_MUL_VAL_ 1546 Write_Output_8_Bit11_6200_0B SubIndex_6200 11-11;
SG_MUL_VAL_ 1546 Write_Output_8_Bit10_6200_0A SubIndex_6200 10-10;
SG_MUL_VAL_ 1546 Write_Output_8_Bit9_6200_09 SubIndex_6200 9-9;
SG_MUL_VAL_ 1546 Write_Output_8_Bit8_6200_08 SubIndex_6200 8-8;
SG_MUL_VAL_ 1546 Write_Output_8_Bit7_6200_07 SubIndex_6200 7-7;
SG_MUL_VAL_ 1546 Write_Output_8_Bit6_6200_06 SubIndex_6200 6-6;
SG_MUL_VAL_ 1546 Write_Output_8_Bit5_6200_05 SubIndex_6200 5-5;
SG_MUL_VAL_ 1546 Write_Output_8_Bit4_6200_04 SubIndex_6200 4-4;
SG_MUL_VAL_ 1546 Write_Output_8_Bit3_6200_03 SubIndex_6200 3-3;
SG_MUL_VAL_ 1546 Write_Output_8_Bit2_6200_02 SubIndex_6200 2-2;
SG_MUL_VAL_ 1546 Write_Output_8_Bit1_6200_01 SubIndex_6200 1-1;
SG_MUL_VAL_ 1546 NrOfObjects_6200_00 SubIndex_6200 0-0;
SG_MUL_VAL_ 1546 SubIndex_6200 Index 25088-25088;
SG_MUL_VAL_ 1546 Read_Input_32_Bit16_6120_10 SubIndex_6120 16-16;
SG_MUL_VAL_ 1546 Read_Input_32_Bit15_6120_0F SubIndex_6120 15-15;
SG_MUL_VAL_ 1546 Read_Input_32_Bit14_6120_0E SubIndex_6120 14-14;
SG_MUL_VAL_ 1546 Read_Input_32_Bit13_6120_0D SubIndex_6120 13-13;
SG_MUL_VAL_ 1546 Read_Input_32_Bit12_6120_0C SubIndex_6120 12-12;
SG_MUL_VAL_ 1546 Read_Input_32_Bit11_6120_0B SubIndex_6120 11-11;
SG_MUL_VAL_ 1546 Read_Input_32_Bit10_6120_0A SubIndex_6120 10-10;
SG_MUL_VAL_ 1546 Read_Input_32_Bit9_6120_09 SubIndex_6120 9-9;
SG_MUL_VAL_ 1546 Read_Input_32_Bit8_6120_08 SubIndex_6120 8-8;
SG_MUL_VAL_ 1546 Read_Input_32_Bit7_6120_07 SubIndex_6120 7-7;
SG_MUL_VAL_ 1546 Read_Input_32_Bit6_6120_06 SubIndex_6120 6-6;
SG_MUL_VAL_ 1546 Read_Input_32_Bit5_6120_05 SubIndex_6120 5-5;
SG_MUL_VAL_ 1546 Read_Input_32_Bit4_6120_04 SubIndex_6120 4-4;
SG_MUL_VAL_ 1546 Read_Input_32_Bit3_6120_03 SubIndex_6120 3-3;
SG_MUL_VAL_ 1546 Read_Input_32_Bit2_6120_02 SubIndex_6120 2-2;
SG_MUL_VAL_ 1546 Read_Input_32_Bit1_6120_01 SubIndex_6120 1-1;
SG_MUL_VAL_ 1546 NrOfObjects_6120_00 SubIndex_6120 0-0;
SG_MUL_VAL_ 1546 SubIndex_6120 Index 24864-24864;
SG_MUL_VAL_ 1546 Read_Input_16_Bit16_6100_10 SubIndex_6100 16-16;
SG_MUL_VAL_ 1546 Read_Input_16_Bit15_6100_0F SubIndex_6100 15-15;
SG_MUL_VAL_ 1546 Read_Input_16_Bit14_6100_0E SubIndex_6100 14-14;
SG_MUL_VAL_ 1546 Read_Input_16_Bit13_6100_0D SubIndex_6100 13-13;
SG_MUL_VAL_ 1546 Read_Input_16_Bit12_6100_0C SubIndex_6100 12-12;
SG_MUL_VAL_ 1546 Read_Input_16_Bit11_6100_0B SubIndex_6100 11-11;
SG_MUL_VAL_ 1546 Read_Input_16_Bit10_6100_0A SubIndex_6100 10-10;
SG_MUL_VAL_ 1546 Read_Input_16_Bit9_6100_09 SubIndex_6100 9-9;
SG_MUL_VAL_ 1546 Read_Input_16_Bit8_6100_08 SubIndex_6100 8-8;
SG_MUL_VAL_ 1546 Read_Input_16_Bit7_6100_07 SubIndex_6100 7-7;
SG_MUL_VAL_ 1546 Read_Input_16_Bit6_6100_06 SubIndex_6100 6-6;
SG_MUL_VAL_ 1546 Read_Input_16_Bit5_6100_05 SubIndex_6100 5-5;
SG_MUL_VAL_ 1546 Read_Input_16_Bit4_6100_04 SubIndex_6100 4-4;
SG_MUL_VAL_ 1546 Read_Input_16_Bit3_6100_03 SubIndex_6100 3-3;
SG_MUL_VAL_ 1546 Read_Input_16_Bit2_6100_02 SubIndex_6100 2-2;
SG_MUL_VAL_ 1546 Read_Input_16_Bit1_6100_01 SubIndex_6100 1-1;
SG_MUL_VAL_ 1546 NrOfObjects_6100_00 SubIndex_6100 0-0;
SG_MUL_VAL_ 1546 SubIndex_6100 Index 24832-24832;
SG_MUL_VAL_ 1546 Read_Input_1_Bit64_6020_40 SubIndex_6020 64-64;
SG_MUL_VAL_ 1546 Read_Input_1_Bit63_6020_3F SubIndex_6020 63-63;
SG_MUL_VAL_ 1546 Read_Input_1_Bit62_6020_3E SubIndex_6020 62-62;
SG_MUL_VAL_ 1546 Read_Input_1_Bit61_6020_3D SubIndex_6020 61-61;
SG_MUL_VAL_ 1546 Read_Input_1_Bit60_6020_3C SubIndex_6020 60-60;
SG_MUL_VAL_ 1546 Read_Input_1_Bit59_6020_3B SubIndex_6020 59-59;
SG_MUL_VAL_ 1546 Read_Input_1_Bit58_6020_3A SubIndex_6020 58-58;
SG_MUL_VAL_ 1546 Read_Input_1_Bit57_6020_39 SubIndex_6020 57-57;
SG_MUL_VAL_ 1546 Read_Input_1_Bit56_6020_38 SubIndex_6020 56-56;
SG_MUL_VAL_ 1546 Read_Input_1_Bit55_6020_37 SubIndex_6020 55-55;
SG_MUL_VAL_ 1546 Read_Input_1_Bit54_6020_36 SubIndex_6020 54-54;
SG_MUL_VAL_ 1546 Read_Input_1_Bit53_6020_35 SubIndex_6020 53-53;
SG_MUL_VAL_ 1546 Read_Input_1_Bit52_6020_34 SubIndex_6020 52-52;
SG_MUL_VAL_ 1546 Read_Input_1_Bit51_6020_33 SubIndex_6020 51-51;
SG_MUL_VAL_ 1546 Read_Input_1_Bit50_6020_32 SubIndex_6020 50-50;
SG_MUL_VAL_ 1546 Read_Input_1_Bit49_6020_31 SubIndex_6020 49-49;
SG_MUL_VAL_ 1546 Read_Input_1_Bit48_6020_30 SubIndex_6020 48-48;
SG_MUL_VAL_ 1546 Read_Input_1_Bit47_6020_2F SubIndex_6020 47-47;
SG_MUL_VAL_ 1546 Read_Input_1_Bit46_6020_2E SubIndex_6020 46-46;
SG_MUL_VAL_ 1546 Read_Input_1_Bit45_6020_2D SubIndex_6020 45-45;
SG_MUL_VAL_ 1546 Read_Input_1_Bit44_6020_2C SubIndex_6020 44-44;
SG_MUL_VAL_ 1546 Read_Input_1_Bit43_6020_2B SubIndex_6020 43-43;
SG_MUL_VAL_ 1546 Read_Input_1_Bit42_6020_2A SubIndex_6020 42-42;
SG_MUL_VAL_ 1546 Read_Input_1_Bit41_6020_29 SubIndex_6020 41-41;
SG_MUL_VAL_ 1546 Read_Input_1_Bit40_6020_28 SubIndex_6020 40-40;
SG_MUL_VAL_ 1546 Read_Input_1_Bit39_6020_27 SubIndex_6020 39-39;
SG_MUL_VAL_ 1546 Read_Input_1_Bit38_6020_26 SubIndex_6020 38-38;
SG_MUL_VAL_ 1546 Read_Input_1_Bit37_6020_25 SubIndex_6020 37-37;
SG_MUL_VAL_ 1546 Read_Input_1_Bit36_6020_24 SubIndex_6020 36-36;
SG_MUL_VAL_ 1546 Read_Input_1_Bit35_6020_23 SubIndex_6020 35-35;
SG_MUL_VAL_ 1546 Read_Input_1_Bit34_6020_22 SubIndex_6020 34-34;
SG_MUL_VAL_ 1546 Read_Input_1_Bit33_6020_21 SubIndex_6020 33-33;
SG_MUL_VAL_ 1546 Read_Input_1_Bit32_6020_20 SubIndex_6020 32-32;
SG_MUL_VAL_ 1546 Read_Input_1_Bit31_6020_1F SubIndex_6020 31-31;
SG_MUL_VAL_ 1546 Read_Input_1_Bit30_6020_1E SubIndex_6020 30-30;
SG_MUL_VAL_ 1546 Read_Input_1_Bit29_6020_1D SubIndex_6020 29-29;
SG_MUL_VAL_ 1546 Read_Input_1_Bit28_6020_1C SubIndex_6020 28-28;
SG_MUL_VAL_ 1546 Read_Input_1_Bit27_6020_1B SubIndex_6020 27-27;
SG_MUL_VAL_ 1546 Read_Input_1_Bit26_6020_1A SubIndex_6020 26-26;
SG_MUL_VAL_ 1546 Read_Input_1_Bit25_6020_19 SubIndex_6020 25-25;
SG_MUL_VAL_ 1546 Read_Input_1_Bit24_6020_18 SubIndex_6020 24-24;
SG_MUL_VAL_ 1546 Read_Input_1_Bit23_6020_17 SubIndex_6020 23-23;
SG_MUL_VAL_ 1546 Read_Input_1_Bit22_6020_16 SubIndex_6020 22-22;
SG_MUL_VAL_ 1546 Read_Input_1_Bit21_6020_15 SubIndex_6020 21-21;
SG_MUL_VAL_ 1546 Read_Input_1_Bit20_6020_14 SubIndex_6020 20-20;
SG_MUL_VAL_ 1546 Read_Input_1_Bit19_6020_13 SubIndex_6020 19-19;
SG_MUL_VAL_ 1546 Read_Input_1_Bit18_6020_12 SubIndex_6020 18-18;
SG_MUL_VAL_ 1546 Read_Input_1_Bit17_6020_11 SubIndex_6020 17-17;
SG_MUL_VAL_ 1546 Read_Input_1_Bit16_6020_10 SubIndex_6020 16-16;
SG_MUL_VAL_ 1546 Read_Input_1_Bit15_6020_0F SubIndex_6020 15-15;
SG_MUL_VAL_ 1546 Read_Input_1_Bit14_6020_0E SubIndex_6020 14-14;
SG_MUL_VAL_ 1546 Read_Input_1_Bit13_6020_0D SubIndex_6020 13-13;
SG_MUL_VAL_ 1546 Read_Input_1_Bit12_6020_0C SubIndex_6020 12-12;
SG_MUL_VAL_ 1546 Read_Input_1_Bit11_6020_0B SubIndex_6020 11-11;
SG_MUL_VAL_ 1546 Read_Input_1_Bit10_6020_0A SubIndex_6020 10-10;
SG_MUL_VAL_ 1546 Read_Input_1_Bit9_6020_09 SubIndex_6020 9-9;
SG_MUL_VAL_ 1546 Read_Input_1_Bit8_6020_08 SubIndex_6020 8-8;
SG_MUL_VAL_ 1546 Read_Input_1_Bit7_6020_07 SubIndex_6020 7-7;
SG_MUL_VAL_ 1546 Read_Input_1_Bit6_6020_06 SubIndex_6020 6-6;
SG_MUL_VAL_ 1546 Read_Input_1_Bit5_6020_05 SubIndex_6020 5-5;
SG_MUL_VAL_ 1546 Read_Input_1_Bit4_6020_04 SubIndex_6020 4-4;
SG_MUL_VAL_ 1546 Read_Input_1_Bit3_6020_03 SubIndex_6020 3-3;
SG_MUL_VAL_ 1546 Read_Input_1_Bit2_6020_02 SubIndex_6020 2-2;
SG_MUL_VAL_ 1546 Read_Input_1_Bit1_6020_01 SubIndex_6020 1-1;
SG_MUL_VAL_ 1546 NrOfObjects_6020_00 SubIndex_6020 0-0;
SG_MUL_VAL_ 1546 SubIndex_6020 Index 24608-24608;
SG_MUL_VAL_ 1546 Read_Input_8_Bit16_6000_10 SubIndex_6000 16-16;
SG_MUL_VAL_ 1546 Read_Input_8_Bit15_6000_0F SubIndex_6000 15-15;
SG_MUL_VAL_ 1546 Read_Input_8_Bit14_6000_0E SubIndex_6000 14-14;
SG_MUL_VAL_ 1546 Read_Input_8_Bit13_6000_0D SubIndex_6000 13-13;
SG_MUL_VAL_ 1546 Read_Input_8_Bit12_6000_0C SubIndex_6000 12-12;
SG_MUL_VAL_ 1546 Read_Input_8_Bit11_6000_0B SubIndex_6000 11-11;
SG_MUL_VAL_ 1546 Read_Input_8_Bit10_6000_0A SubIndex_6000 10-10;
SG_MUL_VAL_ 1546 Read_Input_8_Bit9_6000_09 SubIndex_6000 9-9;
SG_MUL_VAL_ 1546 Read_Input_8_Bit8_6000_08 SubIndex_6000 8-8;
SG_MUL_VAL_ 1546 Read_Input_8_Bit7_6000_07 SubIndex_6000 7-7;
SG_MUL_VAL_ 1546 Read_Input_8_Bit6_6000_06 SubIndex_6000 6-6;
SG_MUL_VAL_ 1546 Read_Input_8_Bit5_6000_05 SubIndex_6000 5-5;
SG_MUL_VAL_ 1546 Read_Input_8_Bit4_6000_04 SubIndex_6000 4-4;
SG_MUL_VAL_ 1546 Read_Input_8_Bit3_6000_03 SubIndex_6000 3-3;
SG_MUL_VAL_ 1546 Read_Input_8_Bit2_6000_02 SubIndex_6000 2-2;
SG_MUL_VAL_ 1546 Read_Input_8_Bit1_6000_01 SubIndex_6000 1-1;
SG_MUL_VAL_ 1546 NrOfObjects_6000_00 SubIndex_6000 0-0;
SG_MUL_VAL_ 1546 SubIndex_6000 Index 24576-24576;
SG_MUL_VAL_ 1546 NrOfObjects_2300_00 SubIndex_2300 0-0;
SG_MUL_VAL_ 1546 SubIndex_2300 Index 8960-8960;
SG_MUL_VAL_ 1546 NrOfObjects_2200_00 SubIndex_2200 0-0;
SG_MUL_VAL_ 1546 SubIndex_2200 Index 8704-8704;
SG_MUL_VAL_ 1546 NrOfMappedObjects_1A03_00 SubIndex_1A03 0-0;
SG_MUL_VAL_ 1546 SubIndex_1A03 Index 6659-6659;
SG_MUL_VAL_ 1546 NrOfMappedObjects_1A02_00 SubIndex_1A02 0-0;
SG_MUL_VAL_ 1546 SubIndex_1A02 Index 6658-6658;
SG_MUL_VAL_ 1546 mappedObj2_1A01_02 SubIndex_1A01 2-2;
SG_MUL_VAL_ 1546 mappedObj1_1A01_01 SubIndex_1A01 1-1;
SG_MUL_VAL_ 1546 NrOfMappedObjects_1A01_00 SubIndex_1A01 0-0;
SG_MUL_VAL_ 1546 SubIndex_1A01 Index 6657-6657;
SG_MUL_VAL_ 1546 mappedObj2_1A00_02 SubIndex_1A00 2-2;
SG_MUL_VAL_ 1546 mappedObj1_1A00_01 SubIndex_1A00 1-1;
SG_MUL_VAL_ 1546 NrOfMappedObjects_1A00_00 SubIndex_1A00 0-0;
SG_MUL_VAL_ 1546 SubIndex_1A00 Index 6656-6656;
SG_MUL_VAL_ 1546 EventTimer_1803_05 SubIndex_1803 5-5;
SG_MUL_VAL_ 1546 TransmissionType_1803_02 SubIndex_1803 2-2;
SG_MUL_VAL_ 1546 COB_ID_1803_01 SubIndex_1803 1-1;
SG_MUL_VAL_ 1546 Highest_sub_index_supported_0032 SubIndex_1803 0-0;
SG_MUL_VAL_ 1546 SubIndex_1803 Index 6147-6147;
SG_MUL_VAL_ 1546 EventTimer_1802_05 SubIndex_1802 5-5;
SG_MUL_VAL_ 1546 TransmissionType_1802_02 SubIndex_1802 2-2;
SG_MUL_VAL_ 1546 COB_ID_1802_01 SubIndex_1802 1-1;
SG_MUL_VAL_ 1546 Highest_sub_index_supported_0033 SubIndex_1802 0-0;
SG_MUL_VAL_ 1546 SubIndex_1802 Index 6146-6146;
SG_MUL_VAL_ 1546 EventTimer_1801_05 SubIndex_1801 5-5;
SG_MUL_VAL_ 1546 TransmissionType_1801_02 SubIndex_1801 2-2;
SG_MUL_VAL_ 1546 COB_ID_1801_01 SubIndex_1801 1-1;
SG_MUL_VAL_ 1546 Highest_sub_index_supported_0034 SubIndex_1801 0-0;
SG_MUL_VAL_ 1546 SubIndex_1801 Index 6145-6145;
SG_MUL_VAL_ 1546 EventTimer_1800_05 SubIndex_1800 5-5;
SG_MUL_VAL_ 1546 TransmissionType_1800_02 SubIndex_1800 2-2;
SG_MUL_VAL_ 1546 COB_ID_1800_01 SubIndex_1800 1-1;
SG_MUL_VAL_ 1546 Highest_sub_index_supported_0035 SubIndex_1800 0-0;
SG_MUL_VAL_ 1546 SubIndex_1800 Index 6144-6144;
SG_MUL_VAL_ 1546 NrOfMappedObjects_1603_00 SubIndex_1603 0-0;
SG_MUL_VAL_ 1546 SubIndex_1603 Index 5635-5635;
SG_MUL_VAL_ 1546 NrOfMappedObjects_1602_00 SubIndex_1602 0-0;
SG_MUL_VAL_ 1546 SubIndex_1602 Index 5634-5634;
SG_MUL_VAL_ 1546 NrOfMappedObjects_1601_00 SubIndex_1601 0-0;
SG_MUL_VAL_ 1546 SubIndex_1601 Index 5633-5633;
SG_MUL_VAL_ 1546 NrOfMappedObjects_1600_00 SubIndex_1600 0-0;
SG_MUL_VAL_ 1546 SubIndex_1600 Index 5632-5632;
SG_MUL_VAL_ 1546 TransmissionType_1403_02 SubIndex_1403 2-2;
SG_MUL_VAL_ 1546 COB_ID_1403_01 SubIndex_1403 1-1;
SG_MUL_VAL_ 1546 Highest_sub_index_supported_0036 SubIndex_1403 0-0;
SG_MUL_VAL_ 1546 SubIndex_1403 Index 5123-5123;
SG_MUL_VAL_ 1546 TransmissionType_1402_02 SubIndex_1402 2-2;
SG_MUL_VAL_ 1546 COB_ID_1402_01 SubIndex_1402 1-1;
SG_MUL_VAL_ 1546 Highest_sub_index_supported_0037 SubIndex_1402 0-0;
SG_MUL_VAL_ 1546 SubIndex_1402 Index 5122-5122;
SG_MUL_VAL_ 1546 TransmissionType_1401_02 SubIndex_1401 2-2;
SG_MUL_VAL_ 1546 COB_ID_1401_01 SubIndex_1401 1-1;
SG_MUL_VAL_ 1546 Highest_sub_index_supported_0038 SubIndex_1401 0-0;
SG_MUL_VAL_ 1546 SubIndex_1401 Index 5121-5121;
SG_MUL_VAL_ 1546 TransmissionType_1400_02 SubIndex_1400 2-2;
SG_MUL_VAL_ 1546 COB_ID_1400_01 SubIndex_1400 1-1;
SG_MUL_VAL_ 1546 Highest_sub_index_supported_0039 SubIndex_1400 0-0;
SG_MUL_VAL_ 1546 SubIndex_1400 Index 5120-5120;
SG_MUL_VAL_ 1546 Serial_number_1018_04 SubIndex_1018 4-4;
SG_MUL_VAL_ 1546 Revision_number_1018_03 SubIndex_1018 3-3;
SG_MUL_VAL_ 1546 Product_Code_1018_02 SubIndex_1018 2-2;
SG_MUL_VAL_ 1546 Vendor_Id_1018_01 SubIndex_1018 1-1;
SG_MUL_VAL_ 1546 Highest_sub_index_supported_0040 SubIndex_1018 0-0;
SG_MUL_VAL_ 1546 SubIndex_1018 Index 4120-4120;
SG_MUL_VAL_ 1546 Producer_Heartbeat_Time_1017 SubIndex_1017 0-0;
SG_MUL_VAL_ 1546 SubIndex_1017 Index 4119-4119;
SG_MUL_VAL_ 1546 Consumer_Heartbeat_Time16_1_0004 SubIndex_1016 16-16;
SG_MUL_VAL_ 1546 Consumer_Heartbeat_Time15_1_0004 SubIndex_1016 15-15;
SG_MUL_VAL_ 1546 Consumer_Heartbeat_Time14_1_0004 SubIndex_1016 14-14;
SG_MUL_VAL_ 1546 Consumer_Heartbeat_Time13_1_0004 SubIndex_1016 13-13;
SG_MUL_VAL_ 1546 Consumer_Heartbeat_Time12_1_0004 SubIndex_1016 12-12;
SG_MUL_VAL_ 1546 Consumer_Heartbeat_Time11_1_0004 SubIndex_1016 11-11;
SG_MUL_VAL_ 1546 Consumer_Heartbeat_Time10_1_0004 SubIndex_1016 10-10;
SG_MUL_VAL_ 1546 Consumer_Heartbeat_Time9_1016_09 SubIndex_1016 9-9;
SG_MUL_VAL_ 1546 Consumer_Heartbeat_Time8_1016_08 SubIndex_1016 8-8;
SG_MUL_VAL_ 1546 Consumer_Heartbeat_Time7_1016_07 SubIndex_1016 7-7;
SG_MUL_VAL_ 1546 Consumer_Heartbeat_Time6_1016_06 SubIndex_1016 6-6;
SG_MUL_VAL_ 1546 Consumer_Heartbeat_Time5_1016_05 SubIndex_1016 5-5;
SG_MUL_VAL_ 1546 Consumer_Heartbeat_Time4_1016_04 SubIndex_1016 4-4;
SG_MUL_VAL_ 1546 Consumer_Heartbeat_Time3_1016_03 SubIndex_1016 3-3;
SG_MUL_VAL_ 1546 Consumer_Heartbeat_Time2_1016_02 SubIndex_1016 2-2;
SG_MUL_VAL_ 1546 Consumer_Heartbeat_Time1_1016_01 SubIndex_1016 1-1;
SG_MUL_VAL_ 1546 NrOfObjects_1016_00 SubIndex_1016 0-0;
SG_MUL_VAL_ 1546 SubIndex_1016 Index 4118-4118;
SG_MUL_VAL_ 1546 COB_ID_EMCY_1014 SubIndex_1014 0-0;
SG_MUL_VAL_ 1546 SubIndex_1014 Index 4116-4116;
SG_MUL_VAL_ 1546 Restore_all_Default_Paramet_0004 SubIndex_1011 1-1;
SG_MUL_VAL_ 1546 Highest_sub_index_supported_0041 SubIndex_1011 0-0;
SG_MUL_VAL_ 1546 SubIndex_1011 Index 4113-4113;
SG_MUL_VAL_ 1546 Save_all_Parameters_1010_01 SubIndex_1010 1-1;
SG_MUL_VAL_ 1546 Highest_sub_index_supported_0042 SubIndex_1010 0-0;
SG_MUL_VAL_ 1546 SubIndex_1010 Index 4112-4112;
SG_MUL_VAL_ 1546 Life_Time_Factor_100D SubIndex_100D 0-0;
SG_MUL_VAL_ 1546 SubIndex_100D Index 4109-4109;
SG_MUL_VAL_ 1546 Guard_Time_100C SubIndex_100C 0-0;
SG_MUL_VAL_ 1546 SubIndex_100C Index 4108-4108;
SG_MUL_VAL_ 1546 Synchronous_Window_Length_1007 SubIndex_1007 0-0;
SG_MUL_VAL_ 1546 SubIndex_1007 Index 4103-4103;
SG_MUL_VAL_ 1546 Communication_Cycle_Period_1006 SubIndex_1006 0-0;
SG_MUL_VAL_ 1546 SubIndex_1006 Index 4102-4102;
SG_MUL_VAL_ 1546 COB_ID_SYNC_1005 SubIndex_1005 0-0;
SG_MUL_VAL_ 1546 SubIndex_1005 Index 4101-4101;
SG_MUL_VAL_ 1546 Standard_error_field_1003_09 SubIndex_1003 9-9;
SG_MUL_VAL_ 1546 Standard_error_field_1003_08 SubIndex_1003 8-8;
SG_MUL_VAL_ 1546 Standard_error_field_1003_07 SubIndex_1003 7-7;
SG_MUL_VAL_ 1546 Standard_error_field_1003_06 SubIndex_1003 6-6;
SG_MUL_VAL_ 1546 Standard_error_field_1003_05 SubIndex_1003 5-5;
SG_MUL_VAL_ 1546 Standard_error_field_1003_04 SubIndex_1003 4-4;
SG_MUL_VAL_ 1546 Standard_error_field_1003_03 SubIndex_1003 3-3;
SG_MUL_VAL_ 1546 Standard_error_field_1003_02 SubIndex_1003 2-2;
SG_MUL_VAL_ 1546 Standard_error_field_1003_01 SubIndex_1003 1-1;
SG_MUL_VAL_ 1546 Number_of_Errors_1003_00 SubIndex_1003 0-0;
SG_MUL_VAL_ 1546 SubIndex_1003 Index 4099-4099;
SG_MUL_VAL_ 1546 Error_Register_1001 SubIndex_1001 0-0;
SG_MUL_VAL_ 1546 SubIndex_1001 Index 4097-4097;
SG_MUL_VAL_ 1546 Device_Type_1000 SubIndex_1000 0-0;
SG_MUL_VAL_ 1546 SubIndex_1000 Index 4096-4096;
SG_MUL_VAL_ 1546 Index TransferType 1-1;
SG_MUL_VAL_ 1546 TransferType CCS 1-2;
SG_MUL_VAL_ 1546 NotUsedBytes CCS 1-2;
SG_MUL_VAL_ 1546 SizeIndicator CCS 1-2;
